VERSION ""

NS_ :

BS_:

BU_: CHUD_LS VKM_LS RCRM_LS MSM_RR_LS MSM_LR_LS CGM_LS BSM_LS VPM_LS ISRVM_LS DCAC_LS TouchPad_LS RSC_LS LVMPC_LS EOCM2B_K1_LS EOCM2A_K1_LS LCM_LS TIM_B_LS V2V_LS TCP_LS CSM_LS EOCM2B_K2_LS EOCM2A_K2_LS TIM_A_LS LVMNav_LS HFP_LS EDI_LS ARB_LS RSE_LS Dummy_LS VIS2_LS ICS_LS FCM_LS EOCM_F_LS VICM_LS AGC_LS MSM_P_LS OTIM_LS HVSM_R_LS HVSM_F_LS DVB_T_LS SBZA_R_LS PSD_R_LS PSD_L_LS UHP_Low UPA_LS STC_LS SBZA_L_LS PTM_LS ONSTAR_LS APA_LS TestTool_LS PHS_LS PDIM_LS CHM_LS RSA_LS AMP_LS HUD_LS MSM_LS HBSM_LS SCL_LS ECC_LS RadioHead_LS PEPS_LS IPC_LS AOS_LS SDM_LS TIM_LS BCM_LS

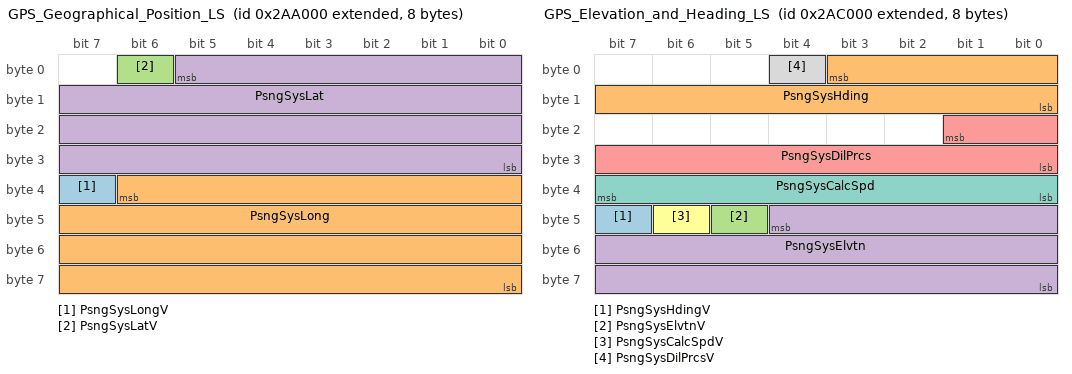
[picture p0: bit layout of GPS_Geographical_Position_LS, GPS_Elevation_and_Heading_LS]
BO_ 2150277120 GPS_Geographical_Position_LS: 8 RadioHead_LS
 SG_ PsngSysLongV : 39|1@0+ (1,0) [0|1] ""  VKM_LS,V2V_LS,VIS2_LS,RadioHead_LS,EDI_LS,VICM_LS,FCM_LS,ECC_LS,SBZA_R_LS,EOCM_F_LS,BCM_LS,SBZA_L_LS
 SG_ PsngSysLong : 38|31@0- (1,0) [-1073741824|1073741823] "ms arc"  VKM_LS,V2V_LS,VIS2_LS,RadioHead_LS,EDI_LS,VICM_LS,FCM_LS,ECC_LS,SBZA_R_LS,EOCM_F_LS,BCM_LS,SBZA_L_LS
 SG_ PsngSysLatV : 6|1@0+ (1,0) [0|1] ""  VKM_LS,V2V_LS,VIS2_LS,RadioHead_LS,VICM_LS,EDI_LS,FCM_LS,ECC_LS,SBZA_R_LS,EOCM_F_LS,BCM_LS,SBZA_L_LS
 SG_ PsngSysLat : 5|30@0- (1,0) [-536870912|536870911] "ms arc"  VKM_LS,V2V_LS,VIS2_LS,EDI_LS,RadioHead_LS,VICM_LS,FCM_LS,ECC_LS,SBZA_R_LS,EOCM_F_LS,BCM_LS,SBZA_L_LS

BO_ 2150285312 GPS_Elevation_and_Heading_LS: 8 RadioHead_LS
 SG_ PsngSysHdingV : 47|1@0+ (1,0) [0|1] ""  V2V_LS,FCM_LS,EDI_LS,RadioHead_LS,ECC_LS,SBZA_R_LS,EOCM_F_LS,BCM_LS,SBZA_L_LS
 SG_ PsngSysHding : 3|12@0+ (0.1,0) [0|409.5] "deg"  V2V_LS,FCM_LS,EDI_LS,RadioHead_LS,ECC_LS,SBZA_R_LS,EOCM_F_LS,BCM_LS,SBZA_L_LS
 SG_ PsngSysElvtnV : 45|1@0+ (1,0) [0|1] ""  BSM_LS,V2V_LS,VICM_LS,EDI_LS,RadioHead_LS,ECC_LS,SBZA_R_LS,EOCM_F_LS,BCM_LS,SBZA_L_LS
 SG_ PsngSysElvtn : 44|21@0+ (1,-100000) [-100000|1997151] "cm"  BSM_LS,V2V_LS,VICM_LS,EDI_LS,RadioHead_LS,ECC_LS,SBZA_R_LS,EOCM_F_LS,BCM_LS,SBZA_L_LS
 SG_ PsngSysDilPrcs : 17|10@0+ (0.1,0) [0|102.3] ""  V2V_LS,VICM_LS,EDI_LS,RadioHead_LS,SBZA_R_LS,EOCM_F_LS,BCM_LS,SBZA_L_LS
 SG_ PsngSysCalcSpdV : 46|1@0+ (1,0) [0|1] ""  V2V_LS,VICM_LS,EDI_LS,RadioHead_LS,EOCM_F_LS,SBZA_R_LS,SBZA_L_LS
 SG_ PsngSysCalcSpd : 39|8@0+ (1,0) [0|255] "km / h"  V2V_LS,VICM_LS,EDI_LS,RadioHead_LS,EOCM_F_LS,SBZA_R_LS,SBZA_L_LS
 SG_ PsngSysDilPrcsV : 4|1@0+ (1,0) [0|1] ""  V2V_LS,VICM_LS,EDI_LS,RadioHead_LS,SBZA_R_LS,EOCM_F_LS,BCM_LS,SBZA_L_LS

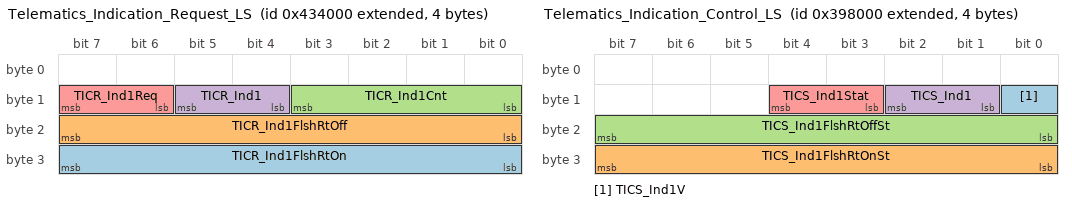
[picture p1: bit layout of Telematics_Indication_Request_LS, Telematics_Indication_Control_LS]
BO_ 2151890944 Telematics_Indication_Request_LS: 4 ONSTAR_LS
 SG_ TICR_Ind1FlshRtOn : 31|8@0+ (10,0) [0|2550] "ms"  ISRVM_LS,HBSM_LS
 SG_ TICR_Ind1FlshRtOff : 23|8@0+ (10,0) [0|2550] "ms"  ISRVM_LS,HBSM_LS
 SG_ TICR_Ind1Cnt : 11|4@0+ (1,0) [0|15] ""  ISRVM_LS,HBSM_LS
 SG_ TICR_Ind1 : 13|2@0+ (1,0) [0|3] ""  ISRVM_LS,HBSM_LS
 SG_ TICR_Ind1Req : 15|2@0+ (1,0) [0|3] ""  ISRVM_LS,HBSM_LS

BO_ 2151251968 Telematics_Indication_Control_LS: 4 HBSM_LS
 SG_ TICS_Ind1V : 8|1@0+ (1,0) [0|1] ""  TCP_LS,CGM_LS,ONSTAR_LS
 SG_ TICS_Ind1FlshRtOnSt : 31|8@0+ (10,0) [0|2550] "ms"  TCP_LS,CGM_LS,ONSTAR_LS
 SG_ TICS_Ind1FlshRtOffSt : 23|8@0+ (10,0) [0|2550] "ms"  TCP_LS,CGM_LS,ONSTAR_LS
 SG_ TICS_Ind1 : 10|2@0+ (1,0) [0|3] ""  TCP_LS,CGM_LS,ONSTAR_LS
 SG_ TICS_Ind1Stat : 12|2@0+ (1,0) [0|3] ""  TCP_LS,CGM_LS,ONSTAR_LS

BO_ 2155495424 Remote_Start_Seat_Request_LS: 1 BCM_LS
 SG_ RmStrHtdStEnRq : 1|1@0+ (1,0) [0|1] ""  CGM_LS,ECC_LS,HVSM_R_LS,MSM_P_LS,HVSM_F_LS,MSM_LS
 SG_ RmStrCldStEnReq : 0|1@0+ (1,0) [0|1] ""  CGM_LS,MSM_P_LS,HVSM_F_LS,MSM_LS,HVSM_R_LS

BO_ 2149990400 HS_Indications_Fast_LS: 8 BCM_LS
 SG_ ElcTransRngRq : 39|3@0+ (1,0) [0|7] ""  VPM_LS,CGM_LS
 SG_ TrnsfrCsRngShfSpdLmt : 47|8@0+ (1,0) [0|255] "km / h"  EOCM2B_K1_LS,EOCM2A_K1_LS,CGM_LS,IPC_LS
 SG_ TrlrBrkngVDA : 2|1@0+ (1,0) [0|1] ""  EOCM2B_K1_LS,EOCM2A_K1_LS,CGM_LS,CSM_LS,IPC_LS,RadioHead_LS
 SG_ SecAxlOperMod : 55|4@0+ (1,0) [0|15] ""  UPA_LS,APA_LS,EOCM2B_K1_LS,EOCM2A_K1_LS,CSM_LS,CGM_LS,RadioHead_LS,IPC_LS
 SG_ InstFuelConsmpRate : 51|12@0+ (0.025,0) [0|102.375] "ltrs/hr"  EOCM2B_K1_LS,EOCM2A_K1_LS,CSM_LS,CGM_LS,RadioHead_LS,IPC_LS
 SG_ MotStBltUnblIO : 36|1@0+ (1,0) [0|1] ""  EOCM2B_K1_LS,EOCM2A_K1_LS,CSM_LS,CGM_LS,RadioHead_LS,IPC_LS
 SG_ MotStBltFldIO : 35|1@0+ (1,0) [0|1] ""  EOCM2B_K1_LS,EOCM2A_K1_LS,CSM_LS,CGM_LS,RadioHead_LS,IPC_LS
 SG_ TransNtrlCntrlMdStat : 34|2@0+ (1,0) [0|3] ""  EOCM2B_K1_LS,EOCM2A_K1_LS,CSM_LS,CGM_LS,RadioHead_LS,IPC_LS
 SG_ TrlrWiringFltIO : 7|1@0+ (1,0) [0|1] ""  EOCM2B_K1_LS,EOCM2A_K1_LS,CSM_LS,CGM_LS,RadioHead_LS,IPC_LS
 SG_ TrlrCnctdIO : 14|1@0+ (1,0) [0|1] ""  EOCM2B_K1_LS,EOCM2A_K1_LS,CSM_LS,CGM_LS,EOCM_F_LS,RadioHead_LS,FCM_LS,IPC_LS
 SG_ TrlrBrkngGainSetIO : 13|1@0+ (1,0) [0|1] ""  EOCM2B_K1_LS,EOCM2A_K1_LS,CSM_LS,CGM_LS,RadioHead_LS,IPC_LS
 SG_ TrlrBrkngGainSet : 31|8@0+ (0.392157,0) [0|100.000035] "%"  EOCM2B_K1_LS,EOCM2A_K1_LS,CSM_LS,CGM_LS,RadioHead_LS,IPC_LS
 SG_ TrlrBrkngFrcOtpt : 23|8@0+ (0.392157,0) [0|100.000035] "%"  EOCM2B_K1_LS,EOCM2A_K1_LS,CSM_LS,CGM_LS,RadioHead_LS,IPC_LS
 SG_ SrvTrlrBrkngSysIO : 12|1@0+ (1,0) [0|1] ""  EOCM2B_K1_LS,EOCM2A_K1_LS,CSM_LS,CGM_LS,RadioHead_LS,IPC_LS
 SG_ ChkTrlrIO : 15|1@0+ (1,0) [0|1] ""  EOCM2B_K1_LS,EOCM2A_K1_LS,CSM_LS,CGM_LS,RadioHead_LS,IPC_LS
 SG_ ScndryAxleVDA : 11|1@0+ (1,0) [0|1] ""  EOCM2B_K1_LS,EOCM2A_K1_LS,CGM_LS,CSM_LS,RadioHead_LS,IPC_LS
 SG_ TrlrHtchSwAtv_ITBC : 32|1@0+ (1,0) [0|1] ""  EOCM2B_K1_LS,EOCM2A_K1_LS,CSM_LS,CGM_LS,RadioHead_LS,IPC_LS
 SG_ AdvHlmpsVDA : 9|1@0+ (1,0) [0|1] ""  EOCM2B_K1_LS,EOCM2A_K1_LS,CGM_LS,CSM_LS,RadioHead_LS,IPC_LS
 SG_ ABSIO : 0|1@0+ (1,0) [0|1] ""  EOCM2B_K1_LS,EOCM2A_K1_LS,CSM_LS,TCP_LS,CGM_LS,SDM_LS,RadioHead_LS,ONSTAR_LS,IPC_LS
 SG_ ACCHdwayStngIO : 5|1@0+ (1,0) [0|1] ""  EOCM2B_K1_LS,EOCM2A_K1_LS,CSM_LS,CGM_LS,RadioHead_LS,CHUD_LS,HUD_LS,IPC_LS
 SG_ StpOnBrkToRelPBIndOn : 1|1@0+ (1,0) [0|1] ""  EOCM2B_K1_LS,EOCM2A_K1_LS,CSM_LS,CGM_LS,RadioHead_LS,IPC_LS
 SG_ SADmpVDA : 10|1@0+ (1,0) [0|1] ""  EOCM2B_K1_LS,EOCM2A_K1_LS,CGM_LS,CSM_LS,RadioHead_LS,IPC_LS
 SG_ ACCDrvrSeltdSpdIO : 6|1@0+ (1,0) [0|1] ""  EOCM2B_K1_LS,EOCM2A_K1_LS,CSM_LS,CGM_LS,RadioHead_LS,CHUD_LS,HUD_LS,IPC_LS
 SG_ TreInfMonSysRstPrfmd : 4|1@0+ (1,0) [0|1] ""  EOCM2B_K1_LS,EOCM2A_K1_LS,CSM_LS,CGM_LS,RadioHead_LS,IPC_LS
 SG_ DrvThrtlOvrdIO : 3|1@0+ (1,0) [0|1] ""  EOCM2B_K1_LS,EOCM2A_K1_LS,CSM_LS,CGM_LS,RadioHead_LS,CHUD_LS,HUD_LS,IPC_LS

BO_ 2155380736 HS_Indications_SuperSlow_LS: 6 BCM_LS
 SG_ ServFuelSysTrnsfrPmpIO : 42|1@0+ (1,0) [0|1] ""  CGM_LS,IPC_LS
 SG_ ACCmCltEngd : 41|1@0+ (1,0) [0|1] ""  CGM_LS,ECC_LS
 SG_ StrAsstRdcdLvl3IO : 23|1@0+ (1,0) [0|1] ""  IPC_LS,CGM_LS
 SG_ StrAsstRdcdLvl2IO : 16|1@0+ (1,0) [0|1] ""  IPC_LS,CGM_LS
 SG_ StrngAsstRdcdIO : 22|1@0+ (1,0) [0|1] ""  EOCM2B_K1_LS,EOCM2A_K1_LS,CSM_LS,CGM_LS,RadioHead_LS,IPC_LS
 SG_ ARSFlrIO : 40|1@0+ (1,0) [0|1] ""  EOCM2B_K1_LS,EOCM2A_K1_LS,CSM_LS,CGM_LS,RadioHead_LS,IPC_LS,APA_LS
 SG_ PwrPkFnSpd : 39|8@0+ (0.392157,0) [0|100.000035] "%"  EOCM2B_K1_LS,EOCM2A_K1_LS,CSM_LS,CGM_LS,RadioHead_LS,LCM_LS,PTM_LS,ECC_LS
 SG_ PwrPckAirInTempFlt : 31|8@0+ (1,-40) [-40|215] "deg C"  EOCM2B_K1_LS,EOCM2A_K1_LS,CSM_LS,CGM_LS,RadioHead_LS,ECC_LS
 SG_ PTExPrtclFltrWrn2IO : 18|1@0+ (1,0) [0|1] ""  EOCM2B_K1_LS,EOCM2A_K1_LS,CSM_LS,CGM_LS,RadioHead_LS,IPC_LS
 SG_ EngOilHotIO : 5|1@0+ (1,0) [0|1] ""  EOCM2B_K1_LS,EOCM2A_K1_LS,CSM_LS,CGM_LS,RadioHead_LS,IPC_LS
 SG_ RrLevVDA : 3|1@0+ (1,0) [0|1] ""  EOCM2B_K1_LS,EOCM2A_K1_LS,CSM_LS,CGM_LS,RadioHead_LS,IPC_LS
 SG_ EngWtrInFlIO : 12|1@0+ (1,0) [0|1] ""  EOCM2B_K1_LS,EOCM2A_K1_LS,CSM_LS,CGM_LS,RadioHead_LS,IPC_LS
 SG_ AdvFrntLghtSysIndRq : 21|3@0+ (1,0) [0|7] ""  EOCM2B_K1_LS,EOCM2A_K1_LS,CSM_LS,CGM_LS,RadioHead_LS,EOCM_F_LS,FCM_LS,HBSM_LS,IPC_LS
 SG_ PTExPrtclFltrWrnIO : 6|1@0+ (1,0) [0|1] ""  EOCM2B_K1_LS,EOCM2A_K1_LS,CSM_LS,CGM_LS,RadioHead_LS,IPC_LS
 SG_ AirCndOffIO : 4|1@0+ (1,0) [0|1] ""  EOCM2B_K1_LS,EOCM2A_K1_LS,CSM_LS,CGM_LS,RadioHead_LS,IPC_LS
 SG_ HdLtLvlFlrIO : 2|1@0+ (1,0) [0|1] ""  EOCM2B_K1_LS,EOCM2A_K1_LS,CSM_LS,CGM_LS,RadioHead_LS,IPC_LS
 SG_ PwrStrIO : 17|1@0+ (1,0) [0|1] ""  EOCM2B_K1_LS,EOCM2A_K1_LS,CSM_LS,CGM_LS,RadioHead_LS,IPC_LS
 SG_ EngHt_StpEngIO : 15|1@0+ (1,0) [0|1] ""  EOCM2B_K1_LS,EOCM2A_K1_LS,CSM_LS,CGM_LS,RadioHead_LS,IPC_LS
 SG_ CkFlFilrCapIO : 14|1@0+ (1,0) [0|1] ""  EOCM2B_K1_LS,EOCM2A_K1_LS,CSM_LS,CGM_LS,RadioHead_LS,IPC_LS
 SG_ RdcdPwrIO : 13|1@0+ (1,0) [0|1] ""  EOCM2B_K1_LS,EOCM2A_K1_LS,CSM_LS,CGM_LS,RadioHead_LS,SDM_LS,IPC_LS
 SG_ EngOilPrsLwIO : 11|1@0+ (1,0) [0|1] ""  EOCM2B_K1_LS,EOCM2A_K1_LS,CSM_LS,CGM_LS,RadioHead_LS,IPC_LS
 SG_ EngOilLvlLwIO : 10|1@0+ (1,0) [0|1] ""  EOCM2B_K1_LS,EOCM2A_K1_LS,CSM_LS,CGM_LS,RadioHead_LS,IPC_LS
 SG_ EngOilChngIO : 9|1@0+ (1,0) [0|1] ""  EOCM2B_K1_LS,EOCM2A_K1_LS,CSM_LS,CGM_LS,RadioHead_LS,IPC_LS
 SG_ EngHotFuelEnrchmntIO : 8|1@0+ (1,0) [0|1] ""  EOCM2B_K1_LS,EOCM2A_K1_LS,CSM_LS,CGM_LS,RadioHead_LS,IPC_LS
 SG_ DslGlwPlgIO : 7|1@0+ (1,0) [0|1] ""  EOCM2B_K1_LS,EOCM2A_K1_LS,CSM_LS,CGM_LS,RadioHead_LS,IPC_LS
 SG_ SrvLevSysIO : 1|1@0+ (1,0) [0|1] ""  EOCM2B_K1_LS,EOCM2A_K1_LS,CSM_LS,CGM_LS,RadioHead_LS,IPC_LS
 SG_ VehOvrLdIndOn : 0|1@0+ (1,0) [0|1] ""  EOCM2B_K1_LS,EOCM2A_K1_LS,CSM_LS,CGM_LS,RadioHead_LS,IPC_LS

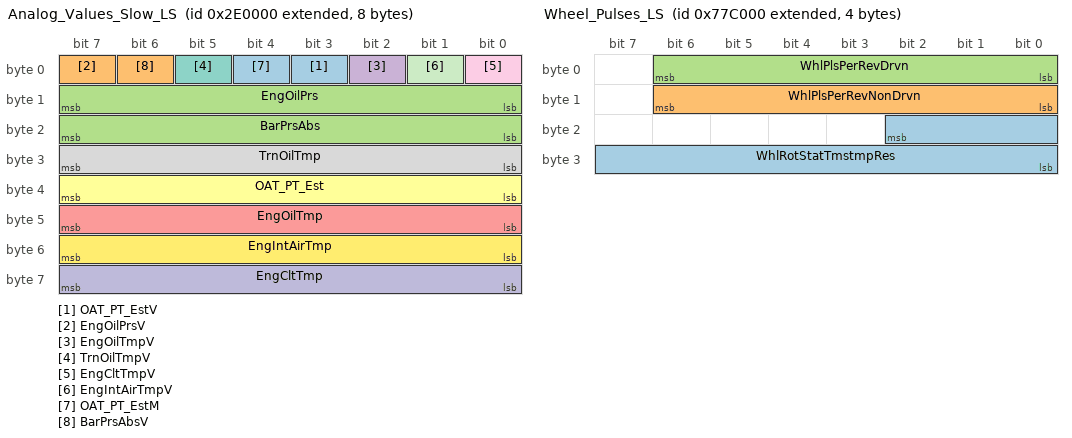
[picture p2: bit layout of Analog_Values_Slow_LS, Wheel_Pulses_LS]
BO_ 2150498304 Analog_Values_Slow_LS: 8 BCM_LS
 SG_ OAT_PT_EstV : 3|1@0+ (1,0) [0|1] ""  CSM_LS,CGM_LS,RadioHead_LS,APA_LS,STC_LS,PSD_R_LS,PSD_L_LS,PHS_LS,LCM_LS,PTM_LS,ECC_LS
 SG_ EngOilPrsV : 7|1@0+ (1,0) [0|1] ""  CSM_LS,TCP_LS,CGM_LS,RadioHead_LS,AGC_LS,ONSTAR_LS,IPC_LS
 SG_ EngOilPrs : 15|8@0+ (4,0) [0|1020] "kPa"  CSM_LS,TCP_LS,CGM_LS,RadioHead_LS,ONSTAR_LS,AGC_LS,IPC_LS
 SG_ EngOilTmpV : 2|1@0+ (1,0) [0|1] ""  CSM_LS,CGM_LS,RadioHead_LS,AGC_LS,IPC_LS
 SG_ EngOilTmp : 47|8@0+ (1,-40) [-40|215] "deg C"  CSM_LS,CGM_LS,RadioHead_LS,AGC_LS,IPC_LS
 SG_ OAT_PT_Est : 39|8@0+ (0.5,-40) [-40|87.5] "deg C"  CSM_LS,CGM_LS,RadioHead_LS,APA_LS,PSD_R_LS,PSD_L_LS,STC_LS,LCM_LS,PTM_LS,PHS_LS,ECC_LS
 SG_ TrnOilTmpV : 5|1@0+ (1,0) [0|1] ""  CSM_LS,CGM_LS,RadioHead_LS,AGC_LS,ECC_LS,IPC_LS
 SG_ TrnOilTmp : 31|8@0+ (1,-40) [-40|215] "deg C"  CSM_LS,CGM_LS,RadioHead_LS,AGC_LS,IPC_LS,ECC_LS
 SG_ EngCltTmpV : 0|1@0+ (1,0) [0|1] ""  CGM_LS,CSM_LS,RadioHead_LS,APA_LS,PHS_LS,IPC_LS,ECC_LS
 SG_ EngCltTmp : 63|8@0+ (1,-40) [-40|215] "deg C"  CGM_LS,CSM_LS,RadioHead_LS,APA_LS,ECC_LS,PHS_LS,IPC_LS
 SG_ EngIntAirTmpV : 1|1@0+ (1,0) [0|1] ""  CSM_LS,CGM_LS,RadioHead_LS,APA_LS,ECC_LS
 SG_ EngIntAirTmp : 55|8@0+ (1,-40) [-40|215] "deg C"  CSM_LS,CGM_LS,RadioHead_LS,APA_LS,ECC_LS
 SG_ OAT_PT_EstM : 4|1@0+ (1,0) [0|1] ""  CSM_LS,CGM_LS,RadioHead_LS,STC_LS,PHS_LS,ECC_LS,PSD_R_LS,PSD_L_LS,APA_LS,LCM_LS,PTM_LS
 SG_ BarPrsAbsV : 6|1@0+ (1,0) [0|1] ""  CSM_LS,CGM_LS,RadioHead_LS,IPC_LS
 SG_ BarPrsAbs : 23|8@0+ (0.5,0) [0|127.5] "kPa"  CSM_LS,CGM_LS,RadioHead_LS,IPC_LS

BO_ 2151047168 HUD_Status_LS: 1 HUD_LS
 SG_ HdUpDspAnmtStat : 3|3@0+ (1,0) [0|7] ""  EOCM2A_K2_LS,EOCM2B_K2_LS,RadioHead_LS
 SG_ HUDActv : 0|1@0+ (1,0) [0|1] ""  EOCM2A_K2_LS,EOCM2B_K2_LS,RadioHead_LS,EOCM_F_LS,BCM_LS

BO_ 2155331584 Wheel_Pulses_LS: 4 BCM_LS
 SG_ WhlRotStatTmstmpRes : 18|11@0+ (0.002,0) [0|4.094] "uSec"  CGM_LS,SDM_LS
 SG_ WhlPlsPerRevNonDrvn : 14|7@0+ (1,0) [0|127] ""  CGM_LS,SDM_LS,UPA_LS,APA_LS
 SG_ WhlPlsPerRevDrvn : 6|7@0+ (1,0) [0|127] ""  CGM_LS,SDM_LS,UPA_LS,APA_LS

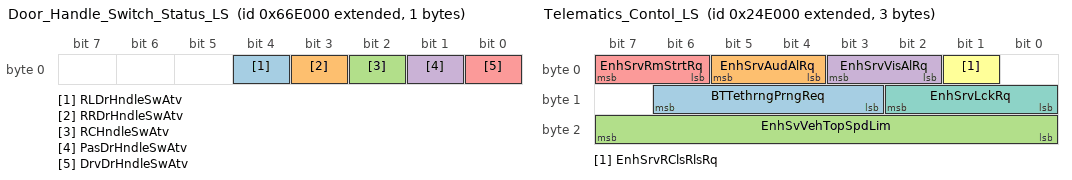
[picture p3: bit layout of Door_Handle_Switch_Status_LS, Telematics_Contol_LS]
BO_ 2154225664 Door_Handle_Switch_Status_LS: 1 PEPS_LS
 SG_ RLDrHndleSwAtv : 4|1@0+ (1,0) [0|1] ""  VKM_LS,CSM_LS,CGM_LS,RadioHead_LS,BCM_LS
 SG_ RRDrHndleSwAtv : 3|1@0+ (1,0) [0|1] ""  VKM_LS,CSM_LS,CGM_LS,RadioHead_LS,BCM_LS
 SG_ RCHndleSwAtv : 2|1@0+ (1,0) [0|1] ""  VKM_LS,CSM_LS,CGM_LS,RadioHead_LS,BCM_LS
 SG_ PasDrHndleSwAtv : 1|1@0+ (1,0) [0|1] ""  VKM_LS,CSM_LS,CGM_LS,RadioHead_LS,BCM_LS
 SG_ DrvDrHndleSwAtv : 0|1@0+ (1,0) [0|1] ""  VKM_LS,CSM_LS,CGM_LS,RadioHead_LS,BCM_LS

BO_ 2149900288 Telematics_Contol_LS: 3 ONSTAR_LS
 SG_ BTTethrngPrngReq : 14|4@0+ (1,0) [0|15] ""  RadioHead_LS
 SG_ EnhSrvAudAlRq : 5|2@0+ (1,0) [0|3] ""  BCM_LS
 SG_ EnhSvVehTopSpdLim : 23|8@0+ (2,0) [0|510] "km / h"  BCM_LS
 SG_ EnhSrvVisAlRq : 3|2@0+ (1,0) [0|3] ""  BCM_LS
 SG_ EnhSrvRmStrtRq : 7|2@0+ (1,0) [0|3] ""  BCM_LS
 SG_ EnhSrvRClsRlsRq : 1|1@0+ (1,0) [0|1] ""  LCM_LS,PTM_LS,BCM_LS
 SG_ EnhSrvLckRq : 10|3@0+ (1,0) [0|7] ""  BCM_LS

BO_ 2159001600 ODIEnumDynamicData_IPC_LS: 8 IPC_LS
 SG_ ODIEDDIPC_FUCID : 63|8@0+ (1,0) [0|255] ""  CGM_LS,TCP_LS,ONSTAR_LS,CHUD_LS,HUD_LS,RadioHead_LS
 SG_ ODIEDDIPC_Data18Value : 50|3@0+ (1,0) [0|7] ""  CGM_LS,TCP_LS,ONSTAR_LS,CHUD_LS,HUD_LS,RadioHead_LS
 SG_ ODIEDDIPC_Data17Value : 53|3@0+ (1,0) [0|7] ""  CGM_LS,TCP_LS,ONSTAR_LS,CHUD_LS,HUD_LS,RadioHead_LS
 SG_ ODIEDDIPC_Data16Value : 40|3@0+ (1,0) [0|7] ""  CGM_LS,TCP_LS,ONSTAR_LS,CHUD_LS,HUD_LS,RadioHead_LS
 SG_ ODIEDDIPC_Data15Value : 43|3@0+ (1,0) [0|7] ""  CGM_LS,TCP_LS,ONSTAR_LS,CHUD_LS,HUD_LS,RadioHead_LS
 SG_ ODIEDDIPC_Data14Value : 46|3@0+ (1,0) [0|7] ""  CGM_LS,TCP_LS,ONSTAR_LS,CHUD_LS,HUD_LS,RadioHead_LS
 SG_ ODIEDDIPC_Data13Value : 33|3@0+ (1,0) [0|7] ""  CGM_LS,TCP_LS,ONSTAR_LS,CHUD_LS,HUD_LS,RadioHead_LS
 SG_ ODIEDDIPC_Data12Value : 36|3@0+ (1,0) [0|7] ""  CGM_LS,TCP_LS,ONSTAR_LS,CHUD_LS,HUD_LS,RadioHead_LS
 SG_ ODIEDDIPC_Data11Value : 39|3@0+ (1,0) [0|7] ""  CGM_LS,TCP_LS,ONSTAR_LS,CHUD_LS,HUD_LS,RadioHead_LS
 SG_ ODIEDDIPC_Data10Value : 26|3@0+ (1,0) [0|7] ""  CGM_LS,TCP_LS,ONSTAR_LS,CHUD_LS,HUD_LS,RadioHead_LS
 SG_ ODIEDDIPC_Data9Value : 29|3@0+ (1,0) [0|7] ""  CGM_LS,TCP_LS,ONSTAR_LS,CHUD_LS,HUD_LS,RadioHead_LS
 SG_ ODIEDDIPC_Data8Value : 16|3@0+ (1,0) [0|7] ""  CGM_LS,TCP_LS,ONSTAR_LS,CHUD_LS,HUD_LS,RadioHead_LS
 SG_ ODIEDDIPC_Data7Value : 19|3@0+ (1,0) [0|7] ""  CGM_LS,TCP_LS,ONSTAR_LS,CHUD_LS,HUD_LS,RadioHead_LS
 SG_ ODIEDDIPC_Data6Value : 22|3@0+ (1,0) [0|7] ""  CGM_LS,TCP_LS,ONSTAR_LS,CHUD_LS,HUD_LS,RadioHead_LS
 SG_ ODIEDDIPC_Data5Value : 9|3@0+ (1,0) [0|7] ""  CGM_LS,TCP_LS,ONSTAR_LS,CHUD_LS,HUD_LS,RadioHead_LS
 SG_ ODIEDDIPC_Data4Value : 12|3@0+ (1,0) [0|7] ""  CGM_LS,TCP_LS,ONSTAR_LS,CHUD_LS,HUD_LS,RadioHead_LS
 SG_ ODIEDDIPC_Data3Value : 15|3@0+ (1,0) [0|7] ""  CGM_LS,TCP_LS,ONSTAR_LS,CHUD_LS,HUD_LS,RadioHead_LS
 SG_ ODIEDDIPC_Data2Value : 2|3@0+ (1,0) [0|7] ""  CGM_LS,TCP_LS,ONSTAR_LS,CHUD_LS,HUD_LS,RadioHead_LS
 SG_ ODIEDDIPC_Data1Value : 5|3@0+ (1,0) [0|7] ""  CGM_LS,TCP_LS,ONSTAR_LS,CHUD_LS,HUD_LS,RadioHead_LS

BO_ 2158993408 ODIEnumDynamicData_CntrStack_LS: 8 RadioHead_LS
 SG_ ODIEDDCS_FUCID : 63|8@0+ (1,0) [0|255] ""  CGM_LS,CHUD_LS,HUD_LS
 SG_ ODIEDDCS_Data9Value : 29|3@0+ (1,0) [0|7] ""  CGM_LS,CHUD_LS,HUD_LS
 SG_ ODIEDDCS_Data8Value : 16|3@0+ (1,0) [0|7] ""  CGM_LS,CHUD_LS,HUD_LS
 SG_ ODIEDDCS_Data7Value : 19|3@0+ (1,0) [0|7] ""  CGM_LS,CHUD_LS,HUD_LS
 SG_ ODIEDDCS_Data6Value : 22|3@0+ (1,0) [0|7] ""  CGM_LS,CHUD_LS,HUD_LS
 SG_ ODIEDDCS_Data5Value : 9|3@0+ (1,0) [0|7] ""  CGM_LS,CHUD_LS,HUD_LS
 SG_ ODIEDDCS_Data4Value : 12|3@0+ (1,0) [0|7] ""  CGM_LS,CHUD_LS,HUD_LS
 SG_ ODIEDDCS_Data3Value : 15|3@0+ (1,0) [0|7] ""  CGM_LS,CHUD_LS,HUD_LS
 SG_ ODIEDDCS_Data2Value : 2|3@0+ (1,0) [0|7] ""  CGM_LS,CHUD_LS,HUD_LS
 SG_ ODIEDDCS_Data18Value : 50|3@0+ (1,0) [0|7] ""  CGM_LS,CHUD_LS,HUD_LS
 SG_ ODIEDDCS_Data17Value : 53|3@0+ (1,0) [0|7] ""  CGM_LS,CHUD_LS,HUD_LS
 SG_ ODIEDDCS_Data16Value : 40|3@0+ (1,0) [0|7] ""  CGM_LS,CHUD_LS,HUD_LS
 SG_ ODIEDDCS_Data15Value : 43|3@0+ (1,0) [0|7] ""  CGM_LS,CHUD_LS,HUD_LS
 SG_ ODIEDDCS_Data14Value : 46|3@0+ (1,0) [0|7] ""  CGM_LS,CHUD_LS,HUD_LS
 SG_ ODIEDDCS_Data13Value : 33|3@0+ (1,0) [0|7] ""  CGM_LS,CHUD_LS,HUD_LS
 SG_ ODIEDDCS_Data12Value : 36|3@0+ (1,0) [0|7] ""  CGM_LS,CHUD_LS,HUD_LS
 SG_ ODIEDDCS_Data11Value : 39|3@0+ (1,0) [0|7] ""  CGM_LS,CHUD_LS,HUD_LS
 SG_ ODIEDDCS_Data10Value : 26|3@0+ (1,0) [0|7] ""  CGM_LS,CHUD_LS,HUD_LS
 SG_ ODIEDDCS_Data1Value : 5|3@0+ (1,0) [0|7] ""  CGM_LS,CHUD_LS,HUD_LS

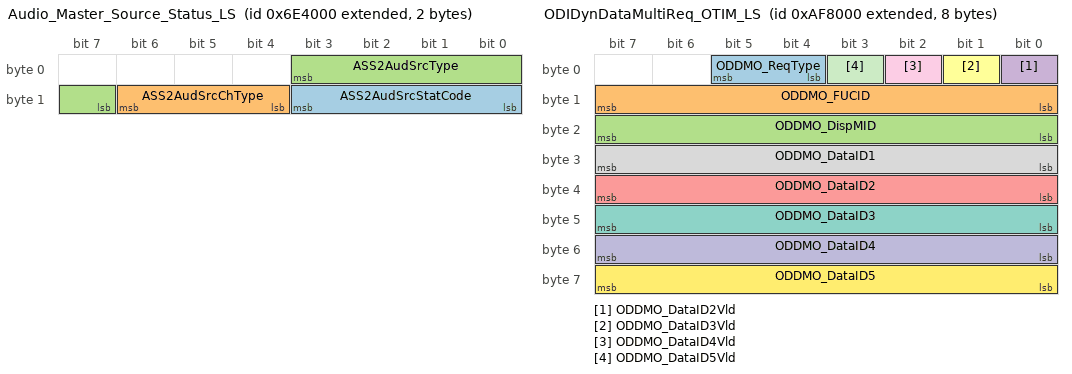
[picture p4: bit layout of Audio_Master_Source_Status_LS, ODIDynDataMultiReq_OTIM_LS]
BO_ 2154708992 Audio_Master_Source_Status_LS: 2 RadioHead_LS
 SG_ ASS2AudSrcStatCode : 11|4@0+ (1,0) [0|15] ""  ECC_LS
 SG_ ASS2AudSrcChType : 14|3@0+ (1,0) [0|7] ""  ECC_LS
 SG_ ASS2AudSrcType : 3|5@0+ (1,0) [0|31] ""  ECC_LS

BO_ 2158985216 ODIDynDataMultiReq_OTIM_LS: 8 OTIM_LS
 SG_ ODDMO_ReqType : 5|2@0+ (1,0) [0|3] ""  CGM_LS,TCP_LS,ONSTAR_LS
 SG_ ODDMO_FUCID : 15|8@0+ (1,0) [0|255] ""  CGM_LS,TCP_LS,ONSTAR_LS
 SG_ ODDMO_DispMID : 23|8@0+ (1,0) [0|255] ""  CGM_LS,TCP_LS,ONSTAR_LS
 SG_ ODDMO_DataID2Vld : 0|1@0+ (1,0) [0|1] ""  CGM_LS,TCP_LS,ONSTAR_LS
 SG_ ODDMO_DataID2 : 39|8@0+ (1,0) [0|255] ""  CGM_LS,TCP_LS,ONSTAR_LS
 SG_ ODDMO_DataID3Vld : 1|1@0+ (1,0) [0|1] ""  CGM_LS,TCP_LS,ONSTAR_LS
 SG_ ODDMO_DataID3 : 47|8@0+ (1,0) [0|255] ""  CGM_LS,TCP_LS,ONSTAR_LS
 SG_ ODDMO_DataID1 : 31|8@0+ (1,0) [0|255] ""  CGM_LS,TCP_LS,ONSTAR_LS
 SG_ ODDMO_DataID4Vld : 2|1@0+ (1,0) [0|1] ""  CGM_LS,TCP_LS,ONSTAR_LS
 SG_ ODDMO_DataID4 : 55|8@0+ (1,0) [0|255] ""  CGM_LS,TCP_LS,ONSTAR_LS
 SG_ ODDMO_DataID5Vld : 3|1@0+ (1,0) [0|1] ""  CGM_LS,TCP_LS,ONSTAR_LS
 SG_ ODDMO_DataID5 : 63|8@0+ (1,0) [0|255] ""  CGM_LS,TCP_LS,ONSTAR_LS

BO_ 2154471424 Rear_Closure_Ajar_Switch_Status: 1 BCM_LS
 SG_ RrClsrSnwLdIO : 1|1@0+ (1,0) [0|1] ""  CSM_LS,CGM_LS,RadioHead_LS,IPC_LS
 SG_ RrClosAjarSwAct : 0|1@0+ (1,0) [0|1] ""  RCRM_LS,AMP_LS,TIM_B_LS,TIM_A_LS,TIM_LS,CGM_LS,VPM_LS,ARB_LS,CSM_LS,RadioHead_LS,STC_LS,IPC_LS,ECC_LS,PEPS_LS,BCM_LS

BO_ 2159149056 ODI_TEL_2_CenterStack_LS: 8 ONSTAR_LS
 SG_ ODI_TEL2CntrStck : 7|64@0+ (1,0) [0|1.84467440737096E+019] ""  CGM_LS,CSM_LS,RadioHead_LS

BO_ 2159116288 ODI_TEL_2_AuxIP_LS: 8 ONSTAR_LS
 SG_ ODI_TEL2AxIP : 7|64@0+ (1,0) [0|1.84467440737096E+019] ""  CGM_LS,CHUD_LS,HUD_LS

BO_ 2158796800 ODIIndication_LS: 8 SBZA_L_LS
 SG_ ODII_ODIInd55 : 57|1@0+ (1,0) [0|1] ""  CSM_LS,CGM_LS,TCP_LS,ONSTAR_LS,OTIM_LS,RSC_LS,RSA_LS,RadioHead_LS,IPC_LS,CHUD_LS,HUD_LS
 SG_ ODII_ODIInd54 : 58|1@0+ (1,0) [0|1] ""  CSM_LS,CGM_LS,TCP_LS,ONSTAR_LS,OTIM_LS,RSC_LS,RSA_LS,RadioHead_LS,IPC_LS,CHUD_LS,HUD_LS
 SG_ ODII_ODIInd53 : 59|1@0+ (1,0) [0|1] ""  CSM_LS,CGM_LS,TCP_LS,ONSTAR_LS,OTIM_LS,RSC_LS,RSA_LS,RadioHead_LS,IPC_LS,CHUD_LS,HUD_LS
 SG_ ODII_ODIInd52 : 60|1@0+ (1,0) [0|1] ""  CSM_LS,CGM_LS,TCP_LS,ONSTAR_LS,OTIM_LS,RSC_LS,RSA_LS,RadioHead_LS,IPC_LS,CHUD_LS,HUD_LS
 SG_ ODII_ODIInd51 : 61|1@0+ (1,0) [0|1] ""  CSM_LS,CGM_LS,TCP_LS,ONSTAR_LS,OTIM_LS,RSC_LS,RSA_LS,RadioHead_LS,IPC_LS,CHUD_LS,HUD_LS
 SG_ ODII_ODIInd50 : 62|1@0+ (1,0) [0|1] ""  CSM_LS,CGM_LS,TCP_LS,ONSTAR_LS,OTIM_LS,RSC_LS,RSA_LS,RadioHead_LS,IPC_LS,CHUD_LS,HUD_LS
 SG_ ODII_ODIInd27 : 37|1@0+ (1,0) [0|1] ""  CSM_LS,CGM_LS,TCP_LS,ONSTAR_LS,OTIM_LS,RSC_LS,RSA_LS,RadioHead_LS,IPC_LS,CHUD_LS,HUD_LS
 SG_ ODII_ODIInd26 : 38|1@0+ (1,0) [0|1] ""  CSM_LS,CGM_LS,TCP_LS,ONSTAR_LS,OTIM_LS,RSC_LS,RSA_LS,RadioHead_LS,IPC_LS,CHUD_LS,HUD_LS
 SG_ ODII_ODIInd25 : 39|1@0+ (1,0) [0|1] ""  CSM_LS,CGM_LS,TCP_LS,ONSTAR_LS,OTIM_LS,RSC_LS,RSA_LS,RadioHead_LS,IPC_LS,CHUD_LS,HUD_LS
 SG_ ODII_ODIInd24 : 24|1@0+ (1,0) [0|1] ""  CSM_LS,CGM_LS,TCP_LS,ONSTAR_LS,OTIM_LS,RSC_LS,RSA_LS,RadioHead_LS,IPC_LS,CHUD_LS,HUD_LS
 SG_ ODII_ODIInd23 : 25|1@0+ (1,0) [0|1] ""  CSM_LS,CGM_LS,TCP_LS,ONSTAR_LS,OTIM_LS,RSC_LS,RSA_LS,RadioHead_LS,IPC_LS,CHUD_LS,HUD_LS
 SG_ ODII_ODIInd22 : 26|1@0+ (1,0) [0|1] ""  CSM_LS,CGM_LS,TCP_LS,ONSTAR_LS,OTIM_LS,RSC_LS,RSA_LS,RadioHead_LS,IPC_LS,CHUD_LS,HUD_LS
 SG_ ODII_ODIInd21 : 27|1@0+ (1,0) [0|1] ""  CSM_LS,CGM_LS,TCP_LS,ONSTAR_LS,OTIM_LS,RSC_LS,RSA_LS,RadioHead_LS,IPC_LS,CHUD_LS,HUD_LS
 SG_ ODII_ODIInd20 : 28|1@0+ (1,0) [0|1] ""  CSM_LS,CGM_LS,TCP_LS,ONSTAR_LS,OTIM_LS,RSC_LS,RSA_LS,RadioHead_LS,IPC_LS,CHUD_LS,HUD_LS
 SG_ ODII_ODIInd19 : 29|1@0+ (1,0) [0|1] ""  CSM_LS,CGM_LS,TCP_LS,ONSTAR_LS,OTIM_LS,RSC_LS,RSA_LS,RadioHead_LS,IPC_LS,CHUD_LS,HUD_LS
 SG_ ODII_ODIInd18 : 30|1@0+ (1,0) [0|1] ""  CSM_LS,CGM_LS,TCP_LS,ONSTAR_LS,OTIM_LS,RSC_LS,RSA_LS,RadioHead_LS,IPC_LS,CHUD_LS,HUD_LS
 SG_ ODII_ODIInd17 : 31|1@0+ (1,0) [0|1] ""  CSM_LS,CGM_LS,TCP_LS,ONSTAR_LS,OTIM_LS,RSC_LS,RSA_LS,RadioHead_LS,IPC_LS,CHUD_LS,HUD_LS
 SG_ ODII_ODIInd16 : 16|1@0+ (1,0) [0|1] ""  CSM_LS,CGM_LS,TCP_LS,ONSTAR_LS,OTIM_LS,RSC_LS,RSA_LS,RadioHead_LS,IPC_LS,CHUD_LS,HUD_LS
 SG_ ODII_ODIInd15 : 17|1@0+ (1,0) [0|1] ""  CSM_LS,CGM_LS,TCP_LS,ONSTAR_LS,OTIM_LS,RSC_LS,RSA_LS,RadioHead_LS,IPC_LS,CHUD_LS,HUD_LS
 SG_ ODII_ODIInd14 : 18|1@0+ (1,0) [0|1] ""  CSM_LS,CGM_LS,TCP_LS,ONSTAR_LS,OTIM_LS,RSC_LS,RSA_LS,RadioHead_LS,IPC_LS,CHUD_LS,HUD_LS
 SG_ ODII_ODIInd13 : 19|1@0+ (1,0) [0|1] ""  CSM_LS,CGM_LS,TCP_LS,ONSTAR_LS,OTIM_LS,RSC_LS,RSA_LS,RadioHead_LS,IPC_LS,CHUD_LS,HUD_LS
 SG_ ODII_ODIInd12 : 20|1@0+ (1,0) [0|1] ""  CSM_LS,CGM_LS,TCP_LS,ONSTAR_LS,OTIM_LS,RSC_LS,RSA_LS,RadioHead_LS,IPC_LS,CHUD_LS,HUD_LS
 SG_ ODII_ODIInd11 : 21|1@0+ (1,0) [0|1] ""  CSM_LS,CGM_LS,TCP_LS,ONSTAR_LS,OTIM_LS,RSC_LS,RSA_LS,RadioHead_LS,IPC_LS,CHUD_LS,HUD_LS
 SG_ ODII_ODIInd10 : 22|1@0+ (1,0) [0|1] ""  CSM_LS,CGM_LS,TCP_LS,ONSTAR_LS,OTIM_LS,RSC_LS,RSA_LS,RadioHead_LS,IPC_LS,CHUD_LS,HUD_LS
 SG_ ODII_ODIInd9 : 23|1@0+ (1,0) [0|1] ""  CSM_LS,CGM_LS,TCP_LS,ONSTAR_LS,OTIM_LS,RSC_LS,RSA_LS,RadioHead_LS,IPC_LS,CHUD_LS,HUD_LS
 SG_ ODII_ODIInd8 : 8|1@0+ (1,0) [0|1] ""  CSM_LS,CGM_LS,TCP_LS,ONSTAR_LS,OTIM_LS,RSC_LS,RSA_LS,RadioHead_LS,IPC_LS,CHUD_LS,HUD_LS
 SG_ ODII_ODIInd7 : 9|1@0+ (1,0) [0|1] ""  CSM_LS,CGM_LS,TCP_LS,ONSTAR_LS,OTIM_LS,RSC_LS,RSA_LS,RadioHead_LS,IPC_LS,CHUD_LS,HUD_LS
 SG_ ODII_ODIInd6 : 10|1@0+ (1,0) [0|1] ""  CSM_LS,CGM_LS,TCP_LS,ONSTAR_LS,OTIM_LS,RSC_LS,RSA_LS,RadioHead_LS,IPC_LS,CHUD_LS,HUD_LS
 SG_ ODII_ODIInd5 : 11|1@0+ (1,0) [0|1] ""  CSM_LS,CGM_LS,TCP_LS,ONSTAR_LS,OTIM_LS,RSC_LS,RSA_LS,RadioHead_LS,IPC_LS,CHUD_LS,HUD_LS
 SG_ ODII_ODIInd4 : 12|1@0+ (1,0) [0|1] ""  CSM_LS,CGM_LS,TCP_LS,ONSTAR_LS,OTIM_LS,RSC_LS,RSA_LS,RadioHead_LS,IPC_LS,CHUD_LS,HUD_LS
 SG_ ODII_ODIInd3 : 13|1@0+ (1,0) [0|1] ""  CSM_LS,CGM_LS,TCP_LS,ONSTAR_LS,OTIM_LS,RSC_LS,RSA_LS,RadioHead_LS,IPC_LS,CHUD_LS,HUD_LS
 SG_ ODII_ODIInd2 : 14|1@0+ (1,0) [0|1] ""  CSM_LS,CGM_LS,TCP_LS,ONSTAR_LS,OTIM_LS,RSC_LS,RSA_LS,RadioHead_LS,IPC_LS,CHUD_LS,HUD_LS
 SG_ ODII_ODIInd1 : 15|1@0+ (1,0) [0|1] ""  CSM_LS,CGM_LS,TCP_LS,ONSTAR_LS,OTIM_LS,RSC_LS,RSA_LS,RadioHead_LS,IPC_LS,CHUD_LS,HUD_LS
 SG_ ODII_ODIInd56 : 56|1@0+ (1,0) [0|1] ""  CSM_LS,CGM_LS,TCP_LS,ONSTAR_LS,OTIM_LS,RSC_LS,RSA_LS,RadioHead_LS,IPC_LS,CHUD_LS,HUD_LS
 SG_ ODII_ODIInd49 : 63|1@0+ (1,0) [0|1] ""  CSM_LS,CGM_LS,TCP_LS,ONSTAR_LS,OTIM_LS,RSC_LS,RSA_LS,RadioHead_LS,IPC_LS,CHUD_LS,HUD_LS
 SG_ ODII_ODIInd48 : 48|1@0+ (1,0) [0|1] ""  CSM_LS,CGM_LS,TCP_LS,ONSTAR_LS,OTIM_LS,RSC_LS,RSA_LS,RadioHead_LS,IPC_LS,CHUD_LS,HUD_LS
 SG_ ODII_ODIInd47 : 49|1@0+ (1,0) [0|1] ""  CSM_LS,CGM_LS,TCP_LS,ONSTAR_LS,OTIM_LS,RSC_LS,RSA_LS,RadioHead_LS,IPC_LS,CHUD_LS,HUD_LS
 SG_ ODII_ODIInd46 : 50|1@0+ (1,0) [0|1] ""  CSM_LS,CGM_LS,TCP_LS,ONSTAR_LS,OTIM_LS,RSC_LS,RSA_LS,RadioHead_LS,IPC_LS,CHUD_LS,HUD_LS
 SG_ ODII_ODIInd45 : 51|1@0+ (1,0) [0|1] ""  CSM_LS,CGM_LS,TCP_LS,ONSTAR_LS,OTIM_LS,RSC_LS,RSA_LS,RadioHead_LS,IPC_LS,CHUD_LS,HUD_LS
 SG_ ODII_ODIInd44 : 52|1@0+ (1,0) [0|1] ""  CSM_LS,CGM_LS,TCP_LS,ONSTAR_LS,OTIM_LS,RSC_LS,RSA_LS,RadioHead_LS,IPC_LS,CHUD_LS,HUD_LS
 SG_ ODII_ODIInd43 : 53|1@0+ (1,0) [0|1] ""  CSM_LS,CGM_LS,TCP_LS,ONSTAR_LS,OTIM_LS,RSC_LS,RSA_LS,RadioHead_LS,IPC_LS,CHUD_LS,HUD_LS
 SG_ ODII_ODIInd42 : 54|1@0+ (1,0) [0|1] ""  CSM_LS,CGM_LS,TCP_LS,ONSTAR_LS,OTIM_LS,RSC_LS,RSA_LS,RadioHead_LS,IPC_LS,CHUD_LS,HUD_LS
 SG_ ODII_ODIInd41 : 55|1@0+ (1,0) [0|1] ""  CSM_LS,CGM_LS,TCP_LS,ONSTAR_LS,OTIM_LS,RSC_LS,RSA_LS,RadioHead_LS,IPC_LS,CHUD_LS,HUD_LS
 SG_ ODII_ODIInd40 : 40|1@0+ (1,0) [0|1] ""  CSM_LS,CGM_LS,TCP_LS,ONSTAR_LS,OTIM_LS,RSC_LS,RSA_LS,RadioHead_LS,IPC_LS,CHUD_LS,HUD_LS
 SG_ ODII_ODIInd39 : 41|1@0+ (1,0) [0|1] ""  CSM_LS,CGM_LS,TCP_LS,ONSTAR_LS,OTIM_LS,RSC_LS,RSA_LS,RadioHead_LS,IPC_LS,CHUD_LS,HUD_LS
 SG_ ODII_ODIInd38 : 42|1@0+ (1,0) [0|1] ""  CSM_LS,CGM_LS,TCP_LS,ONSTAR_LS,OTIM_LS,RSC_LS,RSA_LS,RadioHead_LS,IPC_LS,CHUD_LS,HUD_LS
 SG_ ODII_ODIInd37 : 43|1@0+ (1,0) [0|1] ""  CSM_LS,CGM_LS,TCP_LS,ONSTAR_LS,OTIM_LS,RSC_LS,RSA_LS,RadioHead_LS,IPC_LS,CHUD_LS,HUD_LS
 SG_ ODII_ODIInd36 : 44|1@0+ (1,0) [0|1] ""  CSM_LS,CGM_LS,TCP_LS,ONSTAR_LS,OTIM_LS,RSC_LS,RSA_LS,RadioHead_LS,IPC_LS,CHUD_LS,HUD_LS
 SG_ ODII_ODIInd35 : 45|1@0+ (1,0) [0|1] ""  CSM_LS,CGM_LS,TCP_LS,ONSTAR_LS,OTIM_LS,RSC_LS,RSA_LS,RadioHead_LS,IPC_LS,CHUD_LS,HUD_LS
 SG_ ODII_ODIInd34 : 46|1@0+ (1,0) [0|1] ""  CSM_LS,CGM_LS,TCP_LS,ONSTAR_LS,OTIM_LS,RSC_LS,RSA_LS,RadioHead_LS,IPC_LS,CHUD_LS,HUD_LS
 SG_ ODII_ODIInd33 : 47|1@0+ (1,0) [0|1] ""  CSM_LS,CGM_LS,TCP_LS,ONSTAR_LS,OTIM_LS,RSC_LS,RSA_LS,RadioHead_LS,IPC_LS,CHUD_LS,HUD_LS
 SG_ ODII_ODIInd32 : 32|1@0+ (1,0) [0|1] ""  CSM_LS,CGM_LS,TCP_LS,ONSTAR_LS,OTIM_LS,RSC_LS,RSA_LS,RadioHead_LS,IPC_LS,CHUD_LS,HUD_LS
 SG_ ODII_ODIInd31 : 33|1@0+ (1,0) [0|1] ""  CSM_LS,CGM_LS,TCP_LS,ONSTAR_LS,OTIM_LS,RSC_LS,RSA_LS,RadioHead_LS,IPC_LS,CHUD_LS,HUD_LS
 SG_ ODII_ODIInd30 : 34|1@0+ (1,0) [0|1] ""  CSM_LS,CGM_LS,TCP_LS,ONSTAR_LS,OTIM_LS,RSC_LS,RSA_LS,RadioHead_LS,IPC_LS,CHUD_LS,HUD_LS
 SG_ ODII_ODIInd29 : 35|1@0+ (1,0) [0|1] ""  CSM_LS,CGM_LS,TCP_LS,ONSTAR_LS,OTIM_LS,RSC_LS,RSA_LS,RadioHead_LS,IPC_LS,CHUD_LS,HUD_LS
 SG_ ODII_ODIInd28 : 36|1@0+ (1,0) [0|1] ""  CSM_LS,CGM_LS,TCP_LS,ONSTAR_LS,OTIM_LS,RSC_LS,RSA_LS,RadioHead_LS,IPC_LS,CHUD_LS,HUD_LS
 SG_ ODII_FUCID : 7|8@0+ (1,0) [0|255] ""  CSM_LS,CGM_LS,TCP_LS,ONSTAR_LS,OTIM_LS,RSC_LS,RSA_LS,RadioHead_LS,IPC_LS,CHUD_LS,HUD_LS

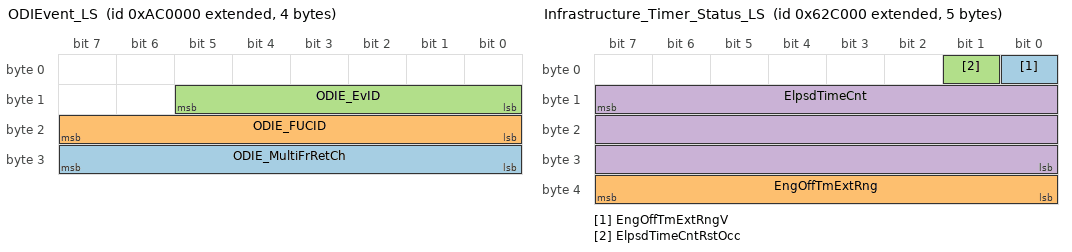
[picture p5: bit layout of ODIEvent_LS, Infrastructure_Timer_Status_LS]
BO_ 2158755840 ODIEvent_LS: 4 ONSTAR_LS
 SG_ ODIE_MultiFrRetCh : 31|8@0+ (1,0) [0|255] ""  CSM_LS,CGM_LS,OTIM_LS,RSC_LS,RSA_LS,RadioHead_LS,IPC_LS,CHUD_LS,HUD_LS
 SG_ ODIE_FUCID : 23|8@0+ (1,0) [0|255] ""  CSM_LS,CGM_LS,OTIM_LS,RSC_LS,RSA_LS,RadioHead_LS,IPC_LS,CHUD_LS,HUD_LS
 SG_ ODIE_EvID : 13|6@0+ (1,0) [0|63] ""  CSM_LS,CGM_LS,OTIM_LS,RSC_LS,RSA_LS,RadioHead_LS,IPC_LS,CHUD_LS,HUD_LS

BO_ 2159157248 ODI_CenterStack_2_TEL_LS: 8 RadioHead_LS
 SG_ ODI_CntrStck2TEL : 7|64@0+ (1,0) [0|1.84467440737096E+019] ""  CGM_LS,TCP_LS,UHP_Low,ONSTAR_LS

BO_ 2153955328 Infrastructure_Timer_Status_LS: 5 BCM_LS
 SG_ EngOffTmExtRngV : 0|1@0+ (1,0) [0|1] ""  CGM_LS,EDI_LS,APA_LS,IPC_LS,ECC_LS
 SG_ EngOffTmExtRng : 39|8@0+ (4,0) [0|1020] "min"  CGM_LS,EDI_LS,APA_LS,IPC_LS,ECC_LS
 SG_ ElpsdTimeCntRstOcc : 1|1@0+ (1,0) [0|1] ""  CGM_LS,EDI_LS,IPC_LS
 SG_ ElpsdTimeCnt : 15|24@0+ (1,0) [0|16777215] "min"  CGM_LS,EDI_LS,IPC_LS

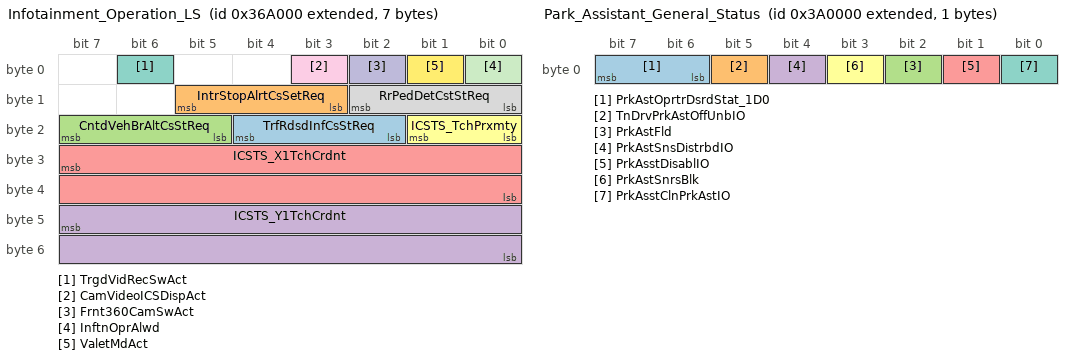
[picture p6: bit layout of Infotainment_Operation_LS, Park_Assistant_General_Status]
BO_ 2151063552 Infotainment_Operation_LS: 7 RadioHead_LS
 SG_ TrfRdsdInfCsStReq : 20|3@0+ (1,0) [0|7] ""  V2V_LS
 SG_ IntrStopAlrtCsSetReq : 13|3@0+ (1,0) [0|7] ""  V2V_LS
 SG_ CntdVehBrAltCsStReq : 23|3@0+ (1,0) [0|7] ""  V2V_LS
 SG_ ICSTS_Y1TchCrdnt : 47|16@0+ (0.001526,0) [0|100] ""  VPM_LS
 SG_ ICSTS_X1TchCrdnt : 31|16@0+ (0.001526,0) [0|100] ""  VPM_LS
 SG_ ICSTS_TchPrxmty : 17|2@0+ (1,0) [0|3] ""  VPM_LS
 SG_ TrgdVidRecSwAct : 6|1@0+ (1,0) [0|1] ""  VPM_LS
 SG_ RrPedDetCstStReq : 10|3@0+ (1,0) [0|7] ""  VPM_LS
 SG_ CamVideoICSDispAct : 3|1@0+ (1,0) [0|1] ""  VPM_LS
 SG_ Frnt360CamSwAct : 2|1@0+ (1,0) [0|1] ""  VPM_LS
 SG_ InftnOprAlwd : 0|1@0+ (1,0) [0|1] ""  LCM_LS,PTM_LS,ISRVM_LS,HBSM_LS,BCM_LS,RSC_LS,TCP_LS,OTIM_LS,UHP_Low,ONSTAR_LS,PDIM_LS,AMP_LS,LVMPC_LS
 SG_ ValetMdAct : 1|1@0+ (1,0) [0|1] ""  ICS_LS,TCP_LS,LCM_LS,PTM_LS,LVMPC_LS,ONSTAR_LS,STC_LS,BCM_LS

BO_ 2157985792 Fob_Programming_Request_LS: 1 IPC_LS
 SG_ FobProgEvntRqd : 0|1@0+ (1,0) [0|1] ""  BCM_LS

BO_ 2151284736 Park_Assistant_General_Status: 1 APA_LS
 SG_ PrkAstOprtrDsrdStat_1D0 : 7|2@0+ (1,0) [0|3] ""  CGM_LS,SBZA_R_LS,SBZA_L_LS
 SG_ TnDrvPrkAstOffUnbIO : 5|1@0+ (1,0) [0|1] ""  CGM_LS,IPC_LS
 SG_ PrkAstFld : 2|1@0+ (1,0) [0|1] ""  CSM_LS,CGM_LS,RadioHead_LS,IPC_LS
 SG_ PrkAstSnsDistrbdIO : 4|1@0+ (1,0) [0|1] ""  CSM_LS,CGM_LS,RadioHead_LS,IPC_LS
 SG_ PrkAsstDisablIO : 1|1@0+ (1,0) [0|1] ""  CSM_LS,CGM_LS,RadioHead_LS,IPC_LS
 SG_ PrkAstSnrsBlk : 3|1@0+ (1,0) [0|1] ""  CSM_LS,CGM_LS,RadioHead_LS,IPC_LS
 SG_ PrkAsstClnPrkAstIO : 0|1@0+ (1,0) [0|1] ""  CSM_LS,CGM_LS,RadioHead_LS,IPC_LS

BO_ 2159099904 ODI_DAB_2_AuxIP_LS: 8 RadioHead_LS
 SG_ ODI_DAB2AxIP : 7|64@0+ (1,0) [0|1.84467440737096E+019] ""  CGM_LS,CHUD_LS,HUD_LS

BO_ 2159067136 ODI_DAB_2_IPC_LS: 8 RadioHead_LS
 SG_ ODI_DAB2IPC : 7|64@0+ (1,0) [0|1.84467440737096E+019] ""  CGM_LS

BO_ 2159206400 ODI_AuxIP_2_IPC_LS: 8 HUD_LS
 SG_ ODI_AxIP2IPC : 7|64@0+ (1,0) [0|1.84467440737096E+019] ""  CGM_LS,IPC_LS

BO_ 2159198208 ODI_IPC_2_AuxIP_LS: 8 IPC_LS
 SG_ ODI_IPC2AxIP : 7|64@0+ (1,0) [0|1.84467440737096E+019] ""  CGM_LS,CHUD_LS,HUD_LS

BO_ 2159190016 ODI_AuxIP_2_CenterStack_LS: 8 CHUD_LS
 SG_ ODI_AxIP2CntrStck : 7|64@0+ (1,0) [0|1.84467440737096E+019] ""  CGM_LS,RadioHead_LS

BO_ 2159181824 ODI_CenterStack_2_AuxIP_LS: 8 RadioHead_LS
 SG_ ODI_CntrStck2AxIP : 7|64@0+ (1,0) [0|1.84467440737096E+019] ""  CGM_LS,CHUD_LS,HUD_LS

BO_ 2159173632 ODI_IPC_2_CenterStack_LS: 8 IPC_LS
 SG_ ODI_IPC2CntrStck : 7|64@0+ (1,0) [0|1.84467440737096E+019] ""  CGM_LS,RadioHead_LS

BO_ 2159165440 ODI_CenterStack_2_IPC_LS: 8 RadioHead_LS
 SG_ ODI_CntrStck2IPC : 7|64@0+ (1,0) [0|1.84467440737096E+019] ""  CGM_LS

BO_ 2159108096 ODI_AuxIP_2_DAB_LS: 8 CHUD_LS
 SG_ ODI_AxIP2DAB : 7|64@0+ (1,0) [0|1.84467440737096E+019] ""  CGM_LS,RadioHead_LS

BO_ 2159075328 ODI_IPC_2_DAB_LS: 8 IPC_LS
 SG_ ODI_IPC2DAB : 7|64@0+ (1,0) [0|1.84467440737096E+019] ""  CGM_LS,RadioHead_LS

BO_ 2151718912 Chime_Active: 1 IPC_LS
 SG_ ChmVolSt : 2|2@0+ (1,0) [0|3] ""  EOCM2A_K2_LS,EOCM2B_K2_LS,V2V_LS,RadioHead_LS
 SG_ ChmAct : 0|1@0+ (1,0) [0|1] ""  VPM_LS,FCM_LS,TCP_LS,EOCM2A_K2_LS,EOCM2B_K2_LS,V2V_LS,PSD_R_LS,PSD_L_LS,BSM_LS,VICM_LS,EOCM_F_LS,CHUD_LS,HUD_LS,ONSTAR_LS,RadioHead_LS,UPA_LS,TIM_B_LS,TIM_A_LS,TIM_LS,LCM_LS,PTM_LS,BCM_LS,SDM_LS,APA_LS

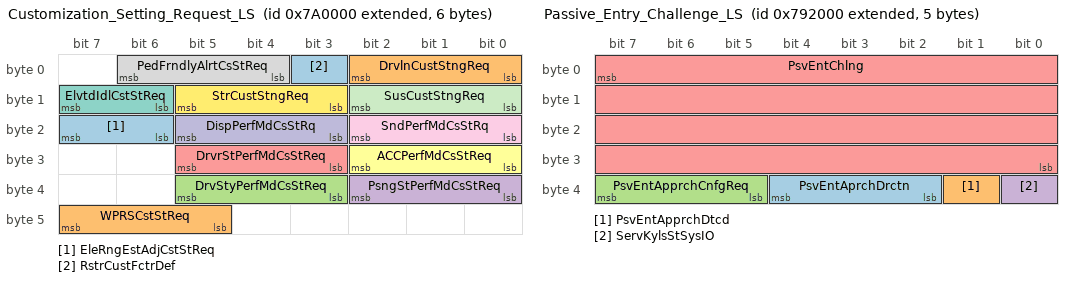
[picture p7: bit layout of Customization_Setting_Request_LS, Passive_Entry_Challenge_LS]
BO_ 2155479040 Customization_Setting_Request_LS: 6 RadioHead_LS
 SG_ EleRngEstAdjCstStReq : 23|2@0+ (1,0) [0|3] ""  VICM_LS
 SG_ WPRSCstStReq : 47|3@0+ (1,0) [0|7] ""  VICM_LS
 SG_ DrvStyPerfMdCsStReq : 37|3@0+ (1,0) [0|7] ""  BCM_LS
 SG_ PsngStPerfMdCsStReq : 34|3@0+ (1,0) [0|7] ""  BCM_LS
 SG_ DrvrStPerfMdCsStReq : 29|3@0+ (1,0) [0|7] ""  BCM_LS
 SG_ ACCPerfMdCsStReq : 26|3@0+ (1,0) [0|7] ""  BCM_LS
 SG_ ElvtdIdlCstStReq : 15|2@0+ (1,0) [0|3] ""  BCM_LS
 SG_ PedFrndlyAlrtCsStReq : 6|3@0+ (1,0) [0|7] ""  BCM_LS
 SG_ SndPerfMdCsStRq : 18|3@0+ (1,0) [0|7] ""  BCM_LS
 SG_ DispPerfMdCsStRq : 21|3@0+ (1,0) [0|7] ""  BCM_LS
 SG_ SusCustStngReq : 10|3@0+ (1,0) [0|7] ""  BCM_LS
 SG_ StrCustStngReq : 13|3@0+ (1,0) [0|7] ""  BCM_LS
 SG_ RstrCustFctrDef : 3|1@0+ (1,0) [0|1] ""  VPM_LS,VIS2_LS,FCM_LS,HBSM_LS,BSM_LS,VICM_LS,BCM_LS
 SG_ DrvlnCustStngReq : 2|3@0+ (1,0) [0|7] ""  BCM_LS

BO_ 2151383040 Reset_TP_request_LS: 1 IPC_LS
 SG_ TreInfMonSysRstReq : 0|1@0+ (1,0) [0|1] ""  BCM_LS

BO_ 1350 UUDT_Resp_From_ICS_LS: 8 ICS_LS
 SG_ DgnInf_LS546 : 7|64@0+ (1,0) [0|1.84467440737096E+019] ""  CGM_LS,CSM_LS,TCP_LS,ONSTAR_LS,TestTool_LS

BO_ 1606 USDT_Resp_From_ICS_LS: 8 ICS_LS
 SG_ DgnInf : 7|64@0+ (1,0) [0|1.84467440737096E+019] ""  CGM_LS,CSM_LS,TCP_LS,ONSTAR_LS,TestTool_LS

BO_ 1355 UUDT_Resp_From_FCM_LS: 8 EOCM_F_LS
 SG_ DgnInf_LS54B : 7|64@0+ (1,0) [0|1.84467440737096E+019] ""  CSM_LS,CGM_LS,TCP_LS,ONSTAR_LS,TestTool_LS

BO_ 1611 USDT_Resp_From_FCM_LS: 8 EOCM_F_LS
 SG_ DgnInf : 7|64@0+ (1,0) [0|1.84467440737096E+019] ""  CSM_LS,CGM_LS,TCP_LS,ONSTAR_LS,TestTool_LS

BO_ 1374 UUDT_Resp_From_AHS_LS: 8 PHS_LS
 SG_ DgnInf_LS55E : 7|64@0+ (1,0) [0|1.84467440737096E+019] ""  CSM_LS,CGM_LS,TCP_LS,ONSTAR_LS,TestTool_LS

BO_ 1630 USDT_Resp_From_AHS_LS: 8 PHS_LS
 SG_ DgnInf : 7|64@0+ (1,0) [0|1.84467440737096E+019] ""  CSM_LS,CGM_LS,TCP_LS,ONSTAR_LS,TestTool_LS

BO_ 2155421696 Passive_Entry_Challenge_LS: 5 PEPS_LS
 SG_ PsvEntAprchDrctn : 36|3@0+ (1,0) [0|7] ""  CGM_LS,BCM_LS
 SG_ PsvEntApprchDtcd : 33|1@0+ (1,0) [0|1] ""  CGM_LS,BCM_LS
 SG_ PsvEntApprchCnfgReq : 39|3@0+ (1,0) [0|7] ""  CGM_LS,BCM_LS
 SG_ ServKylsStSysIO : 32|1@0+ (1,0) [0|1] ""  CGM_LS,IPC_LS
 SG_ PsvEntChlng : 7|32@0+ (1,0) [0|4294967295] "passwrd"  TCP_LS,ONSTAR_LS,CSM_LS,RadioHead_LS,CGM_LS,BCM_LS

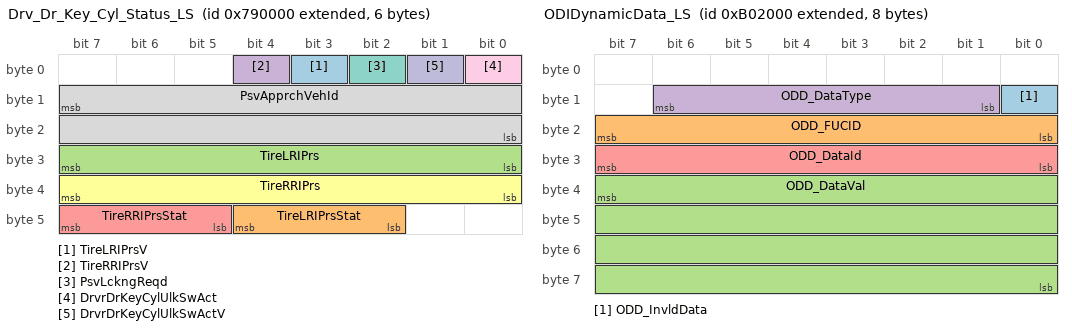
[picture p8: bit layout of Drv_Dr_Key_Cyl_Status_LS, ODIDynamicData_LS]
BO_ 2155413504 Drv_Dr_Key_Cyl_Status_LS: 6 BCM_LS
 SG_ TireLRIPrsV : 3|1@0+ (1,0) [0|1] ""  CGM_LS,V2V_LS,TCP_LS,ONSTAR_LS,IPC_LS
 SG_ TireLRIPrsStat : 44|3@0+ (1,0) [0|7] ""  CGM_LS,TCP_LS,ONSTAR_LS,IPC_LS
 SG_ TireLRIPrs : 31|8@0+ (4,0) [0|1020] "kPaG"  CGM_LS,V2V_LS,TCP_LS,ONSTAR_LS,IPC_LS
 SG_ TireRRIPrsV : 4|1@0+ (1,0) [0|1] ""  CGM_LS,V2V_LS,TCP_LS,ONSTAR_LS,IPC_LS
 SG_ TireRRIPrsStat : 47|3@0+ (1,0) [0|7] ""  CGM_LS,TCP_LS,ONSTAR_LS,IPC_LS
 SG_ TireRRIPrs : 39|8@0+ (4,0) [0|1020] "kPaG"  CGM_LS,V2V_LS,TCP_LS,ONSTAR_LS,IPC_LS
 SG_ PsvLckngReqd : 2|1@0+ (1,0) [0|1] ""  PEPS_LS,CGM_LS
 SG_ PsvApprchVehId : 15|16@0+ (1,0) [0|65535] ""  CGM_LS,PEPS_LS
 SG_ DrvrDrKeyCylUlkSwAct : 0|1@0+ (1,0) [0|1] ""  CSM_LS,CGM_LS,RadioHead_LS,PEPS_LS
 SG_ DrvrDrKeyCylUlkSwActV : 1|1@0+ (1,0) [0|1] ""  CSM_LS,CGM_LS,RadioHead_LS,PEPS_LS

BO_ 2159026176 ODIDynamicData_LS: 8 ONSTAR_LS
 SG_ ODD_InvldData : 8|1@0+ (1,0) [0|1] ""  CSM_LS,CGM_LS,OTIM_LS,RSC_LS,RSA_LS,IPC_LS,CHUD_LS,HUD_LS,RadioHead_LS
 SG_ ODD_FUCID : 23|8@0+ (1,0) [0|255] ""  CSM_LS,CGM_LS,OTIM_LS,RSC_LS,RSA_LS,IPC_LS,CHUD_LS,HUD_LS,RadioHead_LS
 SG_ ODD_DataVal : 39|32@0+ (1,0) [0|4294967295] ""  CSM_LS,CGM_LS,OTIM_LS,RSC_LS,RSA_LS,IPC_LS,CHUD_LS,HUD_LS,RadioHead_LS
 SG_ ODD_DataType : 14|6@0+ (1,0) [0|63] ""  CSM_LS,CGM_LS,OTIM_LS,RSC_LS,RSA_LS,IPC_LS,CHUD_LS,HUD_LS,RadioHead_LS
 SG_ ODD_DataId : 31|8@0+ (1,0) [0|255] ""  CSM_LS,CGM_LS,OTIM_LS,RSC_LS,RSA_LS,IPC_LS,CHUD_LS,HUD_LS,RadioHead_LS

BO_TX_BU_ 2150277120 : CGM_LS,TCP_LS,CSM_LS,ONSTAR_LS,RadioHead_LS;
BO_TX_BU_ 2150285312 : CGM_LS,TCP_LS,CSM_LS,ONSTAR_LS,RadioHead_LS;
BO_TX_BU_ 2151890944 : TCP_LS,CGM_LS,ONSTAR_LS;
BO_TX_BU_ 2151251968 : ISRVM_LS,HBSM_LS;
BO_TX_BU_ 2151047168 : CGM_LS,IPC_LS,CHUD_LS,HUD_LS;
BO_TX_BU_ 2149900288 : TCP_LS,CGM_LS,ONSTAR_LS;
BO_TX_BU_ 2158993408 : CSM_LS,RadioHead_LS;
BO_TX_BU_ 2154708992 : CGM_LS,RadioHead_LS;
BO_TX_BU_ 2154471424 : LCM_LS,PTM_LS,BCM_LS;
BO_TX_BU_ 2159149056 : TCP_LS,UHP_Low,ONSTAR_LS;
BO_TX_BU_ 2159116288 : RadioHead_LS,UHP_Low,ONSTAR_LS;
BO_TX_BU_ 2158796800 : TCP_LS,EOCM2A_K2_LS,SBZA_L_LS,VIS2_LS,FCM_LS,PDIM_LS,EOCM_F_LS,UPA_LS,MSM_P_LS,MSM_LS,BCM_LS,ECC_LS,UHP_Low,ONSTAR_LS,APA_LS;
BO_TX_BU_ 2158755840 : BCM_LS,TCP_LS,VIS2_LS,FCM_LS,PDIM_LS,ECC_LS,APA_LS,UHP_Low,ONSTAR_LS;
BO_TX_BU_ 2159157248 : CSM_LS,RadioHead_LS;
BO_TX_BU_ 2151063552 : CGM_LS,CSM_LS,RadioHead_LS;
BO_TX_BU_ 2157985792 : CGM_LS,IPC_LS;
BO_TX_BU_ 2151284736 : EOCM2A_K2_LS,EOCM_F_LS,UPA_LS,APA_LS;
BO_TX_BU_ 2159067136 : CSM_LS,RadioHead_LS;
BO_TX_BU_ 2159206400 : CHUD_LS,HUD_LS;
BO_TX_BU_ 2159190016 : CHUD_LS,HUD_LS;
BO_TX_BU_ 2159165440 : CSM_LS,RadioHead_LS;
BO_TX_BU_ 2159108096 : CHUD_LS,HUD_LS;
BO_TX_BU_ 2151718912 : IPC_LS,CGM_LS,CHM_LS,AMP_LS,RadioHead_LS;
BO_TX_BU_ 2155479040 : CGM_LS,CSM_LS,RadioHead_LS;
BO_TX_BU_ 2151383040 : TCP_LS,CGM_LS,ONSTAR_LS,IPC_LS;
BO_TX_BU_ 1350 : CGM_LS,ICS_LS;
BO_TX_BU_ 1606 : CGM_LS,ICS_LS;
BO_TX_BU_ 1355 : EOCM2A_K2_LS,FCM_LS,EOCM_F_LS;
BO_TX_BU_ 1611 : EOCM2A_K2_LS,FCM_LS,EOCM_F_LS;
BO_TX_BU_ 1374 : EOCM2B_K2_LS,PHS_LS;
BO_TX_BU_ 1630 : EOCM2B_K2_LS,PHS_LS;
BO_TX_BU_ 2159026176 : BCM_LS,TCP_LS,VIS2_LS,FCM_LS,PDIM_LS,ECC_LS,APA_LS,UHP_Low,ONSTAR_LS;
CM_ SG_ 2150277120 PsngSysLong "The units of the data are milli-arcseconds (1/3,600,000 of a degree).  The actual 'usable' range of this data is somewhat less than the encoded range (+/- 648,000,000, corresponding to +/- 180 degrees)";
CM_ SG_ 2150277120 PsngSysLat "The units of the data are milli-arcseconds (1/3,600,000 of a degree).  The actual 'usable' range of this data is somewhat less than the encoded range (+/- 324,000,000, corresponding to +/- 90 degrees)";
CM_ SG_ 2150285312 PsngSysHding "The 'usable' range is somewhat less than the encoded range (0.0 to 359.9 degrees).  0.0 degrees represents North, 90.0 degrees represents East.";
CM_ SG_ 2159001600 ODIEDDIPC_FUCID "ODI - Primary ID of Functional Unit in FU Database";
CM_ SG_ 2159001600 ODIEDDIPC_Data18Value "ODI";
CM_ SG_ 2159001600 ODIEDDIPC_Data17Value "ODI";
CM_ SG_ 2159001600 ODIEDDIPC_Data16Value "ODI";
CM_ SG_ 2159001600 ODIEDDIPC_Data15Value "ODI";
CM_ SG_ 2159001600 ODIEDDIPC_Data14Value "ODI";
CM_ SG_ 2159001600 ODIEDDIPC_Data13Value "ODI";
CM_ SG_ 2159001600 ODIEDDIPC_Data12Value "ODI";
CM_ SG_ 2159001600 ODIEDDIPC_Data11Value "ODI";
CM_ SG_ 2159001600 ODIEDDIPC_Data10Value "ODI";
CM_ SG_ 2159001600 ODIEDDIPC_Data9Value "ODI";
CM_ SG_ 2159001600 ODIEDDIPC_Data8Value "ODI";
CM_ SG_ 2159001600 ODIEDDIPC_Data7Value "ODI";
CM_ SG_ 2159001600 ODIEDDIPC_Data6Value "ODI";
CM_ SG_ 2159001600 ODIEDDIPC_Data5Value "ODI";
CM_ SG_ 2159001600 ODIEDDIPC_Data4Value "ODI";
CM_ SG_ 2159001600 ODIEDDIPC_Data3Value "ODI";
CM_ SG_ 2159001600 ODIEDDIPC_Data2Value "ODI";
CM_ SG_ 2159001600 ODIEDDIPC_Data1Value "ODI";
CM_ SG_ 2158993408 ODIEDDCS_FUCID "ODI - Primary ID of Functional Unit in FU Database";
CM_ SG_ 2158993408 ODIEDDCS_Data9Value "ODI";
CM_ SG_ 2158993408 ODIEDDCS_Data8Value "ODI";
CM_ SG_ 2158993408 ODIEDDCS_Data7Value "ODI";
CM_ SG_ 2158993408 ODIEDDCS_Data6Value "ODI";
CM_ SG_ 2158993408 ODIEDDCS_Data5Value "ODI";
CM_ SG_ 2158993408 ODIEDDCS_Data4Value "ODI";
CM_ SG_ 2158993408 ODIEDDCS_Data3Value "ODI";
CM_ SG_ 2158993408 ODIEDDCS_Data2Value "ODI";
CM_ SG_ 2158993408 ODIEDDCS_Data18Value "ODI";
CM_ SG_ 2158993408 ODIEDDCS_Data17Value "ODI";
CM_ SG_ 2158993408 ODIEDDCS_Data16Value "ODI";
CM_ SG_ 2158993408 ODIEDDCS_Data15Value "ODI";
CM_ SG_ 2158993408 ODIEDDCS_Data14Value "ODI";
CM_ SG_ 2158993408 ODIEDDCS_Data13Value "ODI";
CM_ SG_ 2158993408 ODIEDDCS_Data12Value "ODI";
CM_ SG_ 2158993408 ODIEDDCS_Data11Value "ODI";
CM_ SG_ 2158993408 ODIEDDCS_Data10Value "ODI";
CM_ SG_ 2158993408 ODIEDDCS_Data1Value "ODI";
CM_ SG_ 2158985216 ODDMO_ReqType "ODI - Type of Request";
CM_ SG_ 2158985216 ODDMO_FUCID "ODI - Primary ID of Functional Unit in FU Database";
CM_ SG_ 2158985216 ODDMO_DispMID "ODI - ID that identifies the display requesting the data.  See detailed requirements in ODI GMLAN Protocol.";
CM_ SG_ 2158985216 ODDMO_DataID2Vld "ODI -DataIDTwo is being requested as a valid ID.";
CM_ SG_ 2158985216 ODDMO_DataID2 "ODI - ID for the second requested data parameter as defined in the FUDatabase";
CM_ SG_ 2158985216 ODDMO_DataID3Vld "ODI -DataIDThree is being requested as a valid ID.";
CM_ SG_ 2158985216 ODDMO_DataID3 "ODI - ID for the third requested data parameter as defined in the FUDatabase";
CM_ SG_ 2158985216 ODDMO_DataID1 "ODI - ID for the first requested data parameter as defined in the FUDatabase";
CM_ SG_ 2158985216 ODDMO_DataID4Vld "ODI -DataIDFour is being requested as a valid ID.";
CM_ SG_ 2158985216 ODDMO_DataID4 "ODI - ID for the fourth requested data parameter as defined in the FUDatabase";
CM_ SG_ 2158985216 ODDMO_DataID5Vld "ODI -DataIDFive is being requested as a valid ID.";
CM_ SG_ 2158985216 ODDMO_DataID5 "ODI - ID for the fifth requested data parameter as defined in the FUDatabase";
CM_ BO_ 2154471424 "LAP: varför mappad i två olika VD'n?";
CM_ SG_ 2158796800 ODII_FUCID "ODI - Primary ID of Functional Unit in FU Database";
CM_ SG_ 2158755840 ODIE_FUCID "ODI - Primary ID of Functional Unit in FU Database";
CM_ SG_ 2158755840 ODIE_EvID "EventID within FUClass";
CM_ SG_ 2151284736 PrkAstSnsDistrbdIO "This signal turns on a warning that tells the driver that the Parking Assist is receiving ultrasonic input that essentially makes it blind.  The system is still enabled, there is no failure in the system, but it can't perform the function.";
CM_ SG_ 2159026176 ODD_InvldData "ODI";
CM_ SG_ 2159026176 ODD_FUCID "ODI - Primary ID of Functional Unit in FU Database";
CM_ SG_ 2159026176 ODD_DataVal "ODI";
CM_ SG_ 2159026176 ODD_DataType "ODI";
CM_ SG_ 2159026176 ODD_DataId "ODI-Data Id for the dynamic list";
BA_DEF_ SG_  "VNSigPrimaryTriggering" ENUM  "No","Yes","DLCLS","DLCHS","DLCCE","DLCFO";
BA_DEF_ SG_  "VNSigRemoteDiagnostics" ENUM  "No","Yes","DLCLS","DLCHS","DLCCE","DLCFO";
BA_DEF_ SG_  "VNSigInfotainment" ENUM  "No","Yes","DLCLS","DLCHS","DLCCE","DLCFO";
BA_DEF_ SG_  "VNSigParkedVehicle" ENUM  "No","Yes","DLCLS","DLCHS","DLCCE","DLCFO";
BA_DEF_ SG_  "VNSigIntermediate" ENUM  "No","Yes","DLCLS","DLCHS","DLCCE","DLCFO";
BA_DEF_ SG_  "VNSigUnused_4" ENUM  "No","Yes","DLCLS","DLCHS","DLCCE","DLCFO";
BA_DEF_ SG_  "SignalType" STRING ;
BA_DEF_ SG_  "PacketOrder" INT 0 65535;
BA_DEF_ SG_  "SignalLongName" STRING ;
BA_DEF_ SG_  "GenSigStartValue" INT 0 65535;
BA_DEF_ SG_  "VNSigDiagnostic" ENUM  "No","Yes","DLCLS","DLCHS","DLCCE","DLCFO";
BA_DEF_ SG_  "VNSigAllNodes" ENUM  "No","Yes","DLCLS","DLCHS","DLCCE","DLCFO";
BA_DEF_ SG_  "GenSigDeltaValue" INT 0 0;
BA_DEF_ SG_  "GenSigInactiveValue" INT 0 0;
BA_DEF_ SG_  "GenSigSendType" ENUM  "not used","not used","not used","not used","not used","not used","not used","NoSigSendType","not used","not used","OnAnyChange","OnChangeIfActive","OnDelta","DLCLS","DLCHS","DLCCE","DLCFO";
BA_DEF_ SG_  "GenSigSendOnInit" ENUM  "Not Initialized","Application","Handler","DLCLS","DLCHS","DLCCE","DLCFO";
BA_DEF_ BO_  "AppGenMsgCycleTime" INT 0 0;
BA_DEF_ BO_  "TpTxIndex" INT 0 99;
BA_DEF_ BO_  "GenMsgILSupport" ENUM  "No","Yes","DLCLS","DLCHS","DLCCE","DLCFO";
BA_DEF_ BO_  "TpApplType" STRING ;
BA_DEF_ BO_  "Prio" INT 0 7;
BA_DEF_ BO_  "MessageSubnet" ENUM  "LS","MS","HS","CE","PE","HV","FO","S1","HE","LE","HE2","DLCLS","DLCHS","DLCCE","DLCFO";
BA_DEF_ BO_  "GenMsgMandatoryToSupervision" ENUM  "No","Yes","DLCLS","DLCHS","DLCCE","DLCFO";
BA_DEF_ BO_  "DiagState" ENUM  "No","Yes","DLCLS","DLCHS","DLCCE","DLCFO";
BA_DEF_ BO_  "GenMsgStartDelayTime" INT 0 100000;
BA_DEF_ BO_  "GenMsgDelayTime" INT 0 100000;
BA_DEF_ BO_  "GenMsgCycleTime" INT 0 100000;
BA_DEF_ BO_  "GenMsgSendType" ENUM  "cyclicX","spontanX","cyclicIfActiveX","spontanWithDelay","cyclicAndSpontanX","cyclicAndSpontanWithDelay","spontanWithRepitition","cyclicIfActiveAndSpontanWD","DLCLS","DLCHS","DLCCE","DLCFO";
BA_DEF_ BO_  "DiagResponse" ENUM  "No","Yes","DLCLS","DLCHS","DLCCE","DLCFO";
BA_DEF_ BO_  "DiagRequest" ENUM  "No","Yes","DLCLS","DLCHS","DLCCE","DLCFO";
BA_DEF_ BO_  "NmMessage" ENUM  "No","Yes","DLCLS","DLCHS","DLCCE","DLCFO";
BA_DEF_REL_ BU_SG_REL_  "GenSigSuprvRespComment" STRING ;
BA_DEF_REL_ BU_SG_REL_  "GenSigVBitResp" ENUM  "No","Yes","DLCLS","DLCHS","DLCCE","DLCFO";
BA_DEF_REL_ BU_SG_REL_  "GenSigVBitRespComment" STRING ;
BA_DEF_REL_ BU_SG_REL_  "GenSigVDAFailComment" STRING ;
BA_DEF_REL_ BU_SG_REL_  "GenSigVDAFailResp" ENUM  "No","Yes","DLCLS","DLCHS","DLCCE","DLCFO";
BA_DEF_REL_ BU_SG_REL_  "GenSigRxStartValue" STRING ;
BA_DEF_REL_ BU_SG_REL_  "GenSigSuprvRespSubValue" INT 0 65535;
BA_DEF_REL_ BU_SG_REL_  "GenSigSuprvResp" ENUM  "None","Notify App","Substitute Default","DLCLS","DLCHS","DLCCE","DLCFO";
BA_DEF_REL_ BU_SG_REL_  "GenSigTimeoutMsg" HEX -2147483648 268435455;
BA_DEF_REL_ BU_SG_REL_  "GenSigTimeoutTime" INT 0 15000;
BA_DEF_DEF_  "VNSigPrimaryTriggering" "No";
BA_DEF_DEF_  "VNSigRemoteDiagnostics" "No";
BA_DEF_DEF_  "VNSigInfotainment" "No";
BA_DEF_DEF_  "VNSigParkedVehicle" "No";
BA_DEF_DEF_  "VNSigIntermediate" "No";
BA_DEF_DEF_  "VNSigUnused_4" "No";
BA_DEF_DEF_  "SignalType" "";
BA_DEF_DEF_  "PacketOrder" 0;
BA_DEF_DEF_  "SignalLongName" "";
BA_DEF_DEF_  "GenSigStartValue" 0;
BA_DEF_DEF_  "VNSigDiagnostic" "No";
BA_DEF_DEF_  "VNSigAllNodes" "No";
BA_DEF_DEF_  "GenSigDeltaValue" 0;
BA_DEF_DEF_  "GenSigInactiveValue" 0;
BA_DEF_DEF_  "GenSigSendType" "NoSigSendType";
BA_DEF_DEF_  "GenSigSendOnInit" "Not Initialized";
BA_DEF_DEF_  "AppGenMsgCycleTime" 0;
BA_DEF_DEF_  "TpTxIndex" 0;
BA_DEF_DEF_  "GenMsgILSupport" "Yes";
BA_DEF_DEF_  "TpApplType" "";
BA_DEF_DEF_  "Prio" 4;
BA_DEF_DEF_  "MessageSubnet" "FO";
BA_DEF_DEF_  "GenMsgMandatoryToSupervision" "No";
BA_DEF_DEF_  "DiagState" "No";
BA_DEF_DEF_  "GenMsgStartDelayTime" 0;
BA_DEF_DEF_  "GenMsgDelayTime" 0;
BA_DEF_DEF_  "GenMsgCycleTime" 0;
BA_DEF_DEF_  "GenMsgSendType" "spontanX";
BA_DEF_DEF_  "DiagResponse" "No";
BA_DEF_DEF_  "DiagRequest" "No";
BA_DEF_DEF_  "NmMessage" "No";
BA_DEF_DEF_REL_ "GenSigSuprvRespComment" "";
BA_DEF_DEF_REL_ "GenSigVBitResp" "No";
BA_DEF_DEF_REL_ "GenSigVBitRespComment" "";
BA_DEF_DEF_REL_ "GenSigVDAFailComment" "";
BA_DEF_DEF_REL_ "GenSigVDAFailResp" "No";
BA_DEF_DEF_REL_ "GenSigRxStartValue" "";
BA_DEF_DEF_REL_ "GenSigSuprvRespSubValue" 0;
BA_DEF_DEF_REL_ "GenSigSuprvResp" "None";
BA_DEF_DEF_REL_ "GenSigTimeoutMsg" 0;
BA_DEF_DEF_REL_ "GenSigTimeoutTime" 0;
BA_ "MessageSubnet" BO_ 2150277120 0;
BA_ "GenMsgDelayTime" BO_ 2150277120 100;
BA_ "MessageSubnet" BO_ 2150285312 0;
BA_ "GenMsgDelayTime" BO_ 2150285312 100;
BA_ "MessageSubnet" BO_ 2151890944 0;
BA_ "GenMsgDelayTime" BO_ 2151890944 100;
BA_ "GenMsgCycleTime" BO_ 2151890944 1500;
BA_ "GenMsgSendType" BO_ 2151890944 0;
BA_ "MessageSubnet" BO_ 2151251968 0;
BA_ "GenMsgDelayTime" BO_ 2151251968 250;
BA_ "GenMsgCycleTime" BO_ 2151251968 1000;
BA_ "GenMsgSendType" BO_ 2151251968 0;
BA_ "MessageSubnet" BO_ 2155495424 0;
BA_ "GenMsgDelayTime" BO_ 2155495424 500;
BA_ "MessageSubnet" BO_ 2149990400 0;
BA_ "GenMsgStartDelayTime" BO_ 2149990400 200;
BA_ "GenMsgCycleTime" BO_ 2149990400 100;
BA_ "GenMsgSendType" BO_ 2149990400 0;
BA_ "MessageSubnet" BO_ 2155380736 0;
BA_ "GenMsgStartDelayTime" BO_ 2155380736 180;
BA_ "GenMsgDelayTime" BO_ 2155380736 10;
BA_ "GenMsgCycleTime" BO_ 2155380736 500;
BA_ "GenMsgSendType" BO_ 2155380736 0;
BA_ "MessageSubnet" BO_ 2150498304 0;
BA_ "GenMsgStartDelayTime" BO_ 2150498304 140;
BA_ "GenMsgCycleTime" BO_ 2150498304 1000;
BA_ "GenMsgSendType" BO_ 2150498304 0;
BA_ "MessageSubnet" BO_ 2151047168 0;
BA_ "GenMsgDelayTime" BO_ 2151047168 100;
BA_ "MessageSubnet" BO_ 2155331584 0;
BA_ "GenMsgStartDelayTime" BO_ 2155331584 160;
BA_ "GenMsgCycleTime" BO_ 2155331584 1000;
BA_ "GenMsgSendType" BO_ 2155331584 0;
BA_ "Prio" BO_ 2154225664 3;
BA_ "MessageSubnet" BO_ 2154225664 0;
BA_ "GenMsgDelayTime" BO_ 2154225664 100;
BA_ "MessageSubnet" BO_ 2149900288 0;
BA_ "GenMsgDelayTime" BO_ 2149900288 100;
BA_ "MessageSubnet" BO_ 2159001600 0;
BA_ "GenMsgDelayTime" BO_ 2159001600 100;
BA_ "MessageSubnet" BO_ 2158993408 0;
BA_ "GenMsgDelayTime" BO_ 2158993408 100;
BA_ "MessageSubnet" BO_ 2154708992 0;
BA_ "GenMsgDelayTime" BO_ 2154708992 200;
BA_ "MessageSubnet" BO_ 2158985216 0;
BA_ "GenMsgDelayTime" BO_ 2158985216 20;
BA_ "Prio" BO_ 2154471424 3;
BA_ "MessageSubnet" BO_ 2154471424 0;
BA_ "GenMsgDelayTime" BO_ 2154471424 100;
BA_ "MessageSubnet" BO_ 2159149056 0;
BA_ "GenMsgDelayTime" BO_ 2159149056 10;
BA_ "MessageSubnet" BO_ 2159116288 0;
BA_ "GenMsgDelayTime" BO_ 2159116288 10;
BA_ "MessageSubnet" BO_ 2158796800 0;
BA_ "GenMsgDelayTime" BO_ 2158796800 100;
BA_ "MessageSubnet" BO_ 2158755840 0;
BA_ "GenMsgDelayTime" BO_ 2158755840 100;
BA_ "MessageSubnet" BO_ 2159157248 0;
BA_ "GenMsgDelayTime" BO_ 2159157248 10;
BA_ "MessageSubnet" BO_ 2153955328 0;
BA_ "GenMsgDelayTime" BO_ 2153955328 100;
BA_ "MessageSubnet" BO_ 2151063552 0;
BA_ "GenMsgDelayTime" BO_ 2151063552 100;
BA_ "MessageSubnet" BO_ 2157985792 0;
BA_ "GenMsgDelayTime" BO_ 2157985792 100;
BA_ "MessageSubnet" BO_ 2151284736 0;
BA_ "GenMsgDelayTime" BO_ 2151284736 100;
BA_ "MessageSubnet" BO_ 2159099904 0;
BA_ "GenMsgDelayTime" BO_ 2159099904 10;
BA_ "MessageSubnet" BO_ 2159067136 0;
BA_ "GenMsgDelayTime" BO_ 2159067136 10;
BA_ "MessageSubnet" BO_ 2159206400 0;
BA_ "GenMsgDelayTime" BO_ 2159206400 10;
BA_ "MessageSubnet" BO_ 2159198208 0;
BA_ "GenMsgDelayTime" BO_ 2159198208 10;
BA_ "MessageSubnet" BO_ 2159190016 0;
BA_ "GenMsgDelayTime" BO_ 2159190016 10;
BA_ "MessageSubnet" BO_ 2159181824 0;
BA_ "GenMsgDelayTime" BO_ 2159181824 10;
BA_ "MessageSubnet" BO_ 2159173632 0;
BA_ "GenMsgDelayTime" BO_ 2159173632 10;
BA_ "MessageSubnet" BO_ 2159165440 0;
BA_ "GenMsgDelayTime" BO_ 2159165440 10;
BA_ "MessageSubnet" BO_ 2159108096 0;
BA_ "GenMsgDelayTime" BO_ 2159108096 10;
BA_ "MessageSubnet" BO_ 2159075328 0;
BA_ "GenMsgDelayTime" BO_ 2159075328 10;
BA_ "MessageSubnet" BO_ 2151718912 0;
BA_ "GenMsgDelayTime" BO_ 2151718912 10;
BA_ "MessageSubnet" BO_ 2155479040 0;
BA_ "GenMsgDelayTime" BO_ 2155479040 100;
BA_ "MessageSubnet" BO_ 2151383040 0;
BA_ "GenMsgDelayTime" BO_ 2151383040 100;
BA_ "GenMsgILSupport" BO_ 1350 0;
BA_ "TpApplType" BO_ 1350 "DiagUUDTResponse";
BA_ "Prio" BO_ 1350 0;
BA_ "MessageSubnet" BO_ 1350 0;
BA_ "Prio" BO_ 1606 0;
BA_ "MessageSubnet" BO_ 1606 0;
BA_ "DiagResponse" BO_ 1606 1;
BA_ "GenMsgILSupport" BO_ 1355 0;
BA_ "TpApplType" BO_ 1355 "DiagUUDTResponse";
BA_ "Prio" BO_ 1355 0;
BA_ "MessageSubnet" BO_ 1355 0;
BA_ "GenMsgILSupport" BO_ 1611 0;
BA_ "Prio" BO_ 1611 0;
BA_ "MessageSubnet" BO_ 1611 0;
BA_ "DiagResponse" BO_ 1611 1;
BA_ "TpApplType" BO_ 1374 "DiagUUDTResponse";
BA_ "Prio" BO_ 1374 0;
BA_ "MessageSubnet" BO_ 1374 0;
BA_ "Prio" BO_ 1630 0;
BA_ "MessageSubnet" BO_ 1630 0;
BA_ "DiagResponse" BO_ 1630 1;
BA_ "Prio" BO_ 2155421696 3;
BA_ "MessageSubnet" BO_ 2155421696 0;
BA_ "GenMsgDelayTime" BO_ 2155421696 100;
BA_ "MessageSubnet" BO_ 2155413504 0;
BA_ "GenMsgDelayTime" BO_ 2155413504 100;
BA_ "MessageSubnet" BO_ 2159026176 0;
BA_ "GenMsgDelayTime" BO_ 2159026176 10;
BA_ "GenSigSendType" SG_ 2150277120 PsngSysLongV 10;
BA_ "VNSigInfotainment" SG_ 2150277120 PsngSysLongV 1;
BA_ "SignalType" SG_ 2150277120 PsngSysLongV "ENM";
BA_ "SignalLongName" SG_ 2150277120 PsngSysLongV "Positioning System Longitude Validity";
BA_ "VNSigAllNodes" SG_ 2150277120 PsngSysLongV 1;
BA_ "GenSigDeltaValue" SG_ 2150277120 PsngSysLong 10;
BA_ "GenSigSendType" SG_ 2150277120 PsngSysLong 12;
BA_ "VNSigInfotainment" SG_ 2150277120 PsngSysLong 1;
BA_ "SignalType" SG_ 2150277120 PsngSysLong "SNM";
BA_ "SignalLongName" SG_ 2150277120 PsngSysLong "Positioning System Longitude";
BA_ "VNSigAllNodes" SG_ 2150277120 PsngSysLong 1;
BA_ "GenSigSendType" SG_ 2150277120 PsngSysLatV 10;
BA_ "VNSigInfotainment" SG_ 2150277120 PsngSysLatV 1;
BA_ "SignalType" SG_ 2150277120 PsngSysLatV "ENM";
BA_ "SignalLongName" SG_ 2150277120 PsngSysLatV "Positioning System Latitude Validity";
BA_ "VNSigAllNodes" SG_ 2150277120 PsngSysLatV 1;
BA_ "GenSigDeltaValue" SG_ 2150277120 PsngSysLat 10;
BA_ "GenSigSendType" SG_ 2150277120 PsngSysLat 12;
BA_ "GenSigSendOnInit" SG_ 2150277120 PsngSysLat 2;
BA_ "VNSigInfotainment" SG_ 2150277120 PsngSysLat 1;
BA_ "SignalType" SG_ 2150277120 PsngSysLat "SNM";
BA_ "SignalLongName" SG_ 2150277120 PsngSysLat "Positioning System Latitude";
BA_ "VNSigAllNodes" SG_ 2150277120 PsngSysLat 1;
BA_ "GenSigSendType" SG_ 2150285312 PsngSysHdingV 10;
BA_ "SignalType" SG_ 2150285312 PsngSysHdingV "ENM";
BA_ "SignalLongName" SG_ 2150285312 PsngSysHdingV "Positioning System Heading Validity";
BA_ "VNSigAllNodes" SG_ 2150285312 PsngSysHdingV 1;
BA_ "GenSigDeltaValue" SG_ 2150285312 PsngSysHding 50;
BA_ "GenSigSendType" SG_ 2150285312 PsngSysHding 12;
BA_ "SignalType" SG_ 2150285312 PsngSysHding "UNM";
BA_ "SignalLongName" SG_ 2150285312 PsngSysHding "Positioning System Heading";
BA_ "VNSigAllNodes" SG_ 2150285312 PsngSysHding 1;
BA_ "GenSigSendType" SG_ 2150285312 PsngSysElvtnV 10;
BA_ "VNSigInfotainment" SG_ 2150285312 PsngSysElvtnV 1;
BA_ "SignalType" SG_ 2150285312 PsngSysElvtnV "ENM";
BA_ "SignalLongName" SG_ 2150285312 PsngSysElvtnV "Positioning System Elevation Validity";
BA_ "VNSigAllNodes" SG_ 2150285312 PsngSysElvtnV 1;
BA_ "GenSigDeltaValue" SG_ 2150285312 PsngSysElvtn 100;
BA_ "GenSigSendType" SG_ 2150285312 PsngSysElvtn 12;
BA_ "VNSigInfotainment" SG_ 2150285312 PsngSysElvtn 1;
BA_ "SignalType" SG_ 2150285312 PsngSysElvtn "UNM";
BA_ "SignalLongName" SG_ 2150285312 PsngSysElvtn "Positioning System Elevation";
BA_ "VNSigAllNodes" SG_ 2150285312 PsngSysElvtn 1;
BA_ "GenSigDeltaValue" SG_ 2150285312 PsngSysDilPrcs 10;
BA_ "GenSigSendType" SG_ 2150285312 PsngSysDilPrcs 12;
BA_ "VNSigInfotainment" SG_ 2150285312 PsngSysDilPrcs 1;
BA_ "SignalType" SG_ 2150285312 PsngSysDilPrcs "UNM";
BA_ "SignalLongName" SG_ 2150285312 PsngSysDilPrcs "Positioning System Dilution of Precision";
BA_ "VNSigAllNodes" SG_ 2150285312 PsngSysDilPrcs 1;
BA_ "GenSigSendType" SG_ 2150285312 PsngSysCalcSpdV 10;
BA_ "VNSigInfotainment" SG_ 2150285312 PsngSysCalcSpdV 1;
BA_ "SignalType" SG_ 2150285312 PsngSysCalcSpdV "ENM";
BA_ "SignalLongName" SG_ 2150285312 PsngSysCalcSpdV "Positioning System Calculated Speed Validity";
BA_ "VNSigAllNodes" SG_ 2150285312 PsngSysCalcSpdV 1;
BA_ "GenSigDeltaValue" SG_ 2150285312 PsngSysCalcSpd 5;
BA_ "GenSigSendType" SG_ 2150285312 PsngSysCalcSpd 12;
BA_ "VNSigInfotainment" SG_ 2150285312 PsngSysCalcSpd 1;
BA_ "SignalType" SG_ 2150285312 PsngSysCalcSpd "UNM";
BA_ "SignalLongName" SG_ 2150285312 PsngSysCalcSpd "Positioning System Calculated Speed";
BA_ "VNSigAllNodes" SG_ 2150285312 PsngSysCalcSpd 1;
BA_ "GenSigSendType" SG_ 2150285312 PsngSysDilPrcsV 10;
BA_ "VNSigInfotainment" SG_ 2150285312 PsngSysDilPrcsV 1;
BA_ "SignalType" SG_ 2150285312 PsngSysDilPrcsV "ENM";
BA_ "SignalLongName" SG_ 2150285312 PsngSysDilPrcsV "Positioning System Dilution of Precision Validity";
BA_ "VNSigAllNodes" SG_ 2150285312 PsngSysDilPrcsV 1;
BA_ "GenSigDeltaValue" SG_ 2151890944 TICR_Ind1FlshRtOn 1;
BA_ "GenSigSendType" SG_ 2151890944 TICR_Ind1FlshRtOn 12;
BA_ "VNSigInfotainment" SG_ 2151890944 TICR_Ind1FlshRtOn 1;
BA_ "SignalType" SG_ 2151890944 TICR_Ind1FlshRtOn "UNM";
BA_ "PacketOrder" SG_ 2151890944 TICR_Ind1FlshRtOn 5;
BA_ "SignalLongName" SG_ 2151890944 TICR_Ind1FlshRtOn "Telematics Indication Control Request : Indicator 1 Flash Rate On";
BA_ "VNSigAllNodes" SG_ 2151890944 TICR_Ind1FlshRtOn 1;
BA_ "GenSigDeltaValue" SG_ 2151890944 TICR_Ind1FlshRtOff 1;
BA_ "GenSigSendType" SG_ 2151890944 TICR_Ind1FlshRtOff 12;
BA_ "VNSigInfotainment" SG_ 2151890944 TICR_Ind1FlshRtOff 1;
BA_ "SignalType" SG_ 2151890944 TICR_Ind1FlshRtOff "UNM";
BA_ "PacketOrder" SG_ 2151890944 TICR_Ind1FlshRtOff 4;
BA_ "SignalLongName" SG_ 2151890944 TICR_Ind1FlshRtOff "Telematics Indication Control Request : Indicator 1 Flash Rate Off";
BA_ "VNSigAllNodes" SG_ 2151890944 TICR_Ind1FlshRtOff 1;
BA_ "GenSigDeltaValue" SG_ 2151890944 TICR_Ind1Cnt 1;
BA_ "GenSigSendType" SG_ 2151890944 TICR_Ind1Cnt 12;
BA_ "VNSigInfotainment" SG_ 2151890944 TICR_Ind1Cnt 1;
BA_ "SignalType" SG_ 2151890944 TICR_Ind1Cnt "UNM";
BA_ "PacketOrder" SG_ 2151890944 TICR_Ind1Cnt 3;
BA_ "SignalLongName" SG_ 2151890944 TICR_Ind1Cnt "Telematics Indication Control Request : Indicator 1 Count";
BA_ "VNSigAllNodes" SG_ 2151890944 TICR_Ind1Cnt 1;
BA_ "GenSigSendType" SG_ 2151890944 TICR_Ind1 10;
BA_ "VNSigInfotainment" SG_ 2151890944 TICR_Ind1 1;
BA_ "SignalType" SG_ 2151890944 TICR_Ind1 "ENM";
BA_ "PacketOrder" SG_ 2151890944 TICR_Ind1 2;
BA_ "SignalLongName" SG_ 2151890944 TICR_Ind1 "Telematics Indication Control Request : Indicator 1";
BA_ "VNSigAllNodes" SG_ 2151890944 TICR_Ind1 1;
BA_ "GenSigSendType" SG_ 2151890944 TICR_Ind1Req 10;
BA_ "VNSigInfotainment" SG_ 2151890944 TICR_Ind1Req 1;
BA_ "SignalType" SG_ 2151890944 TICR_Ind1Req "ENM";
BA_ "PacketOrder" SG_ 2151890944 TICR_Ind1Req 1;
BA_ "SignalLongName" SG_ 2151890944 TICR_Ind1Req "Telematics Indication Control Request : Indication 1 Request";
BA_ "VNSigAllNodes" SG_ 2151890944 TICR_Ind1Req 1;
BA_ "GenSigSendType" SG_ 2151251968 TICS_Ind1V 10;
BA_ "VNSigInfotainment" SG_ 2151251968 TICS_Ind1V 1;
BA_ "SignalType" SG_ 2151251968 TICS_Ind1V "ENM";
BA_ "PacketOrder" SG_ 2151251968 TICS_Ind1V 3;
BA_ "SignalLongName" SG_ 2151251968 TICS_Ind1V "Telematics Indication Control Status : Indicator 1 Validity";
BA_ "VNSigAllNodes" SG_ 2151251968 TICS_Ind1V 1;
BA_ "GenSigDeltaValue" SG_ 2151251968 TICS_Ind1FlshRtOnSt 1;
BA_ "GenSigSendType" SG_ 2151251968 TICS_Ind1FlshRtOnSt 12;
BA_ "VNSigInfotainment" SG_ 2151251968 TICS_Ind1FlshRtOnSt 1;
BA_ "SignalType" SG_ 2151251968 TICS_Ind1FlshRtOnSt "UNM";
BA_ "PacketOrder" SG_ 2151251968 TICS_Ind1FlshRtOnSt 5;
BA_ "SignalLongName" SG_ 2151251968 TICS_Ind1FlshRtOnSt "Telematics Indication Control Status : Indicator 1 Flash Rate On Status";
BA_ "VNSigAllNodes" SG_ 2151251968 TICS_Ind1FlshRtOnSt 1;
BA_ "GenSigDeltaValue" SG_ 2151251968 TICS_Ind1FlshRtOffSt 1;
BA_ "GenSigSendType" SG_ 2151251968 TICS_Ind1FlshRtOffSt 12;
BA_ "VNSigInfotainment" SG_ 2151251968 TICS_Ind1FlshRtOffSt 1;
BA_ "SignalType" SG_ 2151251968 TICS_Ind1FlshRtOffSt "UNM";
BA_ "PacketOrder" SG_ 2151251968 TICS_Ind1FlshRtOffSt 4;
BA_ "SignalLongName" SG_ 2151251968 TICS_Ind1FlshRtOffSt "Telematics Indication Control Status : Indicator 1 Flash Rate Off Status";
BA_ "VNSigAllNodes" SG_ 2151251968 TICS_Ind1FlshRtOffSt 1;
BA_ "GenSigSendType" SG_ 2151251968 TICS_Ind1 10;
BA_ "VNSigInfotainment" SG_ 2151251968 TICS_Ind1 1;
BA_ "SignalType" SG_ 2151251968 TICS_Ind1 "ENM";
BA_ "PacketOrder" SG_ 2151251968 TICS_Ind1 2;
BA_ "SignalLongName" SG_ 2151251968 TICS_Ind1 "Telematics Indication Control Status : Indicator 1";
BA_ "VNSigAllNodes" SG_ 2151251968 TICS_Ind1 1;
BA_ "GenSigSendType" SG_ 2151251968 TICS_Ind1Stat 10;
BA_ "VNSigInfotainment" SG_ 2151251968 TICS_Ind1Stat 1;
BA_ "SignalType" SG_ 2151251968 TICS_Ind1Stat "ENM";
BA_ "PacketOrder" SG_ 2151251968 TICS_Ind1Stat 1;
BA_ "SignalLongName" SG_ 2151251968 TICS_Ind1Stat "Telematics Indication Control Status : Indication 1 Status";
BA_ "VNSigAllNodes" SG_ 2151251968 TICS_Ind1Stat 1;
BA_ "GenSigSendType" SG_ 2155495424 RmStrHtdStEnRq 10;
BA_ "SignalType" SG_ 2155495424 RmStrHtdStEnRq "ENM";
BA_ "SignalLongName" SG_ 2155495424 RmStrHtdStEnRq "Remote Start Heated Seat Enable Request";
BA_ "VNSigAllNodes" SG_ 2155495424 RmStrHtdStEnRq 1;
BA_ "GenSigSendType" SG_ 2155495424 RmStrCldStEnReq 10;
BA_ "SignalType" SG_ 2155495424 RmStrCldStEnReq "ENM";
BA_ "SignalLongName" SG_ 2155495424 RmStrCldStEnReq "Remote Start Cooled Seat Enable Request";
BA_ "VNSigAllNodes" SG_ 2155495424 RmStrCldStEnReq 1;
BA_ "SignalType" SG_ 2149990400 ElcTransRngRq "ENM";
BA_ "SignalLongName" SG_ 2149990400 ElcTransRngRq "Electronic Transmission Range Request";
BA_ "VNSigAllNodes" SG_ 2149990400 ElcTransRngRq 1;
BA_ "SignalType" SG_ 2149990400 TrnsfrCsRngShfSpdLmt "UNM";
BA_ "SignalLongName" SG_ 2149990400 TrnsfrCsRngShfSpdLmt "Transfer Case Range Shift Speed Limit";
BA_ "VNSigAllNodes" SG_ 2149990400 TrnsfrCsRngShfSpdLmt 1;
BA_ "SignalType" SG_ 2149990400 TrlrBrkngVDA "ENM";
BA_ "SignalLongName" SG_ 2149990400 TrlrBrkngVDA "Trailer Braking Virtual Device Availability";
BA_ "GenSigStartValue" SG_ 2149990400 TrlrBrkngVDA 1;
BA_ "VNSigAllNodes" SG_ 2149990400 TrlrBrkngVDA 1;
BA_ "SignalType" SG_ 2149990400 SecAxlOperMod "ENM";
BA_ "SignalLongName" SG_ 2149990400 SecAxlOperMod "Secondary Axle Operational Mode";
BA_ "VNSigAllNodes" SG_ 2149990400 SecAxlOperMod 1;
BA_ "SignalType" SG_ 2149990400 InstFuelConsmpRate "UNM";
BA_ "SignalLongName" SG_ 2149990400 InstFuelConsmpRate "Instantaneous Fuel Consumption Rate";
BA_ "VNSigAllNodes" SG_ 2149990400 InstFuelConsmpRate 1;
BA_ "SignalType" SG_ 2149990400 MotStBltUnblIO "BLN";
BA_ "SignalLongName" SG_ 2149990400 MotStBltUnblIO "Motorized Seat Belt Unavailable Indication On";
BA_ "VNSigAllNodes" SG_ 2149990400 MotStBltUnblIO 1;
BA_ "SignalType" SG_ 2149990400 MotStBltFldIO "BLN";
BA_ "SignalLongName" SG_ 2149990400 MotStBltFldIO "Motorized Seat Belt Failed Indication On";
BA_ "VNSigAllNodes" SG_ 2149990400 MotStBltFldIO 1;
BA_ "SignalType" SG_ 2149990400 TransNtrlCntrlMdStat "ENM";
BA_ "SignalLongName" SG_ 2149990400 TransNtrlCntrlMdStat "Transmission Neutral Control Mode Status";
BA_ "VNSigAllNodes" SG_ 2149990400 TransNtrlCntrlMdStat 1;
BA_ "SignalType" SG_ 2149990400 TrlrWiringFltIO "BLN";
BA_ "SignalLongName" SG_ 2149990400 TrlrWiringFltIO "Trailer Wiring Fault Indication On";
BA_ "VNSigAllNodes" SG_ 2149990400 TrlrWiringFltIO 1;
BA_ "SignalType" SG_ 2149990400 TrlrCnctdIO "BLN";
BA_ "SignalLongName" SG_ 2149990400 TrlrCnctdIO "Trailer Connected Indication On";
BA_ "VNSigAllNodes" SG_ 2149990400 TrlrCnctdIO 1;
BA_ "SignalType" SG_ 2149990400 TrlrBrkngGainSetIO "BLN";
BA_ "SignalLongName" SG_ 2149990400 TrlrBrkngGainSetIO "Trailer Braking Gain Setting Indication On";
BA_ "VNSigAllNodes" SG_ 2149990400 TrlrBrkngGainSetIO 1;
BA_ "SignalType" SG_ 2149990400 TrlrBrkngGainSet "UNM";
BA_ "SignalLongName" SG_ 2149990400 TrlrBrkngGainSet "Trailer Braking Gain Setting";
BA_ "VNSigAllNodes" SG_ 2149990400 TrlrBrkngGainSet 1;
BA_ "SignalType" SG_ 2149990400 TrlrBrkngFrcOtpt "UNM";
BA_ "SignalLongName" SG_ 2149990400 TrlrBrkngFrcOtpt "Trailer Braking Force Output";
BA_ "VNSigAllNodes" SG_ 2149990400 TrlrBrkngFrcOtpt 1;
BA_ "SignalType" SG_ 2149990400 SrvTrlrBrkngSysIO "BLN";
BA_ "SignalLongName" SG_ 2149990400 SrvTrlrBrkngSysIO "ServiceTrailer Braking System Indication On";
BA_ "VNSigAllNodes" SG_ 2149990400 SrvTrlrBrkngSysIO 1;
BA_ "SignalType" SG_ 2149990400 ChkTrlrIO "BLN";
BA_ "SignalLongName" SG_ 2149990400 ChkTrlrIO "Check Trailer Indication On";
BA_ "VNSigAllNodes" SG_ 2149990400 ChkTrlrIO 1;
BA_ "SignalType" SG_ 2149990400 ScndryAxleVDA "ENM";
BA_ "SignalLongName" SG_ 2149990400 ScndryAxleVDA "Secondary Axle Virtual Device Availability";
BA_ "GenSigStartValue" SG_ 2149990400 ScndryAxleVDA 1;
BA_ "VNSigAllNodes" SG_ 2149990400 ScndryAxleVDA 1;
BA_ "SignalType" SG_ 2149990400 TrlrHtchSwAtv_ITBC "BLN";
BA_ "SignalLongName" SG_ 2149990400 TrlrHtchSwAtv_ITBC "Trailer Hitch Switch Active ITBC";
BA_ "VNSigAllNodes" SG_ 2149990400 TrlrHtchSwAtv_ITBC 1;
BA_ "SignalType" SG_ 2149990400 AdvHlmpsVDA "ENM";
BA_ "SignalLongName" SG_ 2149990400 AdvHlmpsVDA "Advance Headlamps Virtual Device Availability";
BA_ "GenSigStartValue" SG_ 2149990400 AdvHlmpsVDA 1;
BA_ "VNSigAllNodes" SG_ 2149990400 AdvHlmpsVDA 1;
BA_ "SignalType" SG_ 2149990400 ABSIO "BLN";
BA_ "SignalLongName" SG_ 2149990400 ABSIO "Antilock Brake System Indication On";
BA_ "VNSigAllNodes" SG_ 2149990400 ABSIO 1;
BA_ "SignalType" SG_ 2149990400 ACCHdwayStngIO "BLN";
BA_ "SignalLongName" SG_ 2149990400 ACCHdwayStngIO "Adaptive Cruise Control Headway Setting Indication On";
BA_ "VNSigAllNodes" SG_ 2149990400 ACCHdwayStngIO 1;
BA_ "SignalType" SG_ 2149990400 StpOnBrkToRelPBIndOn "BLN";
BA_ "SignalLongName" SG_ 2149990400 StpOnBrkToRelPBIndOn "Step On Brake To Release Park Brake Indication On";
BA_ "VNSigAllNodes" SG_ 2149990400 StpOnBrkToRelPBIndOn 1;
BA_ "SignalType" SG_ 2149990400 SADmpVDA "ENM";
BA_ "SignalLongName" SG_ 2149990400 SADmpVDA "Semi Active Damping Virtual Device Availability";
BA_ "GenSigStartValue" SG_ 2149990400 SADmpVDA 1;
BA_ "VNSigAllNodes" SG_ 2149990400 SADmpVDA 1;
BA_ "SignalType" SG_ 2149990400 ACCDrvrSeltdSpdIO "BLN";
BA_ "SignalLongName" SG_ 2149990400 ACCDrvrSeltdSpdIO "Adaptive Cruise Control Driver Selected Speed Indication On";
BA_ "VNSigAllNodes" SG_ 2149990400 ACCDrvrSeltdSpdIO 1;
BA_ "SignalType" SG_ 2149990400 TreInfMonSysRstPrfmd "BLN";
BA_ "SignalLongName" SG_ 2149990400 TreInfMonSysRstPrfmd "Tire Inflation Monitoring System Reset Performed";
BA_ "VNSigAllNodes" SG_ 2149990400 TreInfMonSysRstPrfmd 1;
BA_ "SignalType" SG_ 2149990400 DrvThrtlOvrdIO "BLN";
BA_ "SignalLongName" SG_ 2149990400 DrvThrtlOvrdIO "Driver Throttle Override Indication On";
BA_ "VNSigAllNodes" SG_ 2149990400 DrvThrtlOvrdIO 1;
BA_ "SignalType" SG_ 2155380736 ServFuelSysTrnsfrPmpIO "BLN";
BA_ "SignalLongName" SG_ 2155380736 ServFuelSysTrnsfrPmpIO "Service Fuel System Transfer Pump Indication On";
BA_ "VNSigAllNodes" SG_ 2155380736 ServFuelSysTrnsfrPmpIO 1;
BA_ "SignalType" SG_ 2155380736 ACCmCltEngd "BLN";
BA_ "SignalLongName" SG_ 2155380736 ACCmCltEngd "Air Conditioning Compressor Clutch Engaged";
BA_ "VNSigAllNodes" SG_ 2155380736 ACCmCltEngd 1;
BA_ "SignalType" SG_ 2155380736 StrAsstRdcdLvl3IO "BLN";
BA_ "SignalLongName" SG_ 2155380736 StrAsstRdcdLvl3IO "Steering Assist Reduced Level 3 Indication On";
BA_ "VNSigAllNodes" SG_ 2155380736 StrAsstRdcdLvl3IO 1;
BA_ "SignalType" SG_ 2155380736 StrAsstRdcdLvl2IO "BLN";
BA_ "SignalLongName" SG_ 2155380736 StrAsstRdcdLvl2IO "Steering Assist Reduced Level 2 Indication On";
BA_ "VNSigAllNodes" SG_ 2155380736 StrAsstRdcdLvl2IO 1;
BA_ "SignalType" SG_ 2155380736 StrngAsstRdcdIO "BLN";
BA_ "SignalLongName" SG_ 2155380736 StrngAsstRdcdIO "Steering Assist Reduced Indication On";
BA_ "VNSigAllNodes" SG_ 2155380736 StrngAsstRdcdIO 1;
BA_ "SignalType" SG_ 2155380736 ARSFlrIO "BLN";
BA_ "SignalLongName" SG_ 2155380736 ARSFlrIO "Active Rear Steer Failure Indication On";
BA_ "VNSigAllNodes" SG_ 2155380736 ARSFlrIO 1;
BA_ "SignalType" SG_ 2155380736 PwrPkFnSpd "UNM";
BA_ "SignalLongName" SG_ 2155380736 PwrPkFnSpd "Power Pack Fan Speed";
BA_ "VNSigAllNodes" SG_ 2155380736 PwrPkFnSpd 1;
BA_ "SignalType" SG_ 2155380736 PwrPckAirInTempFlt "UNM";
BA_ "SignalLongName" SG_ 2155380736 PwrPckAirInTempFlt "Power Pack Air Inlet Temperature Filtered";
BA_ "VNSigAllNodes" SG_ 2155380736 PwrPckAirInTempFlt 1;
BA_ "SignalType" SG_ 2155380736 PTExPrtclFltrWrn2IO "BLN";
BA_ "SignalLongName" SG_ 2155380736 PTExPrtclFltrWrn2IO "Powertrain Exhaust Particle Filter Warning 2 Indication On";
BA_ "VNSigAllNodes" SG_ 2155380736 PTExPrtclFltrWrn2IO 1;
BA_ "SignalType" SG_ 2155380736 EngOilHotIO "BLN";
BA_ "SignalLongName" SG_ 2155380736 EngOilHotIO "Engine Oil Hot Indication On";
BA_ "VNSigAllNodes" SG_ 2155380736 EngOilHotIO 1;
BA_ "SignalType" SG_ 2155380736 RrLevVDA "ENM";
BA_ "SignalLongName" SG_ 2155380736 RrLevVDA "Rear Leveling Virtual Device Availability";
BA_ "GenSigStartValue" SG_ 2155380736 RrLevVDA 1;
BA_ "VNSigAllNodes" SG_ 2155380736 RrLevVDA 1;
BA_ "SignalType" SG_ 2155380736 EngWtrInFlIO "BLN";
BA_ "SignalLongName" SG_ 2155380736 EngWtrInFlIO "Engine Water In Fuel Indication On";
BA_ "VNSigAllNodes" SG_ 2155380736 EngWtrInFlIO 1;
BA_ "SignalType" SG_ 2155380736 AdvFrntLghtSysIndRq "ENM";
BA_ "SignalLongName" SG_ 2155380736 AdvFrntLghtSysIndRq "Advanced Front Lighting System Indication Request";
BA_ "VNSigAllNodes" SG_ 2155380736 AdvFrntLghtSysIndRq 1;
BA_ "SignalType" SG_ 2155380736 PTExPrtclFltrWrnIO "BLN";
BA_ "SignalLongName" SG_ 2155380736 PTExPrtclFltrWrnIO "Powertrain Exhaust Particle Filter Warning Indication On";
BA_ "VNSigAllNodes" SG_ 2155380736 PTExPrtclFltrWrnIO 1;
BA_ "SignalType" SG_ 2155380736 AirCndOffIO "BLN";
BA_ "SignalLongName" SG_ 2155380736 AirCndOffIO "Air Conditioning Off Indication On";
BA_ "VNSigAllNodes" SG_ 2155380736 AirCndOffIO 1;
BA_ "SignalType" SG_ 2155380736 HdLtLvlFlrIO "BLN";
BA_ "SignalLongName" SG_ 2155380736 HdLtLvlFlrIO "Head Light Leveling Failure Indication On";
BA_ "VNSigAllNodes" SG_ 2155380736 HdLtLvlFlrIO 1;
BA_ "SignalType" SG_ 2155380736 PwrStrIO "BLN";
BA_ "SignalLongName" SG_ 2155380736 PwrStrIO "Power Steering Indication On";
BA_ "VNSigAllNodes" SG_ 2155380736 PwrStrIO 1;
BA_ "SignalType" SG_ 2155380736 EngHt_StpEngIO "BLN";
BA_ "SignalLongName" SG_ 2155380736 EngHt_StpEngIO "Engine Hot / Stop Engine Indication On";
BA_ "VNSigAllNodes" SG_ 2155380736 EngHt_StpEngIO 1;
BA_ "SignalType" SG_ 2155380736 CkFlFilrCapIO "BLN";
BA_ "SignalLongName" SG_ 2155380736 CkFlFilrCapIO "Check Fuel Filler Cap Indication On";
BA_ "VNSigAllNodes" SG_ 2155380736 CkFlFilrCapIO 1;
BA_ "SignalType" SG_ 2155380736 RdcdPwrIO "BLN";
BA_ "SignalLongName" SG_ 2155380736 RdcdPwrIO "Reduced Power Indication On";
BA_ "VNSigAllNodes" SG_ 2155380736 RdcdPwrIO 1;
BA_ "SignalType" SG_ 2155380736 EngOilPrsLwIO "BLN";
BA_ "SignalLongName" SG_ 2155380736 EngOilPrsLwIO "Engine Oil Pressure Low Indication On";
BA_ "VNSigAllNodes" SG_ 2155380736 EngOilPrsLwIO 1;
BA_ "SignalType" SG_ 2155380736 EngOilLvlLwIO "BLN";
BA_ "SignalLongName" SG_ 2155380736 EngOilLvlLwIO "Engine Oil Level Low Indication On";
BA_ "VNSigAllNodes" SG_ 2155380736 EngOilLvlLwIO 1;
BA_ "SignalType" SG_ 2155380736 EngOilChngIO "BLN";
BA_ "SignalLongName" SG_ 2155380736 EngOilChngIO "Engine Oil Change Indication On";
BA_ "VNSigAllNodes" SG_ 2155380736 EngOilChngIO 1;
BA_ "SignalType" SG_ 2155380736 EngHotFuelEnrchmntIO "BLN";
BA_ "SignalLongName" SG_ 2155380736 EngHotFuelEnrchmntIO "Engine Hot Fuel Enrichment Indication On";
BA_ "VNSigAllNodes" SG_ 2155380736 EngHotFuelEnrchmntIO 1;
BA_ "GenSigSendType" SG_ 2155380736 DslGlwPlgIO 10;
BA_ "SignalType" SG_ 2155380736 DslGlwPlgIO "BLN";
BA_ "SignalLongName" SG_ 2155380736 DslGlwPlgIO "Diesel Glow Plug Indication On";
BA_ "VNSigAllNodes" SG_ 2155380736 DslGlwPlgIO 1;
BA_ "SignalType" SG_ 2155380736 SrvLevSysIO "BLN";
BA_ "SignalLongName" SG_ 2155380736 SrvLevSysIO "Service Leveling System Indication On";
BA_ "VNSigAllNodes" SG_ 2155380736 SrvLevSysIO 1;
BA_ "SignalType" SG_ 2155380736 VehOvrLdIndOn "BLN";
BA_ "SignalLongName" SG_ 2155380736 VehOvrLdIndOn "Vehicle Overloaded Indication On";
BA_ "VNSigAllNodes" SG_ 2155380736 VehOvrLdIndOn 1;
BA_ "SignalType" SG_ 2150498304 OAT_PT_EstV "ENM";
BA_ "SignalLongName" SG_ 2150498304 OAT_PT_EstV "Outside Air Temperature Powertrain Estimated Validity";
BA_ "VNSigAllNodes" SG_ 2150498304 OAT_PT_EstV 1;
BA_ "SignalType" SG_ 2150498304 EngOilPrsV "ENM";
BA_ "SignalLongName" SG_ 2150498304 EngOilPrsV "Engine Oil Pressure Validity";
BA_ "VNSigAllNodes" SG_ 2150498304 EngOilPrsV 1;
BA_ "SignalType" SG_ 2150498304 EngOilPrs "UNM";
BA_ "SignalLongName" SG_ 2150498304 EngOilPrs "Engine Oil Pressure";
BA_ "VNSigAllNodes" SG_ 2150498304 EngOilPrs 1;
BA_ "SignalType" SG_ 2150498304 EngOilTmpV "ENM";
BA_ "SignalLongName" SG_ 2150498304 EngOilTmpV "Engine Oil Temperature Validity";
BA_ "VNSigAllNodes" SG_ 2150498304 EngOilTmpV 1;
BA_ "SignalType" SG_ 2150498304 EngOilTmp "UNM";
BA_ "SignalLongName" SG_ 2150498304 EngOilTmp "Engine Oil Temperature";
BA_ "VNSigAllNodes" SG_ 2150498304 EngOilTmp 1;
BA_ "SignalType" SG_ 2150498304 OAT_PT_Est "UNM";
BA_ "SignalLongName" SG_ 2150498304 OAT_PT_Est "Outside Air Temperature Powertrain Estimated";
BA_ "VNSigAllNodes" SG_ 2150498304 OAT_PT_Est 1;
BA_ "SignalType" SG_ 2150498304 TrnOilTmpV "ENM";
BA_ "SignalLongName" SG_ 2150498304 TrnOilTmpV "Transmission Oil Temperature Validity";
BA_ "VNSigAllNodes" SG_ 2150498304 TrnOilTmpV 1;
BA_ "SignalType" SG_ 2150498304 TrnOilTmp "UNM";
BA_ "SignalLongName" SG_ 2150498304 TrnOilTmp "Transmission Oil Temperature";
BA_ "VNSigAllNodes" SG_ 2150498304 TrnOilTmp 1;
BA_ "GenSigSendOnInit" SG_ 2150498304 EngCltTmpV 1;
BA_ "SignalType" SG_ 2150498304 EngCltTmpV "ENM";
BA_ "SignalLongName" SG_ 2150498304 EngCltTmpV "Engine Coolant Temperature Validity";
BA_ "VNSigAllNodes" SG_ 2150498304 EngCltTmpV 1;
BA_ "GenSigSendOnInit" SG_ 2150498304 EngCltTmp 1;
BA_ "SignalType" SG_ 2150498304 EngCltTmp "UNM";
BA_ "SignalLongName" SG_ 2150498304 EngCltTmp "Engine Coolant Temperature";
BA_ "VNSigAllNodes" SG_ 2150498304 EngCltTmp 1;
BA_ "SignalType" SG_ 2150498304 EngIntAirTmpV "ENM";
BA_ "SignalLongName" SG_ 2150498304 EngIntAirTmpV "Engine Intake Air Temperature Validity";
BA_ "VNSigAllNodes" SG_ 2150498304 EngIntAirTmpV 1;
BA_ "SignalType" SG_ 2150498304 EngIntAirTmp "UNM";
BA_ "SignalLongName" SG_ 2150498304 EngIntAirTmp "Engine Intake Air Temperature";
BA_ "VNSigAllNodes" SG_ 2150498304 EngIntAirTmp 1;
BA_ "SignalType" SG_ 2150498304 OAT_PT_EstM "ENM";
BA_ "SignalLongName" SG_ 2150498304 OAT_PT_EstM "Outside Air Temperature Powertrain Estimated Mask";
BA_ "VNSigAllNodes" SG_ 2150498304 OAT_PT_EstM 1;
BA_ "SignalType" SG_ 2150498304 BarPrsAbsV "ENM";
BA_ "SignalLongName" SG_ 2150498304 BarPrsAbsV "Barometric Pressure Absolute Validity";
BA_ "VNSigAllNodes" SG_ 2150498304 BarPrsAbsV 1;
BA_ "SignalType" SG_ 2150498304 BarPrsAbs "UNM";
BA_ "SignalLongName" SG_ 2150498304 BarPrsAbs "Barometric Pressure Absolute";
BA_ "VNSigAllNodes" SG_ 2150498304 BarPrsAbs 1;
BA_ "GenSigSendType" SG_ 2151047168 HdUpDspAnmtStat 10;
BA_ "SignalType" SG_ 2151047168 HdUpDspAnmtStat "ENM";
BA_ "SignalLongName" SG_ 2151047168 HdUpDspAnmtStat "Head Up Display Animation Status";
BA_ "VNSigAllNodes" SG_ 2151047168 HdUpDspAnmtStat 1;
BA_ "GenSigSendType" SG_ 2151047168 HUDActv 10;
BA_ "GenSigSendOnInit" SG_ 2151047168 HUDActv 1;
BA_ "VNSigInfotainment" SG_ 2151047168 HUDActv 1;
BA_ "SignalType" SG_ 2151047168 HUDActv "BLN";
BA_ "SignalLongName" SG_ 2151047168 HUDActv "Head Up Display Active";
BA_ "VNSigAllNodes" SG_ 2151047168 HUDActv 1;
BA_ "SignalType" SG_ 2155331584 WhlRotStatTmstmpRes "UNM";
BA_ "SignalLongName" SG_ 2155331584 WhlRotStatTmstmpRes "Wheel Rotational Status Timestamp Resolution";
BA_ "VNSigAllNodes" SG_ 2155331584 WhlRotStatTmstmpRes 1;
BA_ "SignalType" SG_ 2155331584 WhlPlsPerRevNonDrvn "UNM";
BA_ "SignalLongName" SG_ 2155331584 WhlPlsPerRevNonDrvn "Wheel Pulses Per Revolution Non Driven";
BA_ "VNSigAllNodes" SG_ 2155331584 WhlPlsPerRevNonDrvn 1;
BA_ "SignalType" SG_ 2155331584 WhlPlsPerRevDrvn "UNM";
BA_ "SignalLongName" SG_ 2155331584 WhlPlsPerRevDrvn "Wheel Pulses Per Revolution Driven";
BA_ "VNSigAllNodes" SG_ 2155331584 WhlPlsPerRevDrvn 1;
BA_ "GenSigSendType" SG_ 2154225664 RLDrHndleSwAtv 10;
BA_ "SignalType" SG_ 2154225664 RLDrHndleSwAtv "BLN";
BA_ "SignalLongName" SG_ 2154225664 RLDrHndleSwAtv "Rear Left Door Handle Switch Active";
BA_ "VNSigAllNodes" SG_ 2154225664 RLDrHndleSwAtv 1;
BA_ "GenSigSendType" SG_ 2154225664 RRDrHndleSwAtv 10;
BA_ "SignalType" SG_ 2154225664 RRDrHndleSwAtv "BLN";
BA_ "SignalLongName" SG_ 2154225664 RRDrHndleSwAtv "Rear Right Door Handle Switch Active";
BA_ "VNSigAllNodes" SG_ 2154225664 RRDrHndleSwAtv 1;
BA_ "GenSigSendType" SG_ 2154225664 RCHndleSwAtv 10;
BA_ "SignalType" SG_ 2154225664 RCHndleSwAtv "BLN";
BA_ "SignalLongName" SG_ 2154225664 RCHndleSwAtv "Rear Closure Handle Switch Active";
BA_ "VNSigAllNodes" SG_ 2154225664 RCHndleSwAtv 1;
BA_ "GenSigSendType" SG_ 2154225664 PasDrHndleSwAtv 10;
BA_ "SignalType" SG_ 2154225664 PasDrHndleSwAtv "BLN";
BA_ "SignalLongName" SG_ 2154225664 PasDrHndleSwAtv "Passenger Door Handle Switch Active";
BA_ "VNSigAllNodes" SG_ 2154225664 PasDrHndleSwAtv 1;
BA_ "GenSigSendType" SG_ 2154225664 DrvDrHndleSwAtv 10;
BA_ "SignalType" SG_ 2154225664 DrvDrHndleSwAtv "BLN";
BA_ "SignalLongName" SG_ 2154225664 DrvDrHndleSwAtv "Driver Door Handle Switch Active";
BA_ "VNSigAllNodes" SG_ 2154225664 DrvDrHndleSwAtv 1;
BA_ "GenSigSendType" SG_ 2149900288 BTTethrngPrngReq 10;
BA_ "SignalType" SG_ 2149900288 BTTethrngPrngReq "ENM";
BA_ "SignalLongName" SG_ 2149900288 BTTethrngPrngReq "Bluetooth Tethering Pairing Request";
BA_ "VNSigAllNodes" SG_ 2149900288 BTTethrngPrngReq 1;
BA_ "GenSigSendType" SG_ 2149900288 EnhSrvAudAlRq 10;
BA_ "SignalType" SG_ 2149900288 EnhSrvAudAlRq "ENM";
BA_ "SignalLongName" SG_ 2149900288 EnhSrvAudAlRq "Enhanced Services Audible External Alert Request";
BA_ "VNSigAllNodes" SG_ 2149900288 EnhSrvAudAlRq 1;
BA_ "GenSigDeltaValue" SG_ 2149900288 EnhSvVehTopSpdLim 1;
BA_ "GenSigSendType" SG_ 2149900288 EnhSvVehTopSpdLim 12;
BA_ "SignalType" SG_ 2149900288 EnhSvVehTopSpdLim "UNM";
BA_ "SignalLongName" SG_ 2149900288 EnhSvVehTopSpdLim "Enhanced Services Vehicle Top Speed Limit Value";
BA_ "GenSigStartValue" SG_ 2149900288 EnhSvVehTopSpdLim 255;
BA_ "VNSigAllNodes" SG_ 2149900288 EnhSvVehTopSpdLim 1;
BA_ "GenSigSendType" SG_ 2149900288 EnhSrvVisAlRq 10;
BA_ "GenSigSendOnInit" SG_ 2149900288 EnhSrvVisAlRq 1;
BA_ "SignalType" SG_ 2149900288 EnhSrvVisAlRq "ENM";
BA_ "SignalLongName" SG_ 2149900288 EnhSrvVisAlRq "Enhanced Services Visible External Alert Request";
BA_ "VNSigAllNodes" SG_ 2149900288 EnhSrvVisAlRq 1;
BA_ "GenSigSendType" SG_ 2149900288 EnhSrvRmStrtRq 10;
BA_ "SignalType" SG_ 2149900288 EnhSrvRmStrtRq "ENM";
BA_ "SignalLongName" SG_ 2149900288 EnhSrvRmStrtRq "Enhanced Services Remote Start Request";
BA_ "VNSigAllNodes" SG_ 2149900288 EnhSrvRmStrtRq 1;
BA_ "GenSigSendType" SG_ 2149900288 EnhSrvRClsRlsRq 10;
BA_ "SignalType" SG_ 2149900288 EnhSrvRClsRlsRq "ENM";
BA_ "SignalLongName" SG_ 2149900288 EnhSrvRClsRlsRq "Enhanced Services Rear Closure Release Request";
BA_ "VNSigAllNodes" SG_ 2149900288 EnhSrvRClsRlsRq 1;
BA_ "GenSigSendType" SG_ 2149900288 EnhSrvLckRq 10;
BA_ "SignalType" SG_ 2149900288 EnhSrvLckRq "ENM";
BA_ "SignalLongName" SG_ 2149900288 EnhSrvLckRq "Enhanced Services Locking Request";
BA_ "VNSigAllNodes" SG_ 2149900288 EnhSrvLckRq 1;
BA_ "GenSigDeltaValue" SG_ 2159001600 ODIEDDIPC_FUCID 1;
BA_ "GenSigSendType" SG_ 2159001600 ODIEDDIPC_FUCID 12;
BA_ "VNSigInfotainment" SG_ 2159001600 ODIEDDIPC_FUCID 1;
BA_ "SignalType" SG_ 2159001600 ODIEDDIPC_FUCID "UNM";
BA_ "PacketOrder" SG_ 2159001600 ODIEDDIPC_FUCID 19;
BA_ "SignalLongName" SG_ 2159001600 ODIEDDIPC_FUCID "Open Display Interface Enum Dynamic Data : Functional Unit Class ID";
BA_ "VNSigAllNodes" SG_ 2159001600 ODIEDDIPC_FUCID 1;
BA_ "GenSigDeltaValue" SG_ 2159001600 ODIEDDIPC_Data18Value 1;
BA_ "GenSigSendType" SG_ 2159001600 ODIEDDIPC_Data18Value 12;
BA_ "VNSigInfotainment" SG_ 2159001600 ODIEDDIPC_Data18Value 1;
BA_ "SignalType" SG_ 2159001600 ODIEDDIPC_Data18Value "UNM";
BA_ "PacketOrder" SG_ 2159001600 ODIEDDIPC_Data18Value 18;
BA_ "SignalLongName" SG_ 2159001600 ODIEDDIPC_Data18Value "Open Display Interface Enum Dynamic Data : Data ID 18";
BA_ "VNSigAllNodes" SG_ 2159001600 ODIEDDIPC_Data18Value 1;
BA_ "GenSigDeltaValue" SG_ 2159001600 ODIEDDIPC_Data17Value 1;
BA_ "GenSigSendType" SG_ 2159001600 ODIEDDIPC_Data17Value 12;
BA_ "VNSigInfotainment" SG_ 2159001600 ODIEDDIPC_Data17Value 1;
BA_ "SignalType" SG_ 2159001600 ODIEDDIPC_Data17Value "UNM";
BA_ "PacketOrder" SG_ 2159001600 ODIEDDIPC_Data17Value 17;
BA_ "SignalLongName" SG_ 2159001600 ODIEDDIPC_Data17Value "Open Display Interface Enum Dynamic Data : Data ID 17";
BA_ "VNSigAllNodes" SG_ 2159001600 ODIEDDIPC_Data17Value 1;
BA_ "GenSigDeltaValue" SG_ 2159001600 ODIEDDIPC_Data16Value 1;
BA_ "GenSigSendType" SG_ 2159001600 ODIEDDIPC_Data16Value 12;
BA_ "VNSigInfotainment" SG_ 2159001600 ODIEDDIPC_Data16Value 1;
BA_ "SignalType" SG_ 2159001600 ODIEDDIPC_Data16Value "UNM";
BA_ "PacketOrder" SG_ 2159001600 ODIEDDIPC_Data16Value 16;
BA_ "SignalLongName" SG_ 2159001600 ODIEDDIPC_Data16Value "Open Display Interface Enum Dynamic Data : Data ID 16";
BA_ "VNSigAllNodes" SG_ 2159001600 ODIEDDIPC_Data16Value 1;
BA_ "GenSigDeltaValue" SG_ 2159001600 ODIEDDIPC_Data15Value 1;
BA_ "GenSigSendType" SG_ 2159001600 ODIEDDIPC_Data15Value 12;
BA_ "VNSigInfotainment" SG_ 2159001600 ODIEDDIPC_Data15Value 1;
BA_ "SignalType" SG_ 2159001600 ODIEDDIPC_Data15Value "UNM";
BA_ "PacketOrder" SG_ 2159001600 ODIEDDIPC_Data15Value 15;
BA_ "SignalLongName" SG_ 2159001600 ODIEDDIPC_Data15Value "Open Display Interface Enum Dynamic Data : Data ID 15";
BA_ "VNSigAllNodes" SG_ 2159001600 ODIEDDIPC_Data15Value 1;
BA_ "GenSigDeltaValue" SG_ 2159001600 ODIEDDIPC_Data14Value 1;
BA_ "GenSigSendType" SG_ 2159001600 ODIEDDIPC_Data14Value 12;
BA_ "VNSigInfotainment" SG_ 2159001600 ODIEDDIPC_Data14Value 1;
BA_ "SignalType" SG_ 2159001600 ODIEDDIPC_Data14Value "UNM";
BA_ "PacketOrder" SG_ 2159001600 ODIEDDIPC_Data14Value 14;
BA_ "SignalLongName" SG_ 2159001600 ODIEDDIPC_Data14Value "Open Display Interface Enum Dynamic Data : Data ID 14";
BA_ "VNSigAllNodes" SG_ 2159001600 ODIEDDIPC_Data14Value 1;
BA_ "GenSigDeltaValue" SG_ 2159001600 ODIEDDIPC_Data13Value 1;
BA_ "GenSigSendType" SG_ 2159001600 ODIEDDIPC_Data13Value 12;
BA_ "VNSigInfotainment" SG_ 2159001600 ODIEDDIPC_Data13Value 1;
BA_ "SignalType" SG_ 2159001600 ODIEDDIPC_Data13Value "UNM";
BA_ "PacketOrder" SG_ 2159001600 ODIEDDIPC_Data13Value 13;
BA_ "SignalLongName" SG_ 2159001600 ODIEDDIPC_Data13Value "Open Display Interface Enum Dynamic Data : Data ID 13";
BA_ "VNSigAllNodes" SG_ 2159001600 ODIEDDIPC_Data13Value 1;
BA_ "GenSigDeltaValue" SG_ 2159001600 ODIEDDIPC_Data12Value 1;
BA_ "GenSigSendType" SG_ 2159001600 ODIEDDIPC_Data12Value 12;
BA_ "VNSigInfotainment" SG_ 2159001600 ODIEDDIPC_Data12Value 1;
BA_ "SignalType" SG_ 2159001600 ODIEDDIPC_Data12Value "UNM";
BA_ "PacketOrder" SG_ 2159001600 ODIEDDIPC_Data12Value 12;
BA_ "SignalLongName" SG_ 2159001600 ODIEDDIPC_Data12Value "Open Display Interface Enum Dynamic Data : Data ID 12";
BA_ "VNSigAllNodes" SG_ 2159001600 ODIEDDIPC_Data12Value 1;
BA_ "GenSigDeltaValue" SG_ 2159001600 ODIEDDIPC_Data11Value 1;
BA_ "GenSigSendType" SG_ 2159001600 ODIEDDIPC_Data11Value 12;
BA_ "VNSigInfotainment" SG_ 2159001600 ODIEDDIPC_Data11Value 1;
BA_ "SignalType" SG_ 2159001600 ODIEDDIPC_Data11Value "UNM";
BA_ "PacketOrder" SG_ 2159001600 ODIEDDIPC_Data11Value 11;
BA_ "SignalLongName" SG_ 2159001600 ODIEDDIPC_Data11Value "Open Display Interface Enum Dynamic Data : Data ID 11";
BA_ "VNSigAllNodes" SG_ 2159001600 ODIEDDIPC_Data11Value 1;
BA_ "GenSigDeltaValue" SG_ 2159001600 ODIEDDIPC_Data10Value 1;
BA_ "GenSigSendType" SG_ 2159001600 ODIEDDIPC_Data10Value 12;
BA_ "VNSigInfotainment" SG_ 2159001600 ODIEDDIPC_Data10Value 1;
BA_ "SignalType" SG_ 2159001600 ODIEDDIPC_Data10Value "UNM";
BA_ "PacketOrder" SG_ 2159001600 ODIEDDIPC_Data10Value 10;
BA_ "SignalLongName" SG_ 2159001600 ODIEDDIPC_Data10Value "Open Display Interface Enum Dynamic Data : Data ID 10";
BA_ "VNSigAllNodes" SG_ 2159001600 ODIEDDIPC_Data10Value 1;
BA_ "GenSigDeltaValue" SG_ 2159001600 ODIEDDIPC_Data9Value 1;
BA_ "GenSigSendType" SG_ 2159001600 ODIEDDIPC_Data9Value 12;
BA_ "VNSigInfotainment" SG_ 2159001600 ODIEDDIPC_Data9Value 1;
BA_ "SignalType" SG_ 2159001600 ODIEDDIPC_Data9Value "UNM";
BA_ "PacketOrder" SG_ 2159001600 ODIEDDIPC_Data9Value 9;
BA_ "SignalLongName" SG_ 2159001600 ODIEDDIPC_Data9Value "Open Display Interface Enum Dynamic Data : Data ID 9";
BA_ "VNSigAllNodes" SG_ 2159001600 ODIEDDIPC_Data9Value 1;
BA_ "GenSigDeltaValue" SG_ 2159001600 ODIEDDIPC_Data8Value 1;
BA_ "GenSigSendType" SG_ 2159001600 ODIEDDIPC_Data8Value 12;
BA_ "VNSigInfotainment" SG_ 2159001600 ODIEDDIPC_Data8Value 1;
BA_ "SignalType" SG_ 2159001600 ODIEDDIPC_Data8Value "UNM";
BA_ "PacketOrder" SG_ 2159001600 ODIEDDIPC_Data8Value 8;
BA_ "SignalLongName" SG_ 2159001600 ODIEDDIPC_Data8Value "Open Display Interface Enum Dynamic Data : Data ID 8";
BA_ "VNSigAllNodes" SG_ 2159001600 ODIEDDIPC_Data8Value 1;
BA_ "GenSigDeltaValue" SG_ 2159001600 ODIEDDIPC_Data7Value 1;
BA_ "GenSigSendType" SG_ 2159001600 ODIEDDIPC_Data7Value 12;
BA_ "VNSigInfotainment" SG_ 2159001600 ODIEDDIPC_Data7Value 1;
BA_ "SignalType" SG_ 2159001600 ODIEDDIPC_Data7Value "UNM";
BA_ "PacketOrder" SG_ 2159001600 ODIEDDIPC_Data7Value 7;
BA_ "SignalLongName" SG_ 2159001600 ODIEDDIPC_Data7Value "Open Display Interface Enum Dynamic Data : Data ID 7";
BA_ "VNSigAllNodes" SG_ 2159001600 ODIEDDIPC_Data7Value 1;
BA_ "GenSigDeltaValue" SG_ 2159001600 ODIEDDIPC_Data6Value 1;
BA_ "GenSigSendType" SG_ 2159001600 ODIEDDIPC_Data6Value 12;
BA_ "VNSigInfotainment" SG_ 2159001600 ODIEDDIPC_Data6Value 1;
BA_ "SignalType" SG_ 2159001600 ODIEDDIPC_Data6Value "UNM";
BA_ "PacketOrder" SG_ 2159001600 ODIEDDIPC_Data6Value 6;
BA_ "SignalLongName" SG_ 2159001600 ODIEDDIPC_Data6Value "Open Display Interface Enum Dynamic Data : Data ID 6";
BA_ "VNSigAllNodes" SG_ 2159001600 ODIEDDIPC_Data6Value 1;
BA_ "GenSigDeltaValue" SG_ 2159001600 ODIEDDIPC_Data5Value 1;
BA_ "GenSigSendType" SG_ 2159001600 ODIEDDIPC_Data5Value 12;
BA_ "VNSigInfotainment" SG_ 2159001600 ODIEDDIPC_Data5Value 1;
BA_ "SignalType" SG_ 2159001600 ODIEDDIPC_Data5Value "UNM";
BA_ "PacketOrder" SG_ 2159001600 ODIEDDIPC_Data5Value 5;
BA_ "SignalLongName" SG_ 2159001600 ODIEDDIPC_Data5Value "Open Display Interface Enum Dynamic Data : Data ID 5";
BA_ "VNSigAllNodes" SG_ 2159001600 ODIEDDIPC_Data5Value 1;
BA_ "GenSigDeltaValue" SG_ 2159001600 ODIEDDIPC_Data4Value 1;
BA_ "GenSigSendType" SG_ 2159001600 ODIEDDIPC_Data4Value 12;
BA_ "VNSigInfotainment" SG_ 2159001600 ODIEDDIPC_Data4Value 1;
BA_ "SignalType" SG_ 2159001600 ODIEDDIPC_Data4Value "UNM";
BA_ "PacketOrder" SG_ 2159001600 ODIEDDIPC_Data4Value 4;
BA_ "SignalLongName" SG_ 2159001600 ODIEDDIPC_Data4Value "Open Display Interface Enum Dynamic Data : Data ID 4";
BA_ "VNSigAllNodes" SG_ 2159001600 ODIEDDIPC_Data4Value 1;
BA_ "GenSigDeltaValue" SG_ 2159001600 ODIEDDIPC_Data3Value 1;
BA_ "GenSigSendType" SG_ 2159001600 ODIEDDIPC_Data3Value 12;
BA_ "VNSigInfotainment" SG_ 2159001600 ODIEDDIPC_Data3Value 1;
BA_ "SignalType" SG_ 2159001600 ODIEDDIPC_Data3Value "UNM";
BA_ "PacketOrder" SG_ 2159001600 ODIEDDIPC_Data3Value 3;
BA_ "SignalLongName" SG_ 2159001600 ODIEDDIPC_Data3Value "Open Display Interface Enum Dynamic Data : Data ID 3";
BA_ "VNSigAllNodes" SG_ 2159001600 ODIEDDIPC_Data3Value 1;
BA_ "GenSigDeltaValue" SG_ 2159001600 ODIEDDIPC_Data2Value 1;
BA_ "GenSigSendType" SG_ 2159001600 ODIEDDIPC_Data2Value 12;
BA_ "VNSigInfotainment" SG_ 2159001600 ODIEDDIPC_Data2Value 1;
BA_ "SignalType" SG_ 2159001600 ODIEDDIPC_Data2Value "UNM";
BA_ "PacketOrder" SG_ 2159001600 ODIEDDIPC_Data2Value 2;
BA_ "SignalLongName" SG_ 2159001600 ODIEDDIPC_Data2Value "Open Display Interface Enum Dynamic Data : Data ID 2";
BA_ "VNSigAllNodes" SG_ 2159001600 ODIEDDIPC_Data2Value 1;
BA_ "GenSigDeltaValue" SG_ 2159001600 ODIEDDIPC_Data1Value 1;
BA_ "GenSigSendType" SG_ 2159001600 ODIEDDIPC_Data1Value 12;
BA_ "VNSigInfotainment" SG_ 2159001600 ODIEDDIPC_Data1Value 1;
BA_ "SignalType" SG_ 2159001600 ODIEDDIPC_Data1Value "UNM";
BA_ "PacketOrder" SG_ 2159001600 ODIEDDIPC_Data1Value 1;
BA_ "SignalLongName" SG_ 2159001600 ODIEDDIPC_Data1Value "Open Display Interface Enum Dynamic Data : Data ID 1";
BA_ "VNSigAllNodes" SG_ 2159001600 ODIEDDIPC_Data1Value 1;
BA_ "GenSigDeltaValue" SG_ 2158993408 ODIEDDCS_FUCID 1;
BA_ "GenSigSendType" SG_ 2158993408 ODIEDDCS_FUCID 12;
BA_ "GenSigSendOnInit" SG_ 2158993408 ODIEDDCS_FUCID 1;
BA_ "VNSigInfotainment" SG_ 2158993408 ODIEDDCS_FUCID 1;
BA_ "SignalType" SG_ 2158993408 ODIEDDCS_FUCID "UNM";
BA_ "PacketOrder" SG_ 2158993408 ODIEDDCS_FUCID 19;
BA_ "SignalLongName" SG_ 2158993408 ODIEDDCS_FUCID "Open Display Interface Enum Dynamic Data : Functional Unit Class ID";
BA_ "VNSigAllNodes" SG_ 2158993408 ODIEDDCS_FUCID 1;
BA_ "GenSigDeltaValue" SG_ 2158993408 ODIEDDCS_Data9Value 1;
BA_ "GenSigSendType" SG_ 2158993408 ODIEDDCS_Data9Value 12;
BA_ "GenSigSendOnInit" SG_ 2158993408 ODIEDDCS_Data9Value 1;
BA_ "VNSigInfotainment" SG_ 2158993408 ODIEDDCS_Data9Value 1;
BA_ "SignalType" SG_ 2158993408 ODIEDDCS_Data9Value "UNM";
BA_ "PacketOrder" SG_ 2158993408 ODIEDDCS_Data9Value 9;
BA_ "SignalLongName" SG_ 2158993408 ODIEDDCS_Data9Value "Open Display Interface Enum Dynamic Data : Data ID 9";
BA_ "VNSigAllNodes" SG_ 2158993408 ODIEDDCS_Data9Value 1;
BA_ "GenSigDeltaValue" SG_ 2158993408 ODIEDDCS_Data8Value 1;
BA_ "GenSigSendType" SG_ 2158993408 ODIEDDCS_Data8Value 12;
BA_ "GenSigSendOnInit" SG_ 2158993408 ODIEDDCS_Data8Value 1;
BA_ "VNSigInfotainment" SG_ 2158993408 ODIEDDCS_Data8Value 1;
BA_ "SignalType" SG_ 2158993408 ODIEDDCS_Data8Value "UNM";
BA_ "PacketOrder" SG_ 2158993408 ODIEDDCS_Data8Value 8;
BA_ "SignalLongName" SG_ 2158993408 ODIEDDCS_Data8Value "Open Display Interface Enum Dynamic Data : Data ID 8";
BA_ "VNSigAllNodes" SG_ 2158993408 ODIEDDCS_Data8Value 1;
BA_ "GenSigDeltaValue" SG_ 2158993408 ODIEDDCS_Data7Value 1;
BA_ "GenSigSendType" SG_ 2158993408 ODIEDDCS_Data7Value 12;
BA_ "GenSigSendOnInit" SG_ 2158993408 ODIEDDCS_Data7Value 1;
BA_ "VNSigInfotainment" SG_ 2158993408 ODIEDDCS_Data7Value 1;
BA_ "SignalType" SG_ 2158993408 ODIEDDCS_Data7Value "UNM";
BA_ "PacketOrder" SG_ 2158993408 ODIEDDCS_Data7Value 7;
BA_ "SignalLongName" SG_ 2158993408 ODIEDDCS_Data7Value "Open Display Interface Enum Dynamic Data : Data ID 7";
BA_ "VNSigAllNodes" SG_ 2158993408 ODIEDDCS_Data7Value 1;
BA_ "GenSigDeltaValue" SG_ 2158993408 ODIEDDCS_Data6Value 1;
BA_ "GenSigSendType" SG_ 2158993408 ODIEDDCS_Data6Value 12;
BA_ "GenSigSendOnInit" SG_ 2158993408 ODIEDDCS_Data6Value 1;
BA_ "VNSigInfotainment" SG_ 2158993408 ODIEDDCS_Data6Value 1;
BA_ "SignalType" SG_ 2158993408 ODIEDDCS_Data6Value "UNM";
BA_ "PacketOrder" SG_ 2158993408 ODIEDDCS_Data6Value 6;
BA_ "SignalLongName" SG_ 2158993408 ODIEDDCS_Data6Value "Open Display Interface Enum Dynamic Data : Data ID 6";
BA_ "VNSigAllNodes" SG_ 2158993408 ODIEDDCS_Data6Value 1;
BA_ "GenSigDeltaValue" SG_ 2158993408 ODIEDDCS_Data5Value 1;
BA_ "GenSigSendType" SG_ 2158993408 ODIEDDCS_Data5Value 12;
BA_ "GenSigSendOnInit" SG_ 2158993408 ODIEDDCS_Data5Value 1;
BA_ "VNSigInfotainment" SG_ 2158993408 ODIEDDCS_Data5Value 1;
BA_ "SignalType" SG_ 2158993408 ODIEDDCS_Data5Value "UNM";
BA_ "PacketOrder" SG_ 2158993408 ODIEDDCS_Data5Value 5;
BA_ "SignalLongName" SG_ 2158993408 ODIEDDCS_Data5Value "Open Display Interface Enum Dynamic Data : Data ID 5";
BA_ "VNSigAllNodes" SG_ 2158993408 ODIEDDCS_Data5Value 1;
BA_ "GenSigDeltaValue" SG_ 2158993408 ODIEDDCS_Data4Value 1;
BA_ "GenSigSendType" SG_ 2158993408 ODIEDDCS_Data4Value 12;
BA_ "GenSigSendOnInit" SG_ 2158993408 ODIEDDCS_Data4Value 1;
BA_ "VNSigInfotainment" SG_ 2158993408 ODIEDDCS_Data4Value 1;
BA_ "SignalType" SG_ 2158993408 ODIEDDCS_Data4Value "UNM";
BA_ "PacketOrder" SG_ 2158993408 ODIEDDCS_Data4Value 4;
BA_ "SignalLongName" SG_ 2158993408 ODIEDDCS_Data4Value "Open Display Interface Enum Dynamic Data : Data ID 4";
BA_ "VNSigAllNodes" SG_ 2158993408 ODIEDDCS_Data4Value 1;
BA_ "GenSigDeltaValue" SG_ 2158993408 ODIEDDCS_Data3Value 1;
BA_ "GenSigSendType" SG_ 2158993408 ODIEDDCS_Data3Value 12;
BA_ "GenSigSendOnInit" SG_ 2158993408 ODIEDDCS_Data3Value 1;
BA_ "VNSigInfotainment" SG_ 2158993408 ODIEDDCS_Data3Value 1;
BA_ "SignalType" SG_ 2158993408 ODIEDDCS_Data3Value "UNM";
BA_ "PacketOrder" SG_ 2158993408 ODIEDDCS_Data3Value 3;
BA_ "SignalLongName" SG_ 2158993408 ODIEDDCS_Data3Value "Open Display Interface Enum Dynamic Data : Data ID 3";
BA_ "VNSigAllNodes" SG_ 2158993408 ODIEDDCS_Data3Value 1;
BA_ "GenSigDeltaValue" SG_ 2158993408 ODIEDDCS_Data2Value 1;
BA_ "GenSigSendType" SG_ 2158993408 ODIEDDCS_Data2Value 12;
BA_ "GenSigSendOnInit" SG_ 2158993408 ODIEDDCS_Data2Value 1;
BA_ "VNSigInfotainment" SG_ 2158993408 ODIEDDCS_Data2Value 1;
BA_ "SignalType" SG_ 2158993408 ODIEDDCS_Data2Value "UNM";
BA_ "PacketOrder" SG_ 2158993408 ODIEDDCS_Data2Value 2;
BA_ "SignalLongName" SG_ 2158993408 ODIEDDCS_Data2Value "Open Display Interface Enum Dynamic Data : Data ID 2";
BA_ "VNSigAllNodes" SG_ 2158993408 ODIEDDCS_Data2Value 1;
BA_ "GenSigDeltaValue" SG_ 2158993408 ODIEDDCS_Data18Value 1;
BA_ "GenSigSendType" SG_ 2158993408 ODIEDDCS_Data18Value 12;
BA_ "GenSigSendOnInit" SG_ 2158993408 ODIEDDCS_Data18Value 1;
BA_ "VNSigInfotainment" SG_ 2158993408 ODIEDDCS_Data18Value 1;
BA_ "SignalType" SG_ 2158993408 ODIEDDCS_Data18Value "UNM";
BA_ "PacketOrder" SG_ 2158993408 ODIEDDCS_Data18Value 18;
BA_ "SignalLongName" SG_ 2158993408 ODIEDDCS_Data18Value "Open Display Interface Enum Dynamic Data : Data ID 18";
BA_ "VNSigAllNodes" SG_ 2158993408 ODIEDDCS_Data18Value 1;
BA_ "GenSigDeltaValue" SG_ 2158993408 ODIEDDCS_Data17Value 1;
BA_ "GenSigSendType" SG_ 2158993408 ODIEDDCS_Data17Value 12;
BA_ "GenSigSendOnInit" SG_ 2158993408 ODIEDDCS_Data17Value 1;
BA_ "VNSigInfotainment" SG_ 2158993408 ODIEDDCS_Data17Value 1;
BA_ "SignalType" SG_ 2158993408 ODIEDDCS_Data17Value "UNM";
BA_ "PacketOrder" SG_ 2158993408 ODIEDDCS_Data17Value 17;
BA_ "SignalLongName" SG_ 2158993408 ODIEDDCS_Data17Value "Open Display Interface Enum Dynamic Data : Data ID 17";
BA_ "VNSigAllNodes" SG_ 2158993408 ODIEDDCS_Data17Value 1;
BA_ "GenSigDeltaValue" SG_ 2158993408 ODIEDDCS_Data16Value 1;
BA_ "GenSigSendType" SG_ 2158993408 ODIEDDCS_Data16Value 12;
BA_ "GenSigSendOnInit" SG_ 2158993408 ODIEDDCS_Data16Value 1;
BA_ "VNSigInfotainment" SG_ 2158993408 ODIEDDCS_Data16Value 1;
BA_ "SignalType" SG_ 2158993408 ODIEDDCS_Data16Value "UNM";
BA_ "PacketOrder" SG_ 2158993408 ODIEDDCS_Data16Value 16;
BA_ "SignalLongName" SG_ 2158993408 ODIEDDCS_Data16Value "Open Display Interface Enum Dynamic Data : Data ID 16";
BA_ "VNSigAllNodes" SG_ 2158993408 ODIEDDCS_Data16Value 1;
BA_ "GenSigDeltaValue" SG_ 2158993408 ODIEDDCS_Data15Value 1;
BA_ "GenSigSendType" SG_ 2158993408 ODIEDDCS_Data15Value 12;
BA_ "GenSigSendOnInit" SG_ 2158993408 ODIEDDCS_Data15Value 1;
BA_ "VNSigInfotainment" SG_ 2158993408 ODIEDDCS_Data15Value 1;
BA_ "SignalType" SG_ 2158993408 ODIEDDCS_Data15Value "UNM";
BA_ "PacketOrder" SG_ 2158993408 ODIEDDCS_Data15Value 15;
BA_ "SignalLongName" SG_ 2158993408 ODIEDDCS_Data15Value "Open Display Interface Enum Dynamic Data : Data ID 15";
BA_ "VNSigAllNodes" SG_ 2158993408 ODIEDDCS_Data15Value 1;
BA_ "GenSigDeltaValue" SG_ 2158993408 ODIEDDCS_Data14Value 1;
BA_ "GenSigSendType" SG_ 2158993408 ODIEDDCS_Data14Value 12;
BA_ "GenSigSendOnInit" SG_ 2158993408 ODIEDDCS_Data14Value 1;
BA_ "VNSigInfotainment" SG_ 2158993408 ODIEDDCS_Data14Value 1;
BA_ "SignalType" SG_ 2158993408 ODIEDDCS_Data14Value "UNM";
BA_ "PacketOrder" SG_ 2158993408 ODIEDDCS_Data14Value 14;
BA_ "SignalLongName" SG_ 2158993408 ODIEDDCS_Data14Value "Open Display Interface Enum Dynamic Data : Data ID 14";
BA_ "VNSigAllNodes" SG_ 2158993408 ODIEDDCS_Data14Value 1;
BA_ "GenSigDeltaValue" SG_ 2158993408 ODIEDDCS_Data13Value 1;
BA_ "GenSigSendType" SG_ 2158993408 ODIEDDCS_Data13Value 12;
BA_ "GenSigSendOnInit" SG_ 2158993408 ODIEDDCS_Data13Value 1;
BA_ "VNSigInfotainment" SG_ 2158993408 ODIEDDCS_Data13Value 1;
BA_ "SignalType" SG_ 2158993408 ODIEDDCS_Data13Value "UNM";
BA_ "PacketOrder" SG_ 2158993408 ODIEDDCS_Data13Value 13;
BA_ "SignalLongName" SG_ 2158993408 ODIEDDCS_Data13Value "Open Display Interface Enum Dynamic Data : Data ID 13";
BA_ "VNSigAllNodes" SG_ 2158993408 ODIEDDCS_Data13Value 1;
BA_ "GenSigDeltaValue" SG_ 2158993408 ODIEDDCS_Data12Value 1;
BA_ "GenSigSendType" SG_ 2158993408 ODIEDDCS_Data12Value 12;
BA_ "GenSigSendOnInit" SG_ 2158993408 ODIEDDCS_Data12Value 1;
BA_ "VNSigInfotainment" SG_ 2158993408 ODIEDDCS_Data12Value 1;
BA_ "SignalType" SG_ 2158993408 ODIEDDCS_Data12Value "UNM";
BA_ "PacketOrder" SG_ 2158993408 ODIEDDCS_Data12Value 12;
BA_ "SignalLongName" SG_ 2158993408 ODIEDDCS_Data12Value "Open Display Interface Enum Dynamic Data : Data ID 12";
BA_ "VNSigAllNodes" SG_ 2158993408 ODIEDDCS_Data12Value 1;
BA_ "GenSigDeltaValue" SG_ 2158993408 ODIEDDCS_Data11Value 1;
BA_ "GenSigSendType" SG_ 2158993408 ODIEDDCS_Data11Value 12;
BA_ "GenSigSendOnInit" SG_ 2158993408 ODIEDDCS_Data11Value 1;
BA_ "VNSigInfotainment" SG_ 2158993408 ODIEDDCS_Data11Value 1;
BA_ "SignalType" SG_ 2158993408 ODIEDDCS_Data11Value "UNM";
BA_ "PacketOrder" SG_ 2158993408 ODIEDDCS_Data11Value 11;
BA_ "SignalLongName" SG_ 2158993408 ODIEDDCS_Data11Value "Open Display Interface Enum Dynamic Data : Data ID 11";
BA_ "VNSigAllNodes" SG_ 2158993408 ODIEDDCS_Data11Value 1;
BA_ "GenSigDeltaValue" SG_ 2158993408 ODIEDDCS_Data10Value 1;
BA_ "GenSigSendType" SG_ 2158993408 ODIEDDCS_Data10Value 12;
BA_ "GenSigSendOnInit" SG_ 2158993408 ODIEDDCS_Data10Value 1;
BA_ "VNSigInfotainment" SG_ 2158993408 ODIEDDCS_Data10Value 1;
BA_ "SignalType" SG_ 2158993408 ODIEDDCS_Data10Value "UNM";
BA_ "PacketOrder" SG_ 2158993408 ODIEDDCS_Data10Value 10;
BA_ "SignalLongName" SG_ 2158993408 ODIEDDCS_Data10Value "Open Display Interface Enum Dynamic Data : Data ID 10";
BA_ "VNSigAllNodes" SG_ 2158993408 ODIEDDCS_Data10Value 1;
BA_ "GenSigDeltaValue" SG_ 2158993408 ODIEDDCS_Data1Value 1;
BA_ "GenSigSendType" SG_ 2158993408 ODIEDDCS_Data1Value 12;
BA_ "GenSigSendOnInit" SG_ 2158993408 ODIEDDCS_Data1Value 1;
BA_ "VNSigInfotainment" SG_ 2158993408 ODIEDDCS_Data1Value 1;
BA_ "SignalType" SG_ 2158993408 ODIEDDCS_Data1Value "UNM";
BA_ "PacketOrder" SG_ 2158993408 ODIEDDCS_Data1Value 1;
BA_ "SignalLongName" SG_ 2158993408 ODIEDDCS_Data1Value "Open Display Interface Enum Dynamic Data : Data ID 1";
BA_ "VNSigAllNodes" SG_ 2158993408 ODIEDDCS_Data1Value 1;
BA_ "GenSigSendType" SG_ 2154708992 ASS2AudSrcStatCode 10;
BA_ "VNSigInfotainment" SG_ 2154708992 ASS2AudSrcStatCode 1;
BA_ "SignalType" SG_ 2154708992 ASS2AudSrcStatCode "ENM";
BA_ "PacketOrder" SG_ 2154708992 ASS2AudSrcStatCode 3;
BA_ "SignalLongName" SG_ 2154708992 ASS2AudSrcStatCode "Audio Source Status 2 : Audio Source Status Code";
BA_ "VNSigAllNodes" SG_ 2154708992 ASS2AudSrcStatCode 1;
BA_ "GenSigSendType" SG_ 2154708992 ASS2AudSrcChType 10;
BA_ "VNSigInfotainment" SG_ 2154708992 ASS2AudSrcChType 1;
BA_ "SignalType" SG_ 2154708992 ASS2AudSrcChType "ENM";
BA_ "PacketOrder" SG_ 2154708992 ASS2AudSrcChType 2;
BA_ "SignalLongName" SG_ 2154708992 ASS2AudSrcChType "Audio Source Status 2 : Audio Source Channel Type";
BA_ "VNSigAllNodes" SG_ 2154708992 ASS2AudSrcChType 1;
BA_ "GenSigSendType" SG_ 2154708992 ASS2AudSrcType 10;
BA_ "VNSigInfotainment" SG_ 2154708992 ASS2AudSrcType 1;
BA_ "SignalType" SG_ 2154708992 ASS2AudSrcType "ENM";
BA_ "PacketOrder" SG_ 2154708992 ASS2AudSrcType 1;
BA_ "SignalLongName" SG_ 2154708992 ASS2AudSrcType "Audio Source Status 2 : Audio Source Type";
BA_ "VNSigAllNodes" SG_ 2154708992 ASS2AudSrcType 1;
BA_ "GenSigSendType" SG_ 2158985216 ODDMO_ReqType 10;
BA_ "VNSigInfotainment" SG_ 2158985216 ODDMO_ReqType 1;
BA_ "SignalType" SG_ 2158985216 ODDMO_ReqType "ENM";
BA_ "PacketOrder" SG_ 2158985216 ODDMO_ReqType 1;
BA_ "SignalLongName" SG_ 2158985216 ODDMO_ReqType "Open Display Interface Dynamic Data Multi Request OTIM : Request Type";
BA_ "VNSigAllNodes" SG_ 2158985216 ODDMO_ReqType 1;
BA_ "GenSigDeltaValue" SG_ 2158985216 ODDMO_FUCID 1;
BA_ "GenSigSendType" SG_ 2158985216 ODDMO_FUCID 12;
BA_ "VNSigInfotainment" SG_ 2158985216 ODDMO_FUCID 1;
BA_ "SignalType" SG_ 2158985216 ODDMO_FUCID "UNM";
BA_ "PacketOrder" SG_ 2158985216 ODDMO_FUCID 6;
BA_ "SignalLongName" SG_ 2158985216 ODDMO_FUCID "Open Display Interface Dynamic Data Multi Request OTIM : Functional Unit Class ID";
BA_ "VNSigAllNodes" SG_ 2158985216 ODDMO_FUCID 1;
BA_ "GenSigSendType" SG_ 2158985216 ODDMO_DispMID 10;
BA_ "VNSigInfotainment" SG_ 2158985216 ODDMO_DispMID 1;
BA_ "SignalType" SG_ 2158985216 ODDMO_DispMID "ENM";
BA_ "PacketOrder" SG_ 2158985216 ODDMO_DispMID 7;
BA_ "SignalLongName" SG_ 2158985216 ODDMO_DispMID "Open Display Interface Dynamic Data Multi Request OTIM : Display Mask Id";
BA_ "VNSigAllNodes" SG_ 2158985216 ODDMO_DispMID 1;
BA_ "GenSigSendType" SG_ 2158985216 ODDMO_DataID2Vld 10;
BA_ "VNSigInfotainment" SG_ 2158985216 ODDMO_DataID2Vld 1;
BA_ "SignalType" SG_ 2158985216 ODDMO_DataID2Vld "BLN";
BA_ "PacketOrder" SG_ 2158985216 ODDMO_DataID2Vld 5;
BA_ "SignalLongName" SG_ 2158985216 ODDMO_DataID2Vld "Open Display Interface Dynamic Data Multi Request OTIM : Data ID Two Valid";
BA_ "VNSigAllNodes" SG_ 2158985216 ODDMO_DataID2Vld 1;
BA_ "GenSigDeltaValue" SG_ 2158985216 ODDMO_DataID2 1;
BA_ "GenSigSendType" SG_ 2158985216 ODDMO_DataID2 12;
BA_ "VNSigInfotainment" SG_ 2158985216 ODDMO_DataID2 1;
BA_ "SignalType" SG_ 2158985216 ODDMO_DataID2 "UNM";
BA_ "PacketOrder" SG_ 2158985216 ODDMO_DataID2 9;
BA_ "SignalLongName" SG_ 2158985216 ODDMO_DataID2 "Open Display Interface Dynamic Data Multi Request OTIM : Data ID Two";
BA_ "VNSigAllNodes" SG_ 2158985216 ODDMO_DataID2 1;
BA_ "GenSigSendType" SG_ 2158985216 ODDMO_DataID3Vld 10;
BA_ "VNSigInfotainment" SG_ 2158985216 ODDMO_DataID3Vld 1;
BA_ "SignalType" SG_ 2158985216 ODDMO_DataID3Vld "BLN";
BA_ "PacketOrder" SG_ 2158985216 ODDMO_DataID3Vld 4;
BA_ "SignalLongName" SG_ 2158985216 ODDMO_DataID3Vld "Open Display Interface Dynamic Data Multi Request OTIM : Data ID Three Valid";
BA_ "VNSigAllNodes" SG_ 2158985216 ODDMO_DataID3Vld 1;
BA_ "GenSigDeltaValue" SG_ 2158985216 ODDMO_DataID3 1;
BA_ "GenSigSendType" SG_ 2158985216 ODDMO_DataID3 12;
BA_ "VNSigInfotainment" SG_ 2158985216 ODDMO_DataID3 1;
BA_ "SignalType" SG_ 2158985216 ODDMO_DataID3 "UNM";
BA_ "PacketOrder" SG_ 2158985216 ODDMO_DataID3 10;
BA_ "SignalLongName" SG_ 2158985216 ODDMO_DataID3 "Open Display Interface Dynamic Data Multi Request OTIM : Data ID Three";
BA_ "VNSigAllNodes" SG_ 2158985216 ODDMO_DataID3 1;
BA_ "GenSigDeltaValue" SG_ 2158985216 ODDMO_DataID1 1;
BA_ "GenSigSendType" SG_ 2158985216 ODDMO_DataID1 12;
BA_ "VNSigInfotainment" SG_ 2158985216 ODDMO_DataID1 1;
BA_ "SignalType" SG_ 2158985216 ODDMO_DataID1 "UNM";
BA_ "PacketOrder" SG_ 2158985216 ODDMO_DataID1 8;
BA_ "SignalLongName" SG_ 2158985216 ODDMO_DataID1 "Open Display Interface Dynamic Data Multi Request OTIM : Data ID One";
BA_ "VNSigAllNodes" SG_ 2158985216 ODDMO_DataID1 1;
BA_ "GenSigSendType" SG_ 2158985216 ODDMO_DataID4Vld 10;
BA_ "VNSigInfotainment" SG_ 2158985216 ODDMO_DataID4Vld 1;
BA_ "SignalType" SG_ 2158985216 ODDMO_DataID4Vld "BLN";
BA_ "PacketOrder" SG_ 2158985216 ODDMO_DataID4Vld 3;
BA_ "SignalLongName" SG_ 2158985216 ODDMO_DataID4Vld "Open Display Interface Dynamic Data Multi Request OTIM : Data ID Four Valid";
BA_ "VNSigAllNodes" SG_ 2158985216 ODDMO_DataID4Vld 1;
BA_ "GenSigDeltaValue" SG_ 2158985216 ODDMO_DataID4 1;
BA_ "GenSigSendType" SG_ 2158985216 ODDMO_DataID4 12;
BA_ "VNSigInfotainment" SG_ 2158985216 ODDMO_DataID4 1;
BA_ "SignalType" SG_ 2158985216 ODDMO_DataID4 "UNM";
BA_ "PacketOrder" SG_ 2158985216 ODDMO_DataID4 11;
BA_ "SignalLongName" SG_ 2158985216 ODDMO_DataID4 "Open Display Interface Dynamic Data Multi Request OTIM : Data ID Four";
BA_ "VNSigAllNodes" SG_ 2158985216 ODDMO_DataID4 1;
BA_ "GenSigSendType" SG_ 2158985216 ODDMO_DataID5Vld 10;
BA_ "VNSigInfotainment" SG_ 2158985216 ODDMO_DataID5Vld 1;
BA_ "SignalType" SG_ 2158985216 ODDMO_DataID5Vld "BLN";
BA_ "PacketOrder" SG_ 2158985216 ODDMO_DataID5Vld 2;
BA_ "SignalLongName" SG_ 2158985216 ODDMO_DataID5Vld "Open Display Interface Dynamic Data Multi Request OTIM : Data ID Five Valid";
BA_ "VNSigAllNodes" SG_ 2158985216 ODDMO_DataID5Vld 1;
BA_ "GenSigDeltaValue" SG_ 2158985216 ODDMO_DataID5 1;
BA_ "GenSigSendType" SG_ 2158985216 ODDMO_DataID5 12;
BA_ "VNSigInfotainment" SG_ 2158985216 ODDMO_DataID5 1;
BA_ "SignalType" SG_ 2158985216 ODDMO_DataID5 "UNM";
BA_ "PacketOrder" SG_ 2158985216 ODDMO_DataID5 12;
BA_ "SignalLongName" SG_ 2158985216 ODDMO_DataID5 "Open Display Interface Dynamic Data Multi Request OTIM : Data ID Five";
BA_ "VNSigAllNodes" SG_ 2158985216 ODDMO_DataID5 1;
BA_ "GenSigSendType" SG_ 2154471424 RrClsrSnwLdIO 10;
BA_ "SignalType" SG_ 2154471424 RrClsrSnwLdIO "BLN";
BA_ "SignalLongName" SG_ 2154471424 RrClsrSnwLdIO "Rear Closure Snow Load Indication On";
BA_ "VNSigAllNodes" SG_ 2154471424 RrClsrSnwLdIO 1;
BA_ "GenSigSendType" SG_ 2154471424 RrClosAjarSwAct 10;
BA_ "GenSigSendOnInit" SG_ 2154471424 RrClosAjarSwAct 1;
BA_ "SignalType" SG_ 2154471424 RrClosAjarSwAct "BLN";
BA_ "SignalLongName" SG_ 2154471424 RrClosAjarSwAct "Rear Closure Ajar Switch Active";
BA_ "VNSigAllNodes" SG_ 2154471424 RrClosAjarSwAct 1;
BA_ "GenSigDeltaValue" SG_ 2159149056 ODI_TEL2CntrStck 1;
BA_ "GenSigSendType" SG_ 2159149056 ODI_TEL2CntrStck 12;
BA_ "VNSigInfotainment" SG_ 2159149056 ODI_TEL2CntrStck 1;
BA_ "SignalType" SG_ 2159149056 ODI_TEL2CntrStck "UNM";
BA_ "SignalLongName" SG_ 2159149056 ODI_TEL2CntrStck "Open Display Interface TEL 2 CenterStack";
BA_ "VNSigAllNodes" SG_ 2159149056 ODI_TEL2CntrStck 1;
BA_ "GenSigDeltaValue" SG_ 2159116288 ODI_TEL2AxIP 1;
BA_ "GenSigSendType" SG_ 2159116288 ODI_TEL2AxIP 12;
BA_ "VNSigInfotainment" SG_ 2159116288 ODI_TEL2AxIP 1;
BA_ "SignalType" SG_ 2159116288 ODI_TEL2AxIP "UNM";
BA_ "SignalLongName" SG_ 2159116288 ODI_TEL2AxIP "Open Display Interface TEL 2 AuxIP";
BA_ "VNSigAllNodes" SG_ 2159116288 ODI_TEL2AxIP 1;
BA_ "GenSigSendType" SG_ 2158796800 ODII_ODIInd55 10;
BA_ "GenSigSendOnInit" SG_ 2158796800 ODII_ODIInd55 1;
BA_ "VNSigInfotainment" SG_ 2158796800 ODII_ODIInd55 1;
BA_ "SignalType" SG_ 2158796800 ODII_ODIInd55 "BLN";
BA_ "PacketOrder" SG_ 2158796800 ODII_ODIInd55 56;
BA_ "SignalLongName" SG_ 2158796800 ODII_ODIInd55 "Open Display Interface Indication : Open Display Interface Indication 55";
BA_ "VNSigAllNodes" SG_ 2158796800 ODII_ODIInd55 1;
BA_ "GenSigSendType" SG_ 2158796800 ODII_ODIInd54 10;
BA_ "GenSigSendOnInit" SG_ 2158796800 ODII_ODIInd54 1;
BA_ "VNSigInfotainment" SG_ 2158796800 ODII_ODIInd54 1;
BA_ "SignalType" SG_ 2158796800 ODII_ODIInd54 "BLN";
BA_ "PacketOrder" SG_ 2158796800 ODII_ODIInd54 55;
BA_ "SignalLongName" SG_ 2158796800 ODII_ODIInd54 "Open Display Interface Indication : Open Display Interface Indication 54";
BA_ "VNSigAllNodes" SG_ 2158796800 ODII_ODIInd54 1;
BA_ "GenSigSendType" SG_ 2158796800 ODII_ODIInd53 10;
BA_ "GenSigSendOnInit" SG_ 2158796800 ODII_ODIInd53 1;
BA_ "VNSigInfotainment" SG_ 2158796800 ODII_ODIInd53 1;
BA_ "SignalType" SG_ 2158796800 ODII_ODIInd53 "BLN";
BA_ "PacketOrder" SG_ 2158796800 ODII_ODIInd53 54;
BA_ "SignalLongName" SG_ 2158796800 ODII_ODIInd53 "Open Display Interface Indication : Open Display Interface Indication 53";
BA_ "VNSigAllNodes" SG_ 2158796800 ODII_ODIInd53 1;
BA_ "GenSigSendType" SG_ 2158796800 ODII_ODIInd52 10;
BA_ "GenSigSendOnInit" SG_ 2158796800 ODII_ODIInd52 1;
BA_ "VNSigInfotainment" SG_ 2158796800 ODII_ODIInd52 1;
BA_ "SignalType" SG_ 2158796800 ODII_ODIInd52 "BLN";
BA_ "PacketOrder" SG_ 2158796800 ODII_ODIInd52 53;
BA_ "SignalLongName" SG_ 2158796800 ODII_ODIInd52 "Open Display Interface Indication : Open Display Interface Indication 52";
BA_ "VNSigAllNodes" SG_ 2158796800 ODII_ODIInd52 1;
BA_ "GenSigSendType" SG_ 2158796800 ODII_ODIInd51 10;
BA_ "GenSigSendOnInit" SG_ 2158796800 ODII_ODIInd51 1;
BA_ "VNSigInfotainment" SG_ 2158796800 ODII_ODIInd51 1;
BA_ "SignalType" SG_ 2158796800 ODII_ODIInd51 "BLN";
BA_ "PacketOrder" SG_ 2158796800 ODII_ODIInd51 52;
BA_ "SignalLongName" SG_ 2158796800 ODII_ODIInd51 "Open Display Interface Indication : Open Display Interface Indication 51";
BA_ "VNSigAllNodes" SG_ 2158796800 ODII_ODIInd51 1;
BA_ "GenSigSendType" SG_ 2158796800 ODII_ODIInd50 10;
BA_ "GenSigSendOnInit" SG_ 2158796800 ODII_ODIInd50 1;
BA_ "VNSigInfotainment" SG_ 2158796800 ODII_ODIInd50 1;
BA_ "SignalType" SG_ 2158796800 ODII_ODIInd50 "BLN";
BA_ "PacketOrder" SG_ 2158796800 ODII_ODIInd50 51;
BA_ "SignalLongName" SG_ 2158796800 ODII_ODIInd50 "Open Display Interface Indication : Open Display Interface Indication 50";
BA_ "VNSigAllNodes" SG_ 2158796800 ODII_ODIInd50 1;
BA_ "GenSigSendType" SG_ 2158796800 ODII_ODIInd27 10;
BA_ "GenSigSendOnInit" SG_ 2158796800 ODII_ODIInd27 1;
BA_ "VNSigInfotainment" SG_ 2158796800 ODII_ODIInd27 1;
BA_ "SignalType" SG_ 2158796800 ODII_ODIInd27 "BLN";
BA_ "PacketOrder" SG_ 2158796800 ODII_ODIInd27 28;
BA_ "SignalLongName" SG_ 2158796800 ODII_ODIInd27 "Open Display Interface Indication : Open Display Interface Indication 27";
BA_ "VNSigAllNodes" SG_ 2158796800 ODII_ODIInd27 1;
BA_ "GenSigSendType" SG_ 2158796800 ODII_ODIInd26 10;
BA_ "GenSigSendOnInit" SG_ 2158796800 ODII_ODIInd26 1;
BA_ "VNSigInfotainment" SG_ 2158796800 ODII_ODIInd26 1;
BA_ "SignalType" SG_ 2158796800 ODII_ODIInd26 "BLN";
BA_ "PacketOrder" SG_ 2158796800 ODII_ODIInd26 27;
BA_ "SignalLongName" SG_ 2158796800 ODII_ODIInd26 "Open Display Interface Indication : Open Display Interface Indication 26";
BA_ "VNSigAllNodes" SG_ 2158796800 ODII_ODIInd26 1;
BA_ "GenSigSendType" SG_ 2158796800 ODII_ODIInd25 10;
BA_ "GenSigSendOnInit" SG_ 2158796800 ODII_ODIInd25 1;
BA_ "VNSigInfotainment" SG_ 2158796800 ODII_ODIInd25 1;
BA_ "SignalType" SG_ 2158796800 ODII_ODIInd25 "BLN";
BA_ "PacketOrder" SG_ 2158796800 ODII_ODIInd25 26;
BA_ "SignalLongName" SG_ 2158796800 ODII_ODIInd25 "Open Display Interface Indication : Open Display Interface Indication 25";
BA_ "VNSigAllNodes" SG_ 2158796800 ODII_ODIInd25 1;
BA_ "GenSigSendType" SG_ 2158796800 ODII_ODIInd24 10;
BA_ "GenSigSendOnInit" SG_ 2158796800 ODII_ODIInd24 1;
BA_ "VNSigInfotainment" SG_ 2158796800 ODII_ODIInd24 1;
BA_ "SignalType" SG_ 2158796800 ODII_ODIInd24 "BLN";
BA_ "PacketOrder" SG_ 2158796800 ODII_ODIInd24 25;
BA_ "SignalLongName" SG_ 2158796800 ODII_ODIInd24 "Open Display Interface Indication : Open Display Interface Indication 24";
BA_ "VNSigAllNodes" SG_ 2158796800 ODII_ODIInd24 1;
BA_ "GenSigSendType" SG_ 2158796800 ODII_ODIInd23 10;
BA_ "GenSigSendOnInit" SG_ 2158796800 ODII_ODIInd23 1;
BA_ "VNSigInfotainment" SG_ 2158796800 ODII_ODIInd23 1;
BA_ "SignalType" SG_ 2158796800 ODII_ODIInd23 "BLN";
BA_ "PacketOrder" SG_ 2158796800 ODII_ODIInd23 24;
BA_ "SignalLongName" SG_ 2158796800 ODII_ODIInd23 "Open Display Interface Indication : Open Display Interface Indication 23";
BA_ "VNSigAllNodes" SG_ 2158796800 ODII_ODIInd23 1;
BA_ "GenSigSendType" SG_ 2158796800 ODII_ODIInd22 10;
BA_ "GenSigSendOnInit" SG_ 2158796800 ODII_ODIInd22 1;
BA_ "VNSigInfotainment" SG_ 2158796800 ODII_ODIInd22 1;
BA_ "SignalType" SG_ 2158796800 ODII_ODIInd22 "BLN";
BA_ "PacketOrder" SG_ 2158796800 ODII_ODIInd22 23;
BA_ "SignalLongName" SG_ 2158796800 ODII_ODIInd22 "Open Display Interface Indication : Open Display Interface Indication 22";
BA_ "VNSigAllNodes" SG_ 2158796800 ODII_ODIInd22 1;
BA_ "GenSigSendType" SG_ 2158796800 ODII_ODIInd21 10;
BA_ "GenSigSendOnInit" SG_ 2158796800 ODII_ODIInd21 1;
BA_ "VNSigInfotainment" SG_ 2158796800 ODII_ODIInd21 1;
BA_ "SignalType" SG_ 2158796800 ODII_ODIInd21 "BLN";
BA_ "PacketOrder" SG_ 2158796800 ODII_ODIInd21 22;
BA_ "SignalLongName" SG_ 2158796800 ODII_ODIInd21 "Open Display Interface Indication : Open Display Interface Indication 21";
BA_ "VNSigAllNodes" SG_ 2158796800 ODII_ODIInd21 1;
BA_ "GenSigSendType" SG_ 2158796800 ODII_ODIInd20 10;
BA_ "GenSigSendOnInit" SG_ 2158796800 ODII_ODIInd20 1;
BA_ "VNSigInfotainment" SG_ 2158796800 ODII_ODIInd20 1;
BA_ "SignalType" SG_ 2158796800 ODII_ODIInd20 "BLN";
BA_ "PacketOrder" SG_ 2158796800 ODII_ODIInd20 21;
BA_ "SignalLongName" SG_ 2158796800 ODII_ODIInd20 "Open Display Interface Indication : Open Display Interface Indication 20";
BA_ "VNSigAllNodes" SG_ 2158796800 ODII_ODIInd20 1;
BA_ "GenSigSendType" SG_ 2158796800 ODII_ODIInd19 10;
BA_ "GenSigSendOnInit" SG_ 2158796800 ODII_ODIInd19 1;
BA_ "VNSigInfotainment" SG_ 2158796800 ODII_ODIInd19 1;
BA_ "SignalType" SG_ 2158796800 ODII_ODIInd19 "BLN";
BA_ "PacketOrder" SG_ 2158796800 ODII_ODIInd19 20;
BA_ "SignalLongName" SG_ 2158796800 ODII_ODIInd19 "Open Display Interface Indication : Open Display Interface Indication 19";
BA_ "VNSigAllNodes" SG_ 2158796800 ODII_ODIInd19 1;
BA_ "GenSigSendType" SG_ 2158796800 ODII_ODIInd18 10;
BA_ "GenSigSendOnInit" SG_ 2158796800 ODII_ODIInd18 1;
BA_ "VNSigInfotainment" SG_ 2158796800 ODII_ODIInd18 1;
BA_ "SignalType" SG_ 2158796800 ODII_ODIInd18 "BLN";
BA_ "PacketOrder" SG_ 2158796800 ODII_ODIInd18 19;
BA_ "SignalLongName" SG_ 2158796800 ODII_ODIInd18 "Open Display Interface Indication : Open Display Interface Indication 18";
BA_ "VNSigAllNodes" SG_ 2158796800 ODII_ODIInd18 1;
BA_ "GenSigSendType" SG_ 2158796800 ODII_ODIInd17 10;
BA_ "GenSigSendOnInit" SG_ 2158796800 ODII_ODIInd17 1;
BA_ "VNSigInfotainment" SG_ 2158796800 ODII_ODIInd17 1;
BA_ "SignalType" SG_ 2158796800 ODII_ODIInd17 "BLN";
BA_ "PacketOrder" SG_ 2158796800 ODII_ODIInd17 18;
BA_ "SignalLongName" SG_ 2158796800 ODII_ODIInd17 "Open Display Interface Indication : Open Display Interface Indication 17";
BA_ "VNSigAllNodes" SG_ 2158796800 ODII_ODIInd17 1;
BA_ "GenSigSendType" SG_ 2158796800 ODII_ODIInd16 10;
BA_ "GenSigSendOnInit" SG_ 2158796800 ODII_ODIInd16 1;
BA_ "VNSigInfotainment" SG_ 2158796800 ODII_ODIInd16 1;
BA_ "SignalType" SG_ 2158796800 ODII_ODIInd16 "BLN";
BA_ "PacketOrder" SG_ 2158796800 ODII_ODIInd16 17;
BA_ "SignalLongName" SG_ 2158796800 ODII_ODIInd16 "Open Display Interface Indication : Open Display Interface Indication 16";
BA_ "VNSigAllNodes" SG_ 2158796800 ODII_ODIInd16 1;
BA_ "GenSigSendType" SG_ 2158796800 ODII_ODIInd15 10;
BA_ "GenSigSendOnInit" SG_ 2158796800 ODII_ODIInd15 1;
BA_ "VNSigInfotainment" SG_ 2158796800 ODII_ODIInd15 1;
BA_ "SignalType" SG_ 2158796800 ODII_ODIInd15 "BLN";
BA_ "PacketOrder" SG_ 2158796800 ODII_ODIInd15 16;
BA_ "SignalLongName" SG_ 2158796800 ODII_ODIInd15 "Open Display Interface Indication : Open Display Interface Indication 15";
BA_ "VNSigAllNodes" SG_ 2158796800 ODII_ODIInd15 1;
BA_ "GenSigSendType" SG_ 2158796800 ODII_ODIInd14 10;
BA_ "GenSigSendOnInit" SG_ 2158796800 ODII_ODIInd14 1;
BA_ "VNSigInfotainment" SG_ 2158796800 ODII_ODIInd14 1;
BA_ "SignalType" SG_ 2158796800 ODII_ODIInd14 "BLN";
BA_ "PacketOrder" SG_ 2158796800 ODII_ODIInd14 15;
BA_ "SignalLongName" SG_ 2158796800 ODII_ODIInd14 "Open Display Interface Indication : Open Display Interface Indication 14";
BA_ "VNSigAllNodes" SG_ 2158796800 ODII_ODIInd14 1;
BA_ "GenSigSendType" SG_ 2158796800 ODII_ODIInd13 10;
BA_ "GenSigSendOnInit" SG_ 2158796800 ODII_ODIInd13 1;
BA_ "VNSigInfotainment" SG_ 2158796800 ODII_ODIInd13 1;
BA_ "SignalType" SG_ 2158796800 ODII_ODIInd13 "BLN";
BA_ "PacketOrder" SG_ 2158796800 ODII_ODIInd13 14;
BA_ "SignalLongName" SG_ 2158796800 ODII_ODIInd13 "Open Display Interface Indication : Open Display Interface Indication 13";
BA_ "VNSigAllNodes" SG_ 2158796800 ODII_ODIInd13 1;
BA_ "GenSigSendType" SG_ 2158796800 ODII_ODIInd12 10;
BA_ "GenSigSendOnInit" SG_ 2158796800 ODII_ODIInd12 1;
BA_ "VNSigInfotainment" SG_ 2158796800 ODII_ODIInd12 1;
BA_ "SignalType" SG_ 2158796800 ODII_ODIInd12 "BLN";
BA_ "PacketOrder" SG_ 2158796800 ODII_ODIInd12 13;
BA_ "SignalLongName" SG_ 2158796800 ODII_ODIInd12 "Open Display Interface Indication : Open Display Interface Indication 12";
BA_ "VNSigAllNodes" SG_ 2158796800 ODII_ODIInd12 1;
BA_ "GenSigSendType" SG_ 2158796800 ODII_ODIInd11 10;
BA_ "GenSigSendOnInit" SG_ 2158796800 ODII_ODIInd11 1;
BA_ "VNSigInfotainment" SG_ 2158796800 ODII_ODIInd11 1;
BA_ "SignalType" SG_ 2158796800 ODII_ODIInd11 "BLN";
BA_ "PacketOrder" SG_ 2158796800 ODII_ODIInd11 12;
BA_ "SignalLongName" SG_ 2158796800 ODII_ODIInd11 "Open Display Interface Indication : Open Display Interface Indication 11";
BA_ "VNSigAllNodes" SG_ 2158796800 ODII_ODIInd11 1;
BA_ "GenSigSendType" SG_ 2158796800 ODII_ODIInd10 10;
BA_ "GenSigSendOnInit" SG_ 2158796800 ODII_ODIInd10 1;
BA_ "VNSigInfotainment" SG_ 2158796800 ODII_ODIInd10 1;
BA_ "SignalType" SG_ 2158796800 ODII_ODIInd10 "BLN";
BA_ "PacketOrder" SG_ 2158796800 ODII_ODIInd10 11;
BA_ "SignalLongName" SG_ 2158796800 ODII_ODIInd10 "Open Display Interface Indication : Open Display Interface Indication 10";
BA_ "VNSigAllNodes" SG_ 2158796800 ODII_ODIInd10 1;
BA_ "GenSigSendType" SG_ 2158796800 ODII_ODIInd9 10;
BA_ "GenSigSendOnInit" SG_ 2158796800 ODII_ODIInd9 1;
BA_ "VNSigInfotainment" SG_ 2158796800 ODII_ODIInd9 1;
BA_ "SignalType" SG_ 2158796800 ODII_ODIInd9 "BLN";
BA_ "PacketOrder" SG_ 2158796800 ODII_ODIInd9 10;
BA_ "SignalLongName" SG_ 2158796800 ODII_ODIInd9 "Open Display Interface Indication : Open Display Interface Indication 9";
BA_ "VNSigAllNodes" SG_ 2158796800 ODII_ODIInd9 1;
BA_ "GenSigSendType" SG_ 2158796800 ODII_ODIInd8 10;
BA_ "GenSigSendOnInit" SG_ 2158796800 ODII_ODIInd8 1;
BA_ "VNSigInfotainment" SG_ 2158796800 ODII_ODIInd8 1;
BA_ "SignalType" SG_ 2158796800 ODII_ODIInd8 "BLN";
BA_ "PacketOrder" SG_ 2158796800 ODII_ODIInd8 9;
BA_ "SignalLongName" SG_ 2158796800 ODII_ODIInd8 "Open Display Interface Indication : Open Display Interface Indication 8";
BA_ "VNSigAllNodes" SG_ 2158796800 ODII_ODIInd8 1;
BA_ "GenSigSendType" SG_ 2158796800 ODII_ODIInd7 10;
BA_ "GenSigSendOnInit" SG_ 2158796800 ODII_ODIInd7 1;
BA_ "VNSigInfotainment" SG_ 2158796800 ODII_ODIInd7 1;
BA_ "SignalType" SG_ 2158796800 ODII_ODIInd7 "BLN";
BA_ "PacketOrder" SG_ 2158796800 ODII_ODIInd7 8;
BA_ "SignalLongName" SG_ 2158796800 ODII_ODIInd7 "Open Display Interface Indication : Open Display Interface Indication 7";
BA_ "VNSigAllNodes" SG_ 2158796800 ODII_ODIInd7 1;
BA_ "GenSigSendType" SG_ 2158796800 ODII_ODIInd6 10;
BA_ "GenSigSendOnInit" SG_ 2158796800 ODII_ODIInd6 1;
BA_ "VNSigInfotainment" SG_ 2158796800 ODII_ODIInd6 1;
BA_ "SignalType" SG_ 2158796800 ODII_ODIInd6 "BLN";
BA_ "PacketOrder" SG_ 2158796800 ODII_ODIInd6 7;
BA_ "SignalLongName" SG_ 2158796800 ODII_ODIInd6 "Open Display Interface Indication : Open Display Interface Indication 6";
BA_ "VNSigAllNodes" SG_ 2158796800 ODII_ODIInd6 1;
BA_ "GenSigSendType" SG_ 2158796800 ODII_ODIInd5 10;
BA_ "GenSigSendOnInit" SG_ 2158796800 ODII_ODIInd5 1;
BA_ "VNSigInfotainment" SG_ 2158796800 ODII_ODIInd5 1;
BA_ "SignalType" SG_ 2158796800 ODII_ODIInd5 "BLN";
BA_ "PacketOrder" SG_ 2158796800 ODII_ODIInd5 6;
BA_ "SignalLongName" SG_ 2158796800 ODII_ODIInd5 "Open Display Interface Indication : Open Display Interface Indication 5";
BA_ "VNSigAllNodes" SG_ 2158796800 ODII_ODIInd5 1;
BA_ "GenSigSendType" SG_ 2158796800 ODII_ODIInd4 10;
BA_ "GenSigSendOnInit" SG_ 2158796800 ODII_ODIInd4 1;
BA_ "VNSigInfotainment" SG_ 2158796800 ODII_ODIInd4 1;
BA_ "SignalType" SG_ 2158796800 ODII_ODIInd4 "BLN";
BA_ "PacketOrder" SG_ 2158796800 ODII_ODIInd4 5;
BA_ "SignalLongName" SG_ 2158796800 ODII_ODIInd4 "Open Display Interface Indication : Open Display Interface Indication 4";
BA_ "VNSigAllNodes" SG_ 2158796800 ODII_ODIInd4 1;
BA_ "GenSigSendType" SG_ 2158796800 ODII_ODIInd3 10;
BA_ "GenSigSendOnInit" SG_ 2158796800 ODII_ODIInd3 1;
BA_ "VNSigInfotainment" SG_ 2158796800 ODII_ODIInd3 1;
BA_ "SignalType" SG_ 2158796800 ODII_ODIInd3 "BLN";
BA_ "PacketOrder" SG_ 2158796800 ODII_ODIInd3 4;
BA_ "SignalLongName" SG_ 2158796800 ODII_ODIInd3 "Open Display Interface Indication : Open Display Interface Indication 3";
BA_ "VNSigAllNodes" SG_ 2158796800 ODII_ODIInd3 1;
BA_ "GenSigSendType" SG_ 2158796800 ODII_ODIInd2 10;
BA_ "GenSigSendOnInit" SG_ 2158796800 ODII_ODIInd2 1;
BA_ "VNSigInfotainment" SG_ 2158796800 ODII_ODIInd2 1;
BA_ "SignalType" SG_ 2158796800 ODII_ODIInd2 "BLN";
BA_ "PacketOrder" SG_ 2158796800 ODII_ODIInd2 3;
BA_ "SignalLongName" SG_ 2158796800 ODII_ODIInd2 "Open Display Interface Indication : Open Display Interface Indication 2";
BA_ "VNSigAllNodes" SG_ 2158796800 ODII_ODIInd2 1;
BA_ "GenSigSendType" SG_ 2158796800 ODII_ODIInd1 10;
BA_ "GenSigSendOnInit" SG_ 2158796800 ODII_ODIInd1 1;
BA_ "VNSigInfotainment" SG_ 2158796800 ODII_ODIInd1 1;
BA_ "SignalType" SG_ 2158796800 ODII_ODIInd1 "BLN";
BA_ "PacketOrder" SG_ 2158796800 ODII_ODIInd1 2;
BA_ "SignalLongName" SG_ 2158796800 ODII_ODIInd1 "Open Display Interface Indication : Open Display Interface Indication 1";
BA_ "VNSigAllNodes" SG_ 2158796800 ODII_ODIInd1 1;
BA_ "GenSigSendType" SG_ 2158796800 ODII_ODIInd56 10;
BA_ "GenSigSendOnInit" SG_ 2158796800 ODII_ODIInd56 1;
BA_ "VNSigInfotainment" SG_ 2158796800 ODII_ODIInd56 1;
BA_ "SignalType" SG_ 2158796800 ODII_ODIInd56 "BLN";
BA_ "PacketOrder" SG_ 2158796800 ODII_ODIInd56 57;
BA_ "SignalLongName" SG_ 2158796800 ODII_ODIInd56 "Open Display Interface Indication : Open Display Interface Indication 56";
BA_ "VNSigAllNodes" SG_ 2158796800 ODII_ODIInd56 1;
BA_ "GenSigSendType" SG_ 2158796800 ODII_ODIInd49 10;
BA_ "GenSigSendOnInit" SG_ 2158796800 ODII_ODIInd49 1;
BA_ "VNSigInfotainment" SG_ 2158796800 ODII_ODIInd49 1;
BA_ "SignalType" SG_ 2158796800 ODII_ODIInd49 "BLN";
BA_ "PacketOrder" SG_ 2158796800 ODII_ODIInd49 50;
BA_ "SignalLongName" SG_ 2158796800 ODII_ODIInd49 "Open Display Interface Indication : Open Display Interface Indication 49";
BA_ "VNSigAllNodes" SG_ 2158796800 ODII_ODIInd49 1;
BA_ "GenSigSendType" SG_ 2158796800 ODII_ODIInd48 10;
BA_ "GenSigSendOnInit" SG_ 2158796800 ODII_ODIInd48 1;
BA_ "VNSigInfotainment" SG_ 2158796800 ODII_ODIInd48 1;
BA_ "SignalType" SG_ 2158796800 ODII_ODIInd48 "BLN";
BA_ "PacketOrder" SG_ 2158796800 ODII_ODIInd48 49;
BA_ "SignalLongName" SG_ 2158796800 ODII_ODIInd48 "Open Display Interface Indication : Open Display Interface Indication 48";
BA_ "VNSigAllNodes" SG_ 2158796800 ODII_ODIInd48 1;
BA_ "GenSigSendType" SG_ 2158796800 ODII_ODIInd47 10;
BA_ "GenSigSendOnInit" SG_ 2158796800 ODII_ODIInd47 1;
BA_ "VNSigInfotainment" SG_ 2158796800 ODII_ODIInd47 1;
BA_ "SignalType" SG_ 2158796800 ODII_ODIInd47 "BLN";
BA_ "PacketOrder" SG_ 2158796800 ODII_ODIInd47 48;
BA_ "SignalLongName" SG_ 2158796800 ODII_ODIInd47 "Open Display Interface Indication : Open Display Interface Indication 47";
BA_ "VNSigAllNodes" SG_ 2158796800 ODII_ODIInd47 1;
BA_ "GenSigSendType" SG_ 2158796800 ODII_ODIInd46 10;
BA_ "GenSigSendOnInit" SG_ 2158796800 ODII_ODIInd46 1;
BA_ "VNSigInfotainment" SG_ 2158796800 ODII_ODIInd46 1;
BA_ "SignalType" SG_ 2158796800 ODII_ODIInd46 "BLN";
BA_ "PacketOrder" SG_ 2158796800 ODII_ODIInd46 47;
BA_ "SignalLongName" SG_ 2158796800 ODII_ODIInd46 "Open Display Interface Indication : Open Display Interface Indication 46";
BA_ "VNSigAllNodes" SG_ 2158796800 ODII_ODIInd46 1;
BA_ "GenSigSendType" SG_ 2158796800 ODII_ODIInd45 10;
BA_ "GenSigSendOnInit" SG_ 2158796800 ODII_ODIInd45 1;
BA_ "VNSigInfotainment" SG_ 2158796800 ODII_ODIInd45 1;
BA_ "SignalType" SG_ 2158796800 ODII_ODIInd45 "BLN";
BA_ "PacketOrder" SG_ 2158796800 ODII_ODIInd45 46;
BA_ "SignalLongName" SG_ 2158796800 ODII_ODIInd45 "Open Display Interface Indication : Open Display Interface Indication 45";
BA_ "VNSigAllNodes" SG_ 2158796800 ODII_ODIInd45 1;
BA_ "GenSigSendType" SG_ 2158796800 ODII_ODIInd44 10;
BA_ "GenSigSendOnInit" SG_ 2158796800 ODII_ODIInd44 1;
BA_ "VNSigInfotainment" SG_ 2158796800 ODII_ODIInd44 1;
BA_ "SignalType" SG_ 2158796800 ODII_ODIInd44 "BLN";
BA_ "PacketOrder" SG_ 2158796800 ODII_ODIInd44 45;
BA_ "SignalLongName" SG_ 2158796800 ODII_ODIInd44 "Open Display Interface Indication : Open Display Interface Indication 44";
BA_ "VNSigAllNodes" SG_ 2158796800 ODII_ODIInd44 1;
BA_ "GenSigSendType" SG_ 2158796800 ODII_ODIInd43 10;
BA_ "GenSigSendOnInit" SG_ 2158796800 ODII_ODIInd43 1;
BA_ "VNSigInfotainment" SG_ 2158796800 ODII_ODIInd43 1;
BA_ "SignalType" SG_ 2158796800 ODII_ODIInd43 "BLN";
BA_ "PacketOrder" SG_ 2158796800 ODII_ODIInd43 44;
BA_ "SignalLongName" SG_ 2158796800 ODII_ODIInd43 "Open Display Interface Indication : Open Display Interface Indication 43";
BA_ "VNSigAllNodes" SG_ 2158796800 ODII_ODIInd43 1;
BA_ "GenSigSendType" SG_ 2158796800 ODII_ODIInd42 10;
BA_ "GenSigSendOnInit" SG_ 2158796800 ODII_ODIInd42 1;
BA_ "VNSigInfotainment" SG_ 2158796800 ODII_ODIInd42 1;
BA_ "SignalType" SG_ 2158796800 ODII_ODIInd42 "BLN";
BA_ "PacketOrder" SG_ 2158796800 ODII_ODIInd42 43;
BA_ "SignalLongName" SG_ 2158796800 ODII_ODIInd42 "Open Display Interface Indication : Open Display Interface Indication 42";
BA_ "VNSigAllNodes" SG_ 2158796800 ODII_ODIInd42 1;
BA_ "GenSigSendType" SG_ 2158796800 ODII_ODIInd41 10;
BA_ "GenSigSendOnInit" SG_ 2158796800 ODII_ODIInd41 1;
BA_ "VNSigInfotainment" SG_ 2158796800 ODII_ODIInd41 1;
BA_ "SignalType" SG_ 2158796800 ODII_ODIInd41 "BLN";
BA_ "PacketOrder" SG_ 2158796800 ODII_ODIInd41 42;
BA_ "SignalLongName" SG_ 2158796800 ODII_ODIInd41 "Open Display Interface Indication : Open Display Interface Indication 41";
BA_ "VNSigAllNodes" SG_ 2158796800 ODII_ODIInd41 1;
BA_ "GenSigSendType" SG_ 2158796800 ODII_ODIInd40 10;
BA_ "GenSigSendOnInit" SG_ 2158796800 ODII_ODIInd40 1;
BA_ "VNSigInfotainment" SG_ 2158796800 ODII_ODIInd40 1;
BA_ "SignalType" SG_ 2158796800 ODII_ODIInd40 "BLN";
BA_ "PacketOrder" SG_ 2158796800 ODII_ODIInd40 41;
BA_ "SignalLongName" SG_ 2158796800 ODII_ODIInd40 "Open Display Interface Indication : Open Display Interface Indication 40";
BA_ "VNSigAllNodes" SG_ 2158796800 ODII_ODIInd40 1;
BA_ "GenSigSendType" SG_ 2158796800 ODII_ODIInd39 10;
BA_ "GenSigSendOnInit" SG_ 2158796800 ODII_ODIInd39 1;
BA_ "VNSigInfotainment" SG_ 2158796800 ODII_ODIInd39 1;
BA_ "SignalType" SG_ 2158796800 ODII_ODIInd39 "BLN";
BA_ "PacketOrder" SG_ 2158796800 ODII_ODIInd39 40;
BA_ "SignalLongName" SG_ 2158796800 ODII_ODIInd39 "Open Display Interface Indication : Open Display Interface Indication 39";
BA_ "VNSigAllNodes" SG_ 2158796800 ODII_ODIInd39 1;
BA_ "GenSigSendType" SG_ 2158796800 ODII_ODIInd38 10;
BA_ "GenSigSendOnInit" SG_ 2158796800 ODII_ODIInd38 1;
BA_ "VNSigInfotainment" SG_ 2158796800 ODII_ODIInd38 1;
BA_ "SignalType" SG_ 2158796800 ODII_ODIInd38 "BLN";
BA_ "PacketOrder" SG_ 2158796800 ODII_ODIInd38 39;
BA_ "SignalLongName" SG_ 2158796800 ODII_ODIInd38 "Open Display Interface Indication : Open Display Interface Indication 38";
BA_ "VNSigAllNodes" SG_ 2158796800 ODII_ODIInd38 1;
BA_ "GenSigSendType" SG_ 2158796800 ODII_ODIInd37 10;
BA_ "GenSigSendOnInit" SG_ 2158796800 ODII_ODIInd37 1;
BA_ "VNSigInfotainment" SG_ 2158796800 ODII_ODIInd37 1;
BA_ "SignalType" SG_ 2158796800 ODII_ODIInd37 "BLN";
BA_ "PacketOrder" SG_ 2158796800 ODII_ODIInd37 38;
BA_ "SignalLongName" SG_ 2158796800 ODII_ODIInd37 "Open Display Interface Indication : Open Display Interface Indication 37";
BA_ "VNSigAllNodes" SG_ 2158796800 ODII_ODIInd37 1;
BA_ "GenSigSendType" SG_ 2158796800 ODII_ODIInd36 10;
BA_ "GenSigSendOnInit" SG_ 2158796800 ODII_ODIInd36 1;
BA_ "VNSigInfotainment" SG_ 2158796800 ODII_ODIInd36 1;
BA_ "SignalType" SG_ 2158796800 ODII_ODIInd36 "BLN";
BA_ "PacketOrder" SG_ 2158796800 ODII_ODIInd36 37;
BA_ "SignalLongName" SG_ 2158796800 ODII_ODIInd36 "Open Display Interface Indication : Open Display Interface Indication 36";
BA_ "VNSigAllNodes" SG_ 2158796800 ODII_ODIInd36 1;
BA_ "GenSigSendType" SG_ 2158796800 ODII_ODIInd35 10;
BA_ "GenSigSendOnInit" SG_ 2158796800 ODII_ODIInd35 1;
BA_ "VNSigInfotainment" SG_ 2158796800 ODII_ODIInd35 1;
BA_ "SignalType" SG_ 2158796800 ODII_ODIInd35 "BLN";
BA_ "PacketOrder" SG_ 2158796800 ODII_ODIInd35 36;
BA_ "SignalLongName" SG_ 2158796800 ODII_ODIInd35 "Open Display Interface Indication : Open Display Interface Indication 35";
BA_ "VNSigAllNodes" SG_ 2158796800 ODII_ODIInd35 1;
BA_ "GenSigSendType" SG_ 2158796800 ODII_ODIInd34 10;
BA_ "GenSigSendOnInit" SG_ 2158796800 ODII_ODIInd34 1;
BA_ "VNSigInfotainment" SG_ 2158796800 ODII_ODIInd34 1;
BA_ "SignalType" SG_ 2158796800 ODII_ODIInd34 "BLN";
BA_ "PacketOrder" SG_ 2158796800 ODII_ODIInd34 35;
BA_ "SignalLongName" SG_ 2158796800 ODII_ODIInd34 "Open Display Interface Indication : Open Display Interface Indication 34";
BA_ "VNSigAllNodes" SG_ 2158796800 ODII_ODIInd34 1;
BA_ "GenSigSendType" SG_ 2158796800 ODII_ODIInd33 10;
BA_ "GenSigSendOnInit" SG_ 2158796800 ODII_ODIInd33 1;
BA_ "VNSigInfotainment" SG_ 2158796800 ODII_ODIInd33 1;
BA_ "SignalType" SG_ 2158796800 ODII_ODIInd33 "BLN";
BA_ "PacketOrder" SG_ 2158796800 ODII_ODIInd33 34;
BA_ "SignalLongName" SG_ 2158796800 ODII_ODIInd33 "Open Display Interface Indication : Open Display Interface Indication 33";
BA_ "VNSigAllNodes" SG_ 2158796800 ODII_ODIInd33 1;
BA_ "GenSigSendType" SG_ 2158796800 ODII_ODIInd32 10;
BA_ "GenSigSendOnInit" SG_ 2158796800 ODII_ODIInd32 1;
BA_ "VNSigInfotainment" SG_ 2158796800 ODII_ODIInd32 1;
BA_ "SignalType" SG_ 2158796800 ODII_ODIInd32 "BLN";
BA_ "PacketOrder" SG_ 2158796800 ODII_ODIInd32 33;
BA_ "SignalLongName" SG_ 2158796800 ODII_ODIInd32 "Open Display Interface Indication : Open Display Interface Indication 32";
BA_ "VNSigAllNodes" SG_ 2158796800 ODII_ODIInd32 1;
BA_ "GenSigSendType" SG_ 2158796800 ODII_ODIInd31 10;
BA_ "GenSigSendOnInit" SG_ 2158796800 ODII_ODIInd31 1;
BA_ "VNSigInfotainment" SG_ 2158796800 ODII_ODIInd31 1;
BA_ "SignalType" SG_ 2158796800 ODII_ODIInd31 "BLN";
BA_ "PacketOrder" SG_ 2158796800 ODII_ODIInd31 32;
BA_ "SignalLongName" SG_ 2158796800 ODII_ODIInd31 "Open Display Interface Indication : Open Display Interface Indication 31";
BA_ "VNSigAllNodes" SG_ 2158796800 ODII_ODIInd31 1;
BA_ "GenSigSendType" SG_ 2158796800 ODII_ODIInd30 10;
BA_ "GenSigSendOnInit" SG_ 2158796800 ODII_ODIInd30 1;
BA_ "VNSigInfotainment" SG_ 2158796800 ODII_ODIInd30 1;
BA_ "SignalType" SG_ 2158796800 ODII_ODIInd30 "BLN";
BA_ "PacketOrder" SG_ 2158796800 ODII_ODIInd30 31;
BA_ "SignalLongName" SG_ 2158796800 ODII_ODIInd30 "Open Display Interface Indication : Open Display Interface Indication 30";
BA_ "VNSigAllNodes" SG_ 2158796800 ODII_ODIInd30 1;
BA_ "GenSigSendType" SG_ 2158796800 ODII_ODIInd29 10;
BA_ "GenSigSendOnInit" SG_ 2158796800 ODII_ODIInd29 1;
BA_ "VNSigInfotainment" SG_ 2158796800 ODII_ODIInd29 1;
BA_ "SignalType" SG_ 2158796800 ODII_ODIInd29 "BLN";
BA_ "PacketOrder" SG_ 2158796800 ODII_ODIInd29 30;
BA_ "SignalLongName" SG_ 2158796800 ODII_ODIInd29 "Open Display Interface Indication : Open Display Interface Indication 29";
BA_ "VNSigAllNodes" SG_ 2158796800 ODII_ODIInd29 1;
BA_ "GenSigSendType" SG_ 2158796800 ODII_ODIInd28 10;
BA_ "GenSigSendOnInit" SG_ 2158796800 ODII_ODIInd28 1;
BA_ "VNSigInfotainment" SG_ 2158796800 ODII_ODIInd28 1;
BA_ "SignalType" SG_ 2158796800 ODII_ODIInd28 "BLN";
BA_ "PacketOrder" SG_ 2158796800 ODII_ODIInd28 29;
BA_ "SignalLongName" SG_ 2158796800 ODII_ODIInd28 "Open Display Interface Indication : Open Display Interface Indication 28";
BA_ "VNSigAllNodes" SG_ 2158796800 ODII_ODIInd28 1;
BA_ "GenSigDeltaValue" SG_ 2158796800 ODII_FUCID 1;
BA_ "GenSigSendType" SG_ 2158796800 ODII_FUCID 12;
BA_ "GenSigSendOnInit" SG_ 2158796800 ODII_FUCID 1;
BA_ "VNSigInfotainment" SG_ 2158796800 ODII_FUCID 1;
BA_ "SignalType" SG_ 2158796800 ODII_FUCID "UNM";
BA_ "PacketOrder" SG_ 2158796800 ODII_FUCID 1;
BA_ "SignalLongName" SG_ 2158796800 ODII_FUCID "Open Display Interface Indication : Functional Unit Class ID";
BA_ "VNSigAllNodes" SG_ 2158796800 ODII_FUCID 1;
BA_ "GenSigDeltaValue" SG_ 2158755840 ODIE_MultiFrRetCh 1;
BA_ "GenSigSendType" SG_ 2158755840 ODIE_MultiFrRetCh 12;
BA_ "VNSigInfotainment" SG_ 2158755840 ODIE_MultiFrRetCh 1;
BA_ "SignalType" SG_ 2158755840 ODIE_MultiFrRetCh "UNM";
BA_ "PacketOrder" SG_ 2158755840 ODIE_MultiFrRetCh 3;
BA_ "SignalLongName" SG_ 2158755840 ODIE_MultiFrRetCh "Open Display Interface Event Packet : MultiFrameReturnChannel";
BA_ "VNSigAllNodes" SG_ 2158755840 ODIE_MultiFrRetCh 1;
BA_ "GenSigDeltaValue" SG_ 2158755840 ODIE_FUCID 1;
BA_ "GenSigSendType" SG_ 2158755840 ODIE_FUCID 12;
BA_ "VNSigInfotainment" SG_ 2158755840 ODIE_FUCID 1;
BA_ "SignalType" SG_ 2158755840 ODIE_FUCID "UNM";
BA_ "PacketOrder" SG_ 2158755840 ODIE_FUCID 2;
BA_ "SignalLongName" SG_ 2158755840 ODIE_FUCID "Open Display Interface Event Packet : Functional Unit Class ID";
BA_ "VNSigAllNodes" SG_ 2158755840 ODIE_FUCID 1;
BA_ "GenSigDeltaValue" SG_ 2158755840 ODIE_EvID 1;
BA_ "GenSigSendType" SG_ 2158755840 ODIE_EvID 12;
BA_ "VNSigInfotainment" SG_ 2158755840 ODIE_EvID 1;
BA_ "SignalType" SG_ 2158755840 ODIE_EvID "UNM";
BA_ "PacketOrder" SG_ 2158755840 ODIE_EvID 1;
BA_ "SignalLongName" SG_ 2158755840 ODIE_EvID "Open Display Interface Event Packet : Event ID";
BA_ "VNSigAllNodes" SG_ 2158755840 ODIE_EvID 1;
BA_ "GenSigDeltaValue" SG_ 2159157248 ODI_CntrStck2TEL 1;
BA_ "GenSigSendType" SG_ 2159157248 ODI_CntrStck2TEL 12;
BA_ "VNSigInfotainment" SG_ 2159157248 ODI_CntrStck2TEL 1;
BA_ "SignalType" SG_ 2159157248 ODI_CntrStck2TEL "UNM";
BA_ "SignalLongName" SG_ 2159157248 ODI_CntrStck2TEL "Open Display Interface CenterStack 2 TEL";
BA_ "VNSigAllNodes" SG_ 2159157248 ODI_CntrStck2TEL 1;
BA_ "GenSigSendType" SG_ 2153955328 EngOffTmExtRngV 10;
BA_ "VNSigInfotainment" SG_ 2153955328 EngOffTmExtRngV 1;
BA_ "SignalType" SG_ 2153955328 EngOffTmExtRngV "ENM";
BA_ "SignalLongName" SG_ 2153955328 EngOffTmExtRngV "Engine Off Time Extended Range Validity";
BA_ "VNSigAllNodes" SG_ 2153955328 EngOffTmExtRngV 1;
BA_ "GenSigDeltaValue" SG_ 2153955328 EngOffTmExtRng 1;
BA_ "GenSigSendType" SG_ 2153955328 EngOffTmExtRng 12;
BA_ "GenSigSendOnInit" SG_ 2153955328 EngOffTmExtRng 2;
BA_ "VNSigInfotainment" SG_ 2153955328 EngOffTmExtRng 1;
BA_ "SignalType" SG_ 2153955328 EngOffTmExtRng "UNM";
BA_ "SignalLongName" SG_ 2153955328 EngOffTmExtRng "Engine Off Time Extended Range";
BA_ "VNSigAllNodes" SG_ 2153955328 EngOffTmExtRng 1;
BA_ "GenSigSendType" SG_ 2153955328 ElpsdTimeCntRstOcc 10;
BA_ "SignalType" SG_ 2153955328 ElpsdTimeCntRstOcc "BLN";
BA_ "SignalLongName" SG_ 2153955328 ElpsdTimeCntRstOcc "Elapsed Time Count Reset Occurred";
BA_ "VNSigAllNodes" SG_ 2153955328 ElpsdTimeCntRstOcc 1;
BA_ "GenSigDeltaValue" SG_ 2153955328 ElpsdTimeCnt 1;
BA_ "GenSigSendType" SG_ 2153955328 ElpsdTimeCnt 12;
BA_ "SignalType" SG_ 2153955328 ElpsdTimeCnt "UNM";
BA_ "SignalLongName" SG_ 2153955328 ElpsdTimeCnt "Elapsed Time Count";
BA_ "VNSigAllNodes" SG_ 2153955328 ElpsdTimeCnt 1;
BA_ "GenSigSendType" SG_ 2151063552 TrfRdsdInfCsStReq 10;
BA_ "SignalType" SG_ 2151063552 TrfRdsdInfCsStReq "ENM";
BA_ "SignalLongName" SG_ 2151063552 TrfRdsdInfCsStReq "Traffic and Roadside Information Customization Setting Request";
BA_ "VNSigAllNodes" SG_ 2151063552 TrfRdsdInfCsStReq 1;
BA_ "GenSigSendType" SG_ 2151063552 IntrStopAlrtCsSetReq 10;
BA_ "SignalType" SG_ 2151063552 IntrStopAlrtCsSetReq "ENM";
BA_ "SignalLongName" SG_ 2151063552 IntrStopAlrtCsSetReq "Intersection Stop Alert Customization Setting Request";
BA_ "VNSigAllNodes" SG_ 2151063552 IntrStopAlrtCsSetReq 1;
BA_ "GenSigSendType" SG_ 2151063552 CntdVehBrAltCsStReq 10;
BA_ "SignalType" SG_ 2151063552 CntdVehBrAltCsStReq "ENM";
BA_ "SignalLongName" SG_ 2151063552 CntdVehBrAltCsStReq "Connected Vehicle Braking Alerts Customization Setting Request";
BA_ "VNSigAllNodes" SG_ 2151063552 CntdVehBrAltCsStReq 1;
BA_ "GenSigDeltaValue" SG_ 2151063552 ICSTS_Y1TchCrdnt 1;
BA_ "GenSigSendType" SG_ 2151063552 ICSTS_Y1TchCrdnt 12;
BA_ "PacketOrder" SG_ 2151063552 ICSTS_Y1TchCrdnt 3;
BA_ "SignalType" SG_ 2151063552 ICSTS_Y1TchCrdnt "UNM";
BA_ "SignalLongName" SG_ 2151063552 ICSTS_Y1TchCrdnt "Integrated Center Stack Touch Status : Y1 Touch Coordinate";
BA_ "VNSigAllNodes" SG_ 2151063552 ICSTS_Y1TchCrdnt 1;
BA_ "GenSigDeltaValue" SG_ 2151063552 ICSTS_X1TchCrdnt 1;
BA_ "GenSigSendType" SG_ 2151063552 ICSTS_X1TchCrdnt 12;
BA_ "PacketOrder" SG_ 2151063552 ICSTS_X1TchCrdnt 2;
BA_ "SignalType" SG_ 2151063552 ICSTS_X1TchCrdnt "UNM";
BA_ "SignalLongName" SG_ 2151063552 ICSTS_X1TchCrdnt "Integrated Center Stack Touch Status : X1 Touch Coordinate";
BA_ "VNSigAllNodes" SG_ 2151063552 ICSTS_X1TchCrdnt 1;
BA_ "GenSigSendType" SG_ 2151063552 ICSTS_TchPrxmty 10;
BA_ "PacketOrder" SG_ 2151063552 ICSTS_TchPrxmty 1;
BA_ "SignalType" SG_ 2151063552 ICSTS_TchPrxmty "ENM";
BA_ "SignalLongName" SG_ 2151063552 ICSTS_TchPrxmty "Integrated Center Stack Touch Status : Touch Proximity";
BA_ "VNSigAllNodes" SG_ 2151063552 ICSTS_TchPrxmty 1;
BA_ "GenSigSendType" SG_ 2151063552 TrgdVidRecSwAct 10;
BA_ "SignalType" SG_ 2151063552 TrgdVidRecSwAct "BLN";
BA_ "SignalLongName" SG_ 2151063552 TrgdVidRecSwAct "Triggered Video Recorder Switch Active";
BA_ "VNSigAllNodes" SG_ 2151063552 TrgdVidRecSwAct 1;
BA_ "GenSigSendType" SG_ 2151063552 RrPedDetCstStReq 10;
BA_ "SignalType" SG_ 2151063552 RrPedDetCstStReq "ENM";
BA_ "SignalLongName" SG_ 2151063552 RrPedDetCstStReq "Rear Pedestrian Detection Customization Setting Request";
BA_ "VNSigAllNodes" SG_ 2151063552 RrPedDetCstStReq 1;
BA_ "GenSigSendType" SG_ 2151063552 CamVideoICSDispAct 10;
BA_ "SignalType" SG_ 2151063552 CamVideoICSDispAct "BLN";
BA_ "SignalLongName" SG_ 2151063552 CamVideoICSDispAct "Camera Video ICS Display Active";
BA_ "VNSigAllNodes" SG_ 2151063552 CamVideoICSDispAct 1;
BA_ "GenSigSendType" SG_ 2151063552 Frnt360CamSwAct 10;
BA_ "SignalType" SG_ 2151063552 Frnt360CamSwAct "BLN";
BA_ "SignalLongName" SG_ 2151063552 Frnt360CamSwAct "Front 360 Camera Switch Active";
BA_ "VNSigAllNodes" SG_ 2151063552 Frnt360CamSwAct 1;
BA_ "GenSigSendType" SG_ 2151063552 InftnOprAlwd 10;
BA_ "GenSigSendOnInit" SG_ 2151063552 InftnOprAlwd 1;
BA_ "VNSigInfotainment" SG_ 2151063552 InftnOprAlwd 1;
BA_ "SignalType" SG_ 2151063552 InftnOprAlwd "BLN";
BA_ "SignalLongName" SG_ 2151063552 InftnOprAlwd "Infotainment Operation Allowed";
BA_ "VNSigAllNodes" SG_ 2151063552 InftnOprAlwd 1;
BA_ "GenSigSendType" SG_ 2151063552 ValetMdAct 10;
BA_ "VNSigInfotainment" SG_ 2151063552 ValetMdAct 1;
BA_ "SignalType" SG_ 2151063552 ValetMdAct "BLN";
BA_ "SignalLongName" SG_ 2151063552 ValetMdAct "Valet Mode Active";
BA_ "VNSigAllNodes" SG_ 2151063552 ValetMdAct 1;
BA_ "GenSigSendType" SG_ 2157985792 FobProgEvntRqd 10;
BA_ "GenSigSendOnInit" SG_ 2157985792 FobProgEvntRqd 2;
BA_ "SignalType" SG_ 2157985792 FobProgEvntRqd "BLN";
BA_ "SignalLongName" SG_ 2157985792 FobProgEvntRqd "Fob Programming Event Requested";
BA_ "VNSigAllNodes" SG_ 2157985792 FobProgEvntRqd 1;
BA_ "GenSigSendType" SG_ 2151284736 PrkAstOprtrDsrdStat_1D0 10;
BA_ "GenSigSendOnInit" SG_ 2151284736 PrkAstOprtrDsrdStat_1D0 2;
BA_ "SignalType" SG_ 2151284736 PrkAstOprtrDsrdStat_1D0 "ENM";
BA_ "SignalLongName" SG_ 2151284736 PrkAstOprtrDsrdStat_1D0 "Park Assistance Operator Desired Status";
BA_ "VNSigAllNodes" SG_ 2151284736 PrkAstOprtrDsrdStat_1D0 1;
BA_ "GenSigSendType" SG_ 2151284736 TnDrvPrkAstOffUnbIO 10;
BA_ "SignalType" SG_ 2151284736 TnDrvPrkAstOffUnbIO "BLN";
BA_ "SignalLongName" SG_ 2151284736 TnDrvPrkAstOffUnbIO "Teen Driver Park Assist Off Unavailable Indication On";
BA_ "VNSigAllNodes" SG_ 2151284736 TnDrvPrkAstOffUnbIO 1;
BA_ "GenSigSendType" SG_ 2151284736 PrkAstFld 10;
BA_ "SignalType" SG_ 2151284736 PrkAstFld "BLN";
BA_ "SignalLongName" SG_ 2151284736 PrkAstFld "Parking Assistance Failed";
BA_ "VNSigAllNodes" SG_ 2151284736 PrkAstFld 1;
BA_ "GenSigSendType" SG_ 2151284736 PrkAstSnsDistrbdIO 10;
BA_ "SignalType" SG_ 2151284736 PrkAstSnsDistrbdIO "BLN";
BA_ "SignalLongName" SG_ 2151284736 PrkAstSnsDistrbdIO "Parking Assistance Sensors Disturbed Indication On";
BA_ "VNSigAllNodes" SG_ 2151284736 PrkAstSnsDistrbdIO 1;
BA_ "GenSigSendType" SG_ 2151284736 PrkAsstDisablIO 10;
BA_ "GenSigSendOnInit" SG_ 2151284736 PrkAsstDisablIO 2;
BA_ "SignalType" SG_ 2151284736 PrkAsstDisablIO "BLN";
BA_ "SignalLongName" SG_ 2151284736 PrkAsstDisablIO "Parking Assistance Disabled Indication On";
BA_ "VNSigAllNodes" SG_ 2151284736 PrkAsstDisablIO 1;
BA_ "GenSigSendType" SG_ 2151284736 PrkAstSnrsBlk 10;
BA_ "SignalType" SG_ 2151284736 PrkAstSnrsBlk "BLN";
BA_ "SignalLongName" SG_ 2151284736 PrkAstSnrsBlk "Parking Assistance Sensors Blocked";
BA_ "VNSigAllNodes" SG_ 2151284736 PrkAstSnrsBlk 1;
BA_ "GenSigSendType" SG_ 2151284736 PrkAsstClnPrkAstIO 10;
BA_ "SignalType" SG_ 2151284736 PrkAsstClnPrkAstIO "BLN";
BA_ "SignalLongName" SG_ 2151284736 PrkAsstClnPrkAstIO "Parking Assistance Clean Parking Assist Indication On";
BA_ "VNSigAllNodes" SG_ 2151284736 PrkAsstClnPrkAstIO 1;
BA_ "GenSigDeltaValue" SG_ 2159099904 ODI_DAB2AxIP 1;
BA_ "GenSigSendType" SG_ 2159099904 ODI_DAB2AxIP 12;
BA_ "VNSigInfotainment" SG_ 2159099904 ODI_DAB2AxIP 1;
BA_ "SignalType" SG_ 2159099904 ODI_DAB2AxIP "UNM";
BA_ "SignalLongName" SG_ 2159099904 ODI_DAB2AxIP "Open Display Interface DAB 2 AuxIP";
BA_ "VNSigAllNodes" SG_ 2159099904 ODI_DAB2AxIP 1;
BA_ "GenSigDeltaValue" SG_ 2159067136 ODI_DAB2IPC 1;
BA_ "GenSigSendType" SG_ 2159067136 ODI_DAB2IPC 12;
BA_ "VNSigInfotainment" SG_ 2159067136 ODI_DAB2IPC 1;
BA_ "SignalType" SG_ 2159067136 ODI_DAB2IPC "UNM";
BA_ "SignalLongName" SG_ 2159067136 ODI_DAB2IPC "Open Display Interface DAB 2 IPC";
BA_ "VNSigAllNodes" SG_ 2159067136 ODI_DAB2IPC 1;
BA_ "GenSigDeltaValue" SG_ 2159206400 ODI_AxIP2IPC 1;
BA_ "GenSigSendType" SG_ 2159206400 ODI_AxIP2IPC 12;
BA_ "VNSigInfotainment" SG_ 2159206400 ODI_AxIP2IPC 1;
BA_ "SignalType" SG_ 2159206400 ODI_AxIP2IPC "UNM";
BA_ "SignalLongName" SG_ 2159206400 ODI_AxIP2IPC "Open Display Interface AuxIP 2 IPC";
BA_ "VNSigAllNodes" SG_ 2159206400 ODI_AxIP2IPC 1;
BA_ "GenSigDeltaValue" SG_ 2159198208 ODI_IPC2AxIP 1;
BA_ "GenSigSendType" SG_ 2159198208 ODI_IPC2AxIP 12;
BA_ "VNSigInfotainment" SG_ 2159198208 ODI_IPC2AxIP 1;
BA_ "SignalType" SG_ 2159198208 ODI_IPC2AxIP "UNM";
BA_ "SignalLongName" SG_ 2159198208 ODI_IPC2AxIP "Open Display Interface IPC 2 AuxIP";
BA_ "VNSigAllNodes" SG_ 2159198208 ODI_IPC2AxIP 1;
BA_ "GenSigDeltaValue" SG_ 2159190016 ODI_AxIP2CntrStck 1;
BA_ "GenSigSendType" SG_ 2159190016 ODI_AxIP2CntrStck 12;
BA_ "VNSigInfotainment" SG_ 2159190016 ODI_AxIP2CntrStck 1;
BA_ "SignalType" SG_ 2159190016 ODI_AxIP2CntrStck "UNM";
BA_ "SignalLongName" SG_ 2159190016 ODI_AxIP2CntrStck "Open Display Interface AuxIP 2 CenterStack";
BA_ "VNSigAllNodes" SG_ 2159190016 ODI_AxIP2CntrStck 1;
BA_ "GenSigDeltaValue" SG_ 2159181824 ODI_CntrStck2AxIP 1;
BA_ "GenSigSendType" SG_ 2159181824 ODI_CntrStck2AxIP 12;
BA_ "VNSigInfotainment" SG_ 2159181824 ODI_CntrStck2AxIP 1;
BA_ "SignalType" SG_ 2159181824 ODI_CntrStck2AxIP "UNM";
BA_ "SignalLongName" SG_ 2159181824 ODI_CntrStck2AxIP "Open Display Interface CenterStack 2 AuxIP";
BA_ "VNSigAllNodes" SG_ 2159181824 ODI_CntrStck2AxIP 1;
BA_ "GenSigDeltaValue" SG_ 2159173632 ODI_IPC2CntrStck 1;
BA_ "GenSigSendType" SG_ 2159173632 ODI_IPC2CntrStck 12;
BA_ "VNSigInfotainment" SG_ 2159173632 ODI_IPC2CntrStck 1;
BA_ "SignalType" SG_ 2159173632 ODI_IPC2CntrStck "UNM";
BA_ "SignalLongName" SG_ 2159173632 ODI_IPC2CntrStck "Open Display Interface IPC 2 CenterStack";
BA_ "VNSigAllNodes" SG_ 2159173632 ODI_IPC2CntrStck 1;
BA_ "GenSigDeltaValue" SG_ 2159165440 ODI_CntrStck2IPC 1;
BA_ "GenSigSendType" SG_ 2159165440 ODI_CntrStck2IPC 12;
BA_ "VNSigInfotainment" SG_ 2159165440 ODI_CntrStck2IPC 1;
BA_ "SignalType" SG_ 2159165440 ODI_CntrStck2IPC "UNM";
BA_ "SignalLongName" SG_ 2159165440 ODI_CntrStck2IPC "Open Display Interface CenterStack 2 IPC";
BA_ "VNSigAllNodes" SG_ 2159165440 ODI_CntrStck2IPC 1;
BA_ "GenSigDeltaValue" SG_ 2159108096 ODI_AxIP2DAB 1;
BA_ "GenSigSendType" SG_ 2159108096 ODI_AxIP2DAB 12;
BA_ "VNSigInfotainment" SG_ 2159108096 ODI_AxIP2DAB 1;
BA_ "SignalType" SG_ 2159108096 ODI_AxIP2DAB "UNM";
BA_ "SignalLongName" SG_ 2159108096 ODI_AxIP2DAB "Open Display Interface AuxIP 2 DAB";
BA_ "VNSigAllNodes" SG_ 2159108096 ODI_AxIP2DAB 1;
BA_ "GenSigDeltaValue" SG_ 2159075328 ODI_IPC2DAB 1;
BA_ "GenSigSendType" SG_ 2159075328 ODI_IPC2DAB 12;
BA_ "VNSigInfotainment" SG_ 2159075328 ODI_IPC2DAB 1;
BA_ "SignalType" SG_ 2159075328 ODI_IPC2DAB "UNM";
BA_ "SignalLongName" SG_ 2159075328 ODI_IPC2DAB "Open Display Interface IPC 2 DAB";
BA_ "VNSigAllNodes" SG_ 2159075328 ODI_IPC2DAB 1;
BA_ "GenSigSendType" SG_ 2151718912 ChmVolSt 10;
BA_ "SignalType" SG_ 2151718912 ChmVolSt "ENM";
BA_ "SignalLongName" SG_ 2151718912 ChmVolSt "Chime Volume Status";
BA_ "VNSigAllNodes" SG_ 2151718912 ChmVolSt 1;
BA_ "GenSigSendType" SG_ 2151718912 ChmAct 10;
BA_ "GenSigSendOnInit" SG_ 2151718912 ChmAct 1;
BA_ "VNSigInfotainment" SG_ 2151718912 ChmAct 1;
BA_ "VNSigIntermediate" SG_ 2151718912 ChmAct 1;
BA_ "SignalType" SG_ 2151718912 ChmAct "BLN";
BA_ "SignalLongName" SG_ 2151718912 ChmAct "Chime Active";
BA_ "VNSigAllNodes" SG_ 2151718912 ChmAct 1;
BA_ "GenSigSendType" SG_ 2155479040 EleRngEstAdjCstStReq 10;
BA_ "VNSigInfotainment" SG_ 2155479040 EleRngEstAdjCstStReq 1;
BA_ "SignalType" SG_ 2155479040 EleRngEstAdjCstStReq "ENM";
BA_ "SignalLongName" SG_ 2155479040 EleRngEstAdjCstStReq "Electric Range Estimation Adjustment Customization Setting Request";
BA_ "VNSigAllNodes" SG_ 2155479040 EleRngEstAdjCstStReq 1;
BA_ "GenSigSendType" SG_ 2155479040 WPRSCstStReq 10;
BA_ "VNSigInfotainment" SG_ 2155479040 WPRSCstStReq 1;
BA_ "SignalType" SG_ 2155479040 WPRSCstStReq "ENM";
BA_ "SignalLongName" SG_ 2155479040 WPRSCstStReq "Wall Powered Remote Start Customization Setting Request";
BA_ "VNSigAllNodes" SG_ 2155479040 WPRSCstStReq 1;
BA_ "GenSigSendType" SG_ 2155479040 DrvStyPerfMdCsStReq 10;
BA_ "SignalType" SG_ 2155479040 DrvStyPerfMdCsStReq "ENM";
BA_ "SignalLongName" SG_ 2155479040 DrvStyPerfMdCsStReq "Driving Style Performance Mode Customization Setting Request";
BA_ "VNSigAllNodes" SG_ 2155479040 DrvStyPerfMdCsStReq 1;
BA_ "GenSigSendType" SG_ 2155479040 PsngStPerfMdCsStReq 10;
BA_ "SignalType" SG_ 2155479040 PsngStPerfMdCsStReq "ENM";
BA_ "SignalLongName" SG_ 2155479040 PsngStPerfMdCsStReq "Passenger Seat Performance Mode Customization Setting Request";
BA_ "VNSigAllNodes" SG_ 2155479040 PsngStPerfMdCsStReq 1;
BA_ "GenSigSendType" SG_ 2155479040 DrvrStPerfMdCsStReq 10;
BA_ "SignalType" SG_ 2155479040 DrvrStPerfMdCsStReq "ENM";
BA_ "SignalLongName" SG_ 2155479040 DrvrStPerfMdCsStReq "Driver Seat Performance Mode Customization Setting Request";
BA_ "VNSigAllNodes" SG_ 2155479040 DrvrStPerfMdCsStReq 1;
BA_ "GenSigSendType" SG_ 2155479040 ACCPerfMdCsStReq 10;
BA_ "SignalType" SG_ 2155479040 ACCPerfMdCsStReq "ENM";
BA_ "SignalLongName" SG_ 2155479040 ACCPerfMdCsStReq "Adaptive Cruise Control Performance Mode Customization Setting Request";
BA_ "VNSigAllNodes" SG_ 2155479040 ACCPerfMdCsStReq 1;
BA_ "GenSigSendType" SG_ 2155479040 ElvtdIdlCstStReq 10;
BA_ "SignalType" SG_ 2155479040 ElvtdIdlCstStReq "ENM";
BA_ "SignalLongName" SG_ 2155479040 ElvtdIdlCstStReq "Elevated Idle Customization Setting Request";
BA_ "VNSigAllNodes" SG_ 2155479040 ElvtdIdlCstStReq 1;
BA_ "GenSigSendType" SG_ 2155479040 PedFrndlyAlrtCsStReq 10;
BA_ "SignalType" SG_ 2155479040 PedFrndlyAlrtCsStReq "ENM";
BA_ "SignalLongName" SG_ 2155479040 PedFrndlyAlrtCsStReq "Pedestrian Friendly Alert Customization Setting Request";
BA_ "VNSigAllNodes" SG_ 2155479040 PedFrndlyAlrtCsStReq 1;
BA_ "GenSigSendType" SG_ 2155479040 SndPerfMdCsStRq 10;
BA_ "SignalType" SG_ 2155479040 SndPerfMdCsStRq "ENM";
BA_ "SignalLongName" SG_ 2155479040 SndPerfMdCsStRq "Sound Performance Mode Customization Setting Request";
BA_ "VNSigAllNodes" SG_ 2155479040 SndPerfMdCsStRq 1;
BA_ "GenSigSendType" SG_ 2155479040 DispPerfMdCsStRq 10;
BA_ "SignalType" SG_ 2155479040 DispPerfMdCsStRq "ENM";
BA_ "SignalLongName" SG_ 2155479040 DispPerfMdCsStRq "Display Performance Mode Customization Setting Request";
BA_ "VNSigAllNodes" SG_ 2155479040 DispPerfMdCsStRq 1;
BA_ "GenSigSendType" SG_ 2155479040 SusCustStngReq 10;
BA_ "GenSigSendOnInit" SG_ 2155479040 SusCustStngReq 1;
BA_ "SignalType" SG_ 2155479040 SusCustStngReq "ENM";
BA_ "SignalLongName" SG_ 2155479040 SusCustStngReq "Suspension Customization Setting Request";
BA_ "VNSigAllNodes" SG_ 2155479040 SusCustStngReq 1;
BA_ "GenSigSendType" SG_ 2155479040 StrCustStngReq 10;
BA_ "GenSigSendOnInit" SG_ 2155479040 StrCustStngReq 1;
BA_ "SignalType" SG_ 2155479040 StrCustStngReq "ENM";
BA_ "SignalLongName" SG_ 2155479040 StrCustStngReq "Steering Customization Setting Request";
BA_ "VNSigAllNodes" SG_ 2155479040 StrCustStngReq 1;
BA_ "GenSigSendType" SG_ 2155479040 RstrCustFctrDef 10;
BA_ "GenSigSendOnInit" SG_ 2155479040 RstrCustFctrDef 1;
BA_ "VNSigInfotainment" SG_ 2155479040 RstrCustFctrDef 1;
BA_ "SignalType" SG_ 2155479040 RstrCustFctrDef "ENM";
BA_ "SignalLongName" SG_ 2155479040 RstrCustFctrDef "Restore Customization Factory Defaults";
BA_ "VNSigAllNodes" SG_ 2155479040 RstrCustFctrDef 1;
BA_ "GenSigSendType" SG_ 2155479040 DrvlnCustStngReq 10;
BA_ "GenSigSendOnInit" SG_ 2155479040 DrvlnCustStngReq 1;
BA_ "SignalType" SG_ 2155479040 DrvlnCustStngReq "ENM";
BA_ "SignalLongName" SG_ 2155479040 DrvlnCustStngReq "Driveline Customization Setting Request";
BA_ "VNSigAllNodes" SG_ 2155479040 DrvlnCustStngReq 1;
BA_ "GenSigSendType" SG_ 2151383040 TreInfMonSysRstReq 10;
BA_ "SignalType" SG_ 2151383040 TreInfMonSysRstReq "BLN";
BA_ "SignalLongName" SG_ 2151383040 TreInfMonSysRstReq "Tire Inflation Monitoring System Reset Requested";
BA_ "VNSigAllNodes" SG_ 2151383040 TreInfMonSysRstReq 1;
BA_ "SignalType" SG_ 1350 DgnInf_LS546 "UNM";
BA_ "SignalLongName" SG_ 1350 DgnInf_LS546 "Diagnostic Information LS546";
BA_ "VNSigDiagnostic" SG_ 1350 DgnInf_LS546 1;
BA_ "VNSigAllNodes" SG_ 1350 DgnInf_LS546 1;
BA_ "SignalType" SG_ 1606 DgnInf "UNM";
BA_ "SignalLongName" SG_ 1606 DgnInf "Diagnostic Information";
BA_ "VNSigDiagnostic" SG_ 1606 DgnInf 1;
BA_ "VNSigAllNodes" SG_ 1606 DgnInf 1;
BA_ "SignalType" SG_ 1355 DgnInf_LS54B "UNM";
BA_ "SignalLongName" SG_ 1355 DgnInf_LS54B "Diagnostic Information LS54B";
BA_ "VNSigDiagnostic" SG_ 1355 DgnInf_LS54B 1;
BA_ "VNSigAllNodes" SG_ 1355 DgnInf_LS54B 1;
BA_ "SignalType" SG_ 1611 DgnInf "UNM";
BA_ "SignalLongName" SG_ 1611 DgnInf "Diagnostic Information";
BA_ "VNSigDiagnostic" SG_ 1611 DgnInf 1;
BA_ "VNSigAllNodes" SG_ 1611 DgnInf 1;
BA_ "SignalType" SG_ 1374 DgnInf_LS55E "UNM";
BA_ "SignalLongName" SG_ 1374 DgnInf_LS55E "Diagnostic Information LS55E";
BA_ "VNSigDiagnostic" SG_ 1374 DgnInf_LS55E 1;
BA_ "VNSigAllNodes" SG_ 1374 DgnInf_LS55E 1;
BA_ "SignalType" SG_ 1630 DgnInf "UNM";
BA_ "SignalLongName" SG_ 1630 DgnInf "Diagnostic Information";
BA_ "VNSigDiagnostic" SG_ 1630 DgnInf 1;
BA_ "VNSigAllNodes" SG_ 1630 DgnInf 1;
BA_ "GenSigSendType" SG_ 2155421696 PsvEntAprchDrctn 10;
BA_ "GenSigSendOnInit" SG_ 2155421696 PsvEntAprchDrctn 2;
BA_ "SignalType" SG_ 2155421696 PsvEntAprchDrctn "ENM";
BA_ "SignalLongName" SG_ 2155421696 PsvEntAprchDrctn "Passive Entry Approach Direction";
BA_ "VNSigAllNodes" SG_ 2155421696 PsvEntAprchDrctn 1;
BA_ "GenSigSendType" SG_ 2155421696 PsvEntApprchDtcd 10;
BA_ "GenSigSendOnInit" SG_ 2155421696 PsvEntApprchDtcd 2;
BA_ "SignalType" SG_ 2155421696 PsvEntApprchDtcd "BLN";
BA_ "SignalLongName" SG_ 2155421696 PsvEntApprchDtcd "Passive Entry Approach Detected";
BA_ "VNSigAllNodes" SG_ 2155421696 PsvEntApprchDtcd 1;
BA_ "GenSigSendType" SG_ 2155421696 PsvEntApprchCnfgReq 10;
BA_ "GenSigSendOnInit" SG_ 2155421696 PsvEntApprchCnfgReq 2;
BA_ "SignalType" SG_ 2155421696 PsvEntApprchCnfgReq "ENM";
BA_ "SignalLongName" SG_ 2155421696 PsvEntApprchCnfgReq "Passive Entry Approach Configuration Request";
BA_ "VNSigAllNodes" SG_ 2155421696 PsvEntApprchCnfgReq 1;
BA_ "GenSigSendType" SG_ 2155421696 ServKylsStSysIO 10;
BA_ "GenSigSendOnInit" SG_ 2155421696 ServKylsStSysIO 2;
BA_ "SignalType" SG_ 2155421696 ServKylsStSysIO "BLN";
BA_ "SignalLongName" SG_ 2155421696 ServKylsStSysIO "Service Keyless Start System Indication On";
BA_ "VNSigAllNodes" SG_ 2155421696 ServKylsStSysIO 1;
BA_ "GenSigDeltaValue" SG_ 2155421696 PsvEntChlng 1;
BA_ "GenSigSendType" SG_ 2155421696 PsvEntChlng 12;
BA_ "GenSigSendOnInit" SG_ 2155421696 PsvEntChlng 2;
BA_ "SignalType" SG_ 2155421696 PsvEntChlng "UNM";
BA_ "SignalLongName" SG_ 2155421696 PsvEntChlng "Passive Entry Challenge";
BA_ "VNSigAllNodes" SG_ 2155421696 PsvEntChlng 1;
BA_ "GenSigSendType" SG_ 2155413504 TireLRIPrsV 10;
BA_ "GenSigSendOnInit" SG_ 2155413504 TireLRIPrsV 1;
BA_ "SignalType" SG_ 2155413504 TireLRIPrsV "ENM";
BA_ "SignalLongName" SG_ 2155413504 TireLRIPrsV "Tire Left Rear Inner Pressure Validity";
BA_ "VNSigAllNodes" SG_ 2155413504 TireLRIPrsV 1;
BA_ "GenSigSendType" SG_ 2155413504 TireLRIPrsStat 10;
BA_ "GenSigSendOnInit" SG_ 2155413504 TireLRIPrsStat 1;
BA_ "SignalType" SG_ 2155413504 TireLRIPrsStat "ENM";
BA_ "SignalLongName" SG_ 2155413504 TireLRIPrsStat "Tire Left Rear Inner Pressure Status";
BA_ "VNSigAllNodes" SG_ 2155413504 TireLRIPrsStat 1;
BA_ "GenSigDeltaValue" SG_ 2155413504 TireLRIPrs 1;
BA_ "GenSigSendType" SG_ 2155413504 TireLRIPrs 12;
BA_ "GenSigSendOnInit" SG_ 2155413504 TireLRIPrs 1;
BA_ "SignalType" SG_ 2155413504 TireLRIPrs "UNM";
BA_ "SignalLongName" SG_ 2155413504 TireLRIPrs "Tire Left Rear Inner Pressure";
BA_ "GenSigStartValue" SG_ 2155413504 TireLRIPrs 255;
BA_ "VNSigAllNodes" SG_ 2155413504 TireLRIPrs 1;
BA_ "GenSigSendType" SG_ 2155413504 TireRRIPrsV 10;
BA_ "GenSigSendOnInit" SG_ 2155413504 TireRRIPrsV 1;
BA_ "SignalType" SG_ 2155413504 TireRRIPrsV "ENM";
BA_ "SignalLongName" SG_ 2155413504 TireRRIPrsV "Tire Right Rear Inner Pressure Validity";
BA_ "VNSigAllNodes" SG_ 2155413504 TireRRIPrsV 1;
BA_ "GenSigSendType" SG_ 2155413504 TireRRIPrsStat 10;
BA_ "GenSigSendOnInit" SG_ 2155413504 TireRRIPrsStat 1;
BA_ "SignalType" SG_ 2155413504 TireRRIPrsStat "ENM";
BA_ "SignalLongName" SG_ 2155413504 TireRRIPrsStat "Tire Right Rear Inner Pressure Status";
BA_ "VNSigAllNodes" SG_ 2155413504 TireRRIPrsStat 1;
BA_ "GenSigDeltaValue" SG_ 2155413504 TireRRIPrs 1;
BA_ "GenSigSendType" SG_ 2155413504 TireRRIPrs 12;
BA_ "GenSigSendOnInit" SG_ 2155413504 TireRRIPrs 1;
BA_ "SignalType" SG_ 2155413504 TireRRIPrs "UNM";
BA_ "SignalLongName" SG_ 2155413504 TireRRIPrs "Tire Right Rear Inner Pressure";
BA_ "GenSigStartValue" SG_ 2155413504 TireRRIPrs 255;
BA_ "VNSigAllNodes" SG_ 2155413504 TireRRIPrs 1;
BA_ "GenSigSendType" SG_ 2155413504 PsvLckngReqd 10;
BA_ "SignalType" SG_ 2155413504 PsvLckngReqd "BLN";
BA_ "SignalLongName" SG_ 2155413504 PsvLckngReqd "Passive Locking Requested";
BA_ "VNSigAllNodes" SG_ 2155413504 PsvLckngReqd 1;
BA_ "GenSigDeltaValue" SG_ 2155413504 PsvApprchVehId 1;
BA_ "GenSigSendType" SG_ 2155413504 PsvApprchVehId 12;
BA_ "SignalType" SG_ 2155413504 PsvApprchVehId "UNM";
BA_ "SignalLongName" SG_ 2155413504 PsvApprchVehId "Passive Approach Vehicle Identifier";
BA_ "VNSigAllNodes" SG_ 2155413504 PsvApprchVehId 1;
BA_ "GenSigSendType" SG_ 2155413504 DrvrDrKeyCylUlkSwAct 10;
BA_ "SignalType" SG_ 2155413504 DrvrDrKeyCylUlkSwAct "BLN";
BA_ "SignalLongName" SG_ 2155413504 DrvrDrKeyCylUlkSwAct "Driver Door Key Cylinder Unlock Switch Active";
BA_ "VNSigAllNodes" SG_ 2155413504 DrvrDrKeyCylUlkSwAct 1;
BA_ "GenSigSendType" SG_ 2155413504 DrvrDrKeyCylUlkSwActV 10;
BA_ "SignalType" SG_ 2155413504 DrvrDrKeyCylUlkSwActV "ENM";
BA_ "SignalLongName" SG_ 2155413504 DrvrDrKeyCylUlkSwActV "Driver Door Key Cylinder Unlock Switch Active Validity";
BA_ "VNSigAllNodes" SG_ 2155413504 DrvrDrKeyCylUlkSwActV 1;
BA_ "GenSigSendType" SG_ 2159026176 ODD_InvldData 10;
BA_ "VNSigInfotainment" SG_ 2159026176 ODD_InvldData 1;
BA_ "SignalType" SG_ 2159026176 ODD_InvldData "BLN";
BA_ "PacketOrder" SG_ 2159026176 ODD_InvldData 2;
BA_ "SignalLongName" SG_ 2159026176 ODD_InvldData "Open Display Interface Dynamic Data : Invalid Data";
BA_ "VNSigAllNodes" SG_ 2159026176 ODD_InvldData 1;
BA_ "GenSigDeltaValue" SG_ 2159026176 ODD_FUCID 1;
BA_ "GenSigSendType" SG_ 2159026176 ODD_FUCID 12;
BA_ "VNSigInfotainment" SG_ 2159026176 ODD_FUCID 1;
BA_ "SignalType" SG_ 2159026176 ODD_FUCID "UNM";
BA_ "PacketOrder" SG_ 2159026176 ODD_FUCID 3;
BA_ "SignalLongName" SG_ 2159026176 ODD_FUCID "Open Display Interface Dynamic Data : Functional Unit Class ID";
BA_ "VNSigAllNodes" SG_ 2159026176 ODD_FUCID 1;
BA_ "GenSigDeltaValue" SG_ 2159026176 ODD_DataVal 1;
BA_ "GenSigSendType" SG_ 2159026176 ODD_DataVal 12;
BA_ "VNSigInfotainment" SG_ 2159026176 ODD_DataVal 1;
BA_ "SignalType" SG_ 2159026176 ODD_DataVal "UNM";
BA_ "PacketOrder" SG_ 2159026176 ODD_DataVal 5;
BA_ "SignalLongName" SG_ 2159026176 ODD_DataVal "Open Display Interface Dynamic Data : Data Value";
BA_ "VNSigAllNodes" SG_ 2159026176 ODD_DataVal 1;
BA_ "GenSigDeltaValue" SG_ 2159026176 ODD_DataType 1;
BA_ "GenSigSendType" SG_ 2159026176 ODD_DataType 10;
BA_ "VNSigInfotainment" SG_ 2159026176 ODD_DataType 1;
BA_ "SignalType" SG_ 2159026176 ODD_DataType "ENM";
BA_ "PacketOrder" SG_ 2159026176 ODD_DataType 1;
BA_ "SignalLongName" SG_ 2159026176 ODD_DataType "Open Display Interface Dynamic Data : Data Type";
BA_ "VNSigAllNodes" SG_ 2159026176 ODD_DataType 1;
BA_ "GenSigDeltaValue" SG_ 2159026176 ODD_DataId 1;
BA_ "GenSigSendType" SG_ 2159026176 ODD_DataId 12;
BA_ "VNSigInfotainment" SG_ 2159026176 ODD_DataId 1;
BA_ "SignalType" SG_ 2159026176 ODD_DataId "UNM";
BA_ "PacketOrder" SG_ 2159026176 ODD_DataId 4;
BA_ "SignalLongName" SG_ 2159026176 ODD_DataId "Open Display Interface Dynamic Data : Data ID";
BA_ "VNSigAllNodes" SG_ 2159026176 ODD_DataId 1;
BA_REL_ "GenSigSuprvResp" BU_SG_REL_ V2V_LS SG_ 2150277120 PsngSysLong 1;
BA_REL_ "GenSigSuprvResp" BU_SG_REL_ VICM_LS SG_ 2150277120 PsngSysLong 1;
BA_REL_ "GenSigSuprvResp" BU_SG_REL_ EOCM_F_LS SG_ 2150277120 PsngSysLong 1;
BA_REL_ "GenSigSuprvResp" BU_SG_REL_ EOCM_F_LS SG_ 2150277120 PsngSysLong 1;
BA_REL_ "GenSigSuprvResp" BU_SG_REL_ V2V_LS SG_ 2150277120 PsngSysLat 1;
BA_REL_ "GenSigSuprvResp" BU_SG_REL_ VICM_LS SG_ 2150277120 PsngSysLat 1;
BA_REL_ "GenSigSuprvResp" BU_SG_REL_ EOCM_F_LS SG_ 2150277120 PsngSysLat 1;
BA_REL_ "GenSigSuprvResp" BU_SG_REL_ EOCM_F_LS SG_ 2150277120 PsngSysLat 1;
BA_REL_ "GenSigSuprvResp" BU_SG_REL_ V2V_LS SG_ 2150285312 PsngSysHding 1;
BA_REL_ "GenSigSuprvResp" BU_SG_REL_ FCM_LS SG_ 2150285312 PsngSysHding 1;
BA_REL_ "GenSigSuprvResp" BU_SG_REL_ EOCM_F_LS SG_ 2150285312 PsngSysHding 1;
BA_REL_ "GenSigSuprvResp" BU_SG_REL_ BSM_LS SG_ 2150285312 PsngSysElvtn 1;
BA_REL_ "GenSigSuprvResp" BU_SG_REL_ V2V_LS SG_ 2150285312 PsngSysElvtn 1;
BA_REL_ "GenSigSuprvResp" BU_SG_REL_ VICM_LS SG_ 2150285312 PsngSysElvtn 1;
BA_REL_ "GenSigSuprvResp" BU_SG_REL_ VICM_LS SG_ 2150285312 PsngSysElvtn 1;
BA_REL_ "GenSigSuprvResp" BU_SG_REL_ EOCM_F_LS SG_ 2150285312 PsngSysElvtn 1;
BA_REL_ "GenSigSuprvResp" BU_SG_REL_ V2V_LS SG_ 2150285312 PsngSysDilPrcs 1;
BA_REL_ "GenSigSuprvResp" BU_SG_REL_ VICM_LS SG_ 2150285312 PsngSysDilPrcs 1;
BA_REL_ "GenSigSuprvResp" BU_SG_REL_ EOCM_F_LS SG_ 2150285312 PsngSysDilPrcs 1;
BA_REL_ "GenSigSuprvResp" BU_SG_REL_ EOCM_F_LS SG_ 2150285312 PsngSysDilPrcs 1;
BA_REL_ "GenSigSuprvResp" BU_SG_REL_ V2V_LS SG_ 2150285312 PsngSysCalcSpd 1;
BA_REL_ "GenSigSuprvResp" BU_SG_REL_ VICM_LS SG_ 2150285312 PsngSysCalcSpd 1;
BA_REL_ "GenSigSuprvResp" BU_SG_REL_ EOCM_F_LS SG_ 2150285312 PsngSysCalcSpd 1;
BA_REL_ "GenSigSuprvResp" BU_SG_REL_ EOCM_F_LS SG_ 2150285312 PsngSysCalcSpd 1;
BA_REL_ "GenSigSuprvResp" BU_SG_REL_ ISRVM_LS SG_ 2151890944 TICR_Ind1FlshRtOn 1;
BA_REL_ "GenSigSuprvResp" BU_SG_REL_ HBSM_LS SG_ 2151890944 TICR_Ind1FlshRtOn 1;
BA_REL_ "GenSigSuprvResp" BU_SG_REL_ ISRVM_LS SG_ 2151890944 TICR_Ind1FlshRtOff 1;
BA_REL_ "GenSigSuprvResp" BU_SG_REL_ HBSM_LS SG_ 2151890944 TICR_Ind1FlshRtOff 1;
BA_REL_ "GenSigSuprvResp" BU_SG_REL_ ISRVM_LS SG_ 2151890944 TICR_Ind1Cnt 1;
BA_REL_ "GenSigSuprvResp" BU_SG_REL_ HBSM_LS SG_ 2151890944 TICR_Ind1Cnt 1;
BA_REL_ "GenSigSuprvResp" BU_SG_REL_ ISRVM_LS SG_ 2151890944 TICR_Ind1 1;
BA_REL_ "GenSigSuprvResp" BU_SG_REL_ HBSM_LS SG_ 2151890944 TICR_Ind1 1;
BA_REL_ "GenSigSuprvResp" BU_SG_REL_ ISRVM_LS SG_ 2151890944 TICR_Ind1Req 1;
BA_REL_ "GenSigSuprvResp" BU_SG_REL_ HBSM_LS SG_ 2151890944 TICR_Ind1Req 1;
BA_REL_ "GenSigSuprvResp" BU_SG_REL_ VPM_LS SG_ 2149990400 ElcTransRngRq 1;
BA_REL_ "GenSigSuprvResp" BU_SG_REL_ EOCM2B_K1_LS SG_ 2149990400 TrnsfrCsRngShfSpdLmt 1;
BA_REL_ "GenSigSuprvResp" BU_SG_REL_ EOCM2A_K1_LS SG_ 2149990400 TrnsfrCsRngShfSpdLmt 1;
BA_REL_ "GenSigSuprvResp" BU_SG_REL_ IPC_LS SG_ 2149990400 TrnsfrCsRngShfSpdLmt 1;
BA_REL_ "GenSigSuprvResp" BU_SG_REL_ EOCM2B_K1_LS SG_ 2149990400 SecAxlOperMod 1;
BA_REL_ "GenSigSuprvResp" BU_SG_REL_ EOCM2A_K1_LS SG_ 2149990400 SecAxlOperMod 1;
BA_REL_ "GenSigSuprvResp" BU_SG_REL_ IPC_LS SG_ 2149990400 SecAxlOperMod 1;
BA_REL_ "GenSigSuprvResp" BU_SG_REL_ EOCM2B_K1_LS SG_ 2149990400 InstFuelConsmpRate 1;
BA_REL_ "GenSigSuprvResp" BU_SG_REL_ EOCM2A_K1_LS SG_ 2149990400 InstFuelConsmpRate 1;
BA_REL_ "GenSigSuprvResp" BU_SG_REL_ EOCM2B_K1_LS SG_ 2149990400 MotStBltUnblIO 1;
BA_REL_ "GenSigSuprvResp" BU_SG_REL_ EOCM2A_K1_LS SG_ 2149990400 MotStBltUnblIO 1;
BA_REL_ "GenSigSuprvResp" BU_SG_REL_ EOCM2B_K1_LS SG_ 2149990400 MotStBltFldIO 1;
BA_REL_ "GenSigSuprvResp" BU_SG_REL_ EOCM2A_K1_LS SG_ 2149990400 MotStBltFldIO 1;
BA_REL_ "GenSigSuprvResp" BU_SG_REL_ EOCM2B_K1_LS SG_ 2149990400 TransNtrlCntrlMdStat 1;
BA_REL_ "GenSigSuprvResp" BU_SG_REL_ EOCM2A_K1_LS SG_ 2149990400 TransNtrlCntrlMdStat 1;
BA_REL_ "GenSigSuprvResp" BU_SG_REL_ EOCM2B_K1_LS SG_ 2149990400 TrlrWiringFltIO 1;
BA_REL_ "GenSigSuprvResp" BU_SG_REL_ EOCM2A_K1_LS SG_ 2149990400 TrlrWiringFltIO 1;
BA_REL_ "GenSigSuprvResp" BU_SG_REL_ EOCM2B_K1_LS SG_ 2149990400 TrlrCnctdIO 1;
BA_REL_ "GenSigSuprvResp" BU_SG_REL_ EOCM2A_K1_LS SG_ 2149990400 TrlrCnctdIO 1;
BA_REL_ "GenSigSuprvResp" BU_SG_REL_ EOCM_F_LS SG_ 2149990400 TrlrCnctdIO 1;
BA_REL_ "GenSigSuprvResp" BU_SG_REL_ FCM_LS SG_ 2149990400 TrlrCnctdIO 1;
BA_REL_ "GenSigSuprvResp" BU_SG_REL_ EOCM2B_K1_LS SG_ 2149990400 TrlrBrkngGainSetIO 1;
BA_REL_ "GenSigSuprvResp" BU_SG_REL_ EOCM2A_K1_LS SG_ 2149990400 TrlrBrkngGainSetIO 1;
BA_REL_ "GenSigVDAFailComment" BU_SG_REL_ IPC_LS SG_ 2149990400 TrlrBrkngGainSetIO "TrlrBrkngVDA";
BA_REL_ "GenSigVDAFailResp" BU_SG_REL_ IPC_LS SG_ 2149990400 TrlrBrkngGainSetIO 1;
BA_REL_ "GenSigSuprvResp" BU_SG_REL_ IPC_LS SG_ 2149990400 TrlrBrkngGainSetIO 1;
BA_REL_ "GenSigSuprvResp" BU_SG_REL_ EOCM2B_K1_LS SG_ 2149990400 TrlrBrkngGainSet 1;
BA_REL_ "GenSigSuprvResp" BU_SG_REL_ EOCM2A_K1_LS SG_ 2149990400 TrlrBrkngGainSet 1;
BA_REL_ "GenSigVDAFailComment" BU_SG_REL_ IPC_LS SG_ 2149990400 TrlrBrkngGainSet "TrlrBrkngVDA";
BA_REL_ "GenSigVDAFailResp" BU_SG_REL_ IPC_LS SG_ 2149990400 TrlrBrkngGainSet 1;
BA_REL_ "GenSigSuprvResp" BU_SG_REL_ IPC_LS SG_ 2149990400 TrlrBrkngGainSet 1;
BA_REL_ "GenSigSuprvResp" BU_SG_REL_ EOCM2B_K1_LS SG_ 2149990400 TrlrBrkngFrcOtpt 1;
BA_REL_ "GenSigSuprvResp" BU_SG_REL_ EOCM2A_K1_LS SG_ 2149990400 TrlrBrkngFrcOtpt 1;
BA_REL_ "GenSigSuprvResp" BU_SG_REL_ EOCM2B_K1_LS SG_ 2149990400 SrvTrlrBrkngSysIO 1;
BA_REL_ "GenSigSuprvResp" BU_SG_REL_ EOCM2A_K1_LS SG_ 2149990400 SrvTrlrBrkngSysIO 1;
BA_REL_ "GenSigVDAFailComment" BU_SG_REL_ IPC_LS SG_ 2149990400 SrvTrlrBrkngSysIO "TrlrBrkngVDA";
BA_REL_ "GenSigVDAFailResp" BU_SG_REL_ IPC_LS SG_ 2149990400 SrvTrlrBrkngSysIO 1;
BA_REL_ "GenSigSuprvResp" BU_SG_REL_ IPC_LS SG_ 2149990400 SrvTrlrBrkngSysIO 1;
BA_REL_ "GenSigSuprvResp" BU_SG_REL_ EOCM2B_K1_LS SG_ 2149990400 ChkTrlrIO 1;
BA_REL_ "GenSigSuprvResp" BU_SG_REL_ EOCM2A_K1_LS SG_ 2149990400 ChkTrlrIO 1;
BA_REL_ "GenSigSuprvResp" BU_SG_REL_ EOCM2B_K1_LS SG_ 2149990400 TrlrHtchSwAtv_ITBC 1;
BA_REL_ "GenSigSuprvResp" BU_SG_REL_ EOCM2A_K1_LS SG_ 2149990400 TrlrHtchSwAtv_ITBC 1;
BA_REL_ "GenSigVDAFailComment" BU_SG_REL_ IPC_LS SG_ 2149990400 TrlrHtchSwAtv_ITBC "Trailer Braking Virtual Device Availability";
BA_REL_ "GenSigVDAFailResp" BU_SG_REL_ IPC_LS SG_ 2149990400 TrlrHtchSwAtv_ITBC 1;
BA_REL_ "GenSigSuprvResp" BU_SG_REL_ IPC_LS SG_ 2149990400 TrlrHtchSwAtv_ITBC 1;
BA_REL_ "GenSigSuprvResp" BU_SG_REL_ EOCM2B_K1_LS SG_ 2149990400 ABSIO 1;
BA_REL_ "GenSigSuprvResp" BU_SG_REL_ EOCM2A_K1_LS SG_ 2149990400 ABSIO 1;
BA_REL_ "GenSigSuprvResp" BU_SG_REL_ SDM_LS SG_ 2149990400 ABSIO 1;
BA_REL_ "GenSigVDAFailComment" BU_SG_REL_ IPC_LS SG_ 2149990400 ABSIO "BrkSysVDA";
BA_REL_ "GenSigVDAFailResp" BU_SG_REL_ IPC_LS SG_ 2149990400 ABSIO 1;
BA_REL_ "GenSigSuprvResp" BU_SG_REL_ IPC_LS SG_ 2149990400 ABSIO 1;
BA_REL_ "GenSigSuprvResp" BU_SG_REL_ EOCM2B_K1_LS SG_ 2149990400 ACCHdwayStngIO 1;
BA_REL_ "GenSigSuprvResp" BU_SG_REL_ EOCM2A_K1_LS SG_ 2149990400 ACCHdwayStngIO 1;
BA_REL_ "GenSigVDAFailComment" BU_SG_REL_ CHUD_LS SG_ 2149990400 ACCHdwayStngIO "AdapCrsCntVDA";
BA_REL_ "GenSigVDAFailResp" BU_SG_REL_ CHUD_LS SG_ 2149990400 ACCHdwayStngIO 1;
BA_REL_ "GenSigSuprvResp" BU_SG_REL_ CHUD_LS SG_ 2149990400 ACCHdwayStngIO 1;
BA_REL_ "GenSigVDAFailComment" BU_SG_REL_ HUD_LS SG_ 2149990400 ACCHdwayStngIO "AdapCrsCntVDA";
BA_REL_ "GenSigVDAFailResp" BU_SG_REL_ HUD_LS SG_ 2149990400 ACCHdwayStngIO 1;
BA_REL_ "GenSigSuprvResp" BU_SG_REL_ HUD_LS SG_ 2149990400 ACCHdwayStngIO 1;
BA_REL_ "GenSigSuprvResp" BU_SG_REL_ EOCM2B_K1_LS SG_ 2149990400 StpOnBrkToRelPBIndOn 1;
BA_REL_ "GenSigSuprvResp" BU_SG_REL_ EOCM2A_K1_LS SG_ 2149990400 StpOnBrkToRelPBIndOn 1;
BA_REL_ "GenSigSuprvResp" BU_SG_REL_ EOCM2B_K1_LS SG_ 2149990400 ACCDrvrSeltdSpdIO 1;
BA_REL_ "GenSigSuprvResp" BU_SG_REL_ EOCM2A_K1_LS SG_ 2149990400 ACCDrvrSeltdSpdIO 1;
BA_REL_ "GenSigVDAFailComment" BU_SG_REL_ CHUD_LS SG_ 2149990400 ACCDrvrSeltdSpdIO "AdapCrsCntVDA";
BA_REL_ "GenSigVDAFailResp" BU_SG_REL_ CHUD_LS SG_ 2149990400 ACCDrvrSeltdSpdIO 1;
BA_REL_ "GenSigSuprvResp" BU_SG_REL_ CHUD_LS SG_ 2149990400 ACCDrvrSeltdSpdIO 1;
BA_REL_ "GenSigVDAFailComment" BU_SG_REL_ HUD_LS SG_ 2149990400 ACCDrvrSeltdSpdIO "AdapCrsCntVDA";
BA_REL_ "GenSigVDAFailResp" BU_SG_REL_ HUD_LS SG_ 2149990400 ACCDrvrSeltdSpdIO 1;
BA_REL_ "GenSigSuprvResp" BU_SG_REL_ HUD_LS SG_ 2149990400 ACCDrvrSeltdSpdIO 1;
BA_REL_ "GenSigSuprvResp" BU_SG_REL_ EOCM2B_K1_LS SG_ 2149990400 TreInfMonSysRstPrfmd 1;
BA_REL_ "GenSigSuprvResp" BU_SG_REL_ EOCM2A_K1_LS SG_ 2149990400 TreInfMonSysRstPrfmd 1;
BA_REL_ "GenSigSuprvResp" BU_SG_REL_ EOCM2B_K1_LS SG_ 2149990400 DrvThrtlOvrdIO 1;
BA_REL_ "GenSigSuprvResp" BU_SG_REL_ EOCM2A_K1_LS SG_ 2149990400 DrvThrtlOvrdIO 1;
BA_REL_ "GenSigVDAFailComment" BU_SG_REL_ CHUD_LS SG_ 2149990400 DrvThrtlOvrdIO "AdapCrsCntVDA";
BA_REL_ "GenSigVDAFailResp" BU_SG_REL_ CHUD_LS SG_ 2149990400 DrvThrtlOvrdIO 1;
BA_REL_ "GenSigSuprvResp" BU_SG_REL_ CHUD_LS SG_ 2149990400 DrvThrtlOvrdIO 1;
BA_REL_ "GenSigVDAFailComment" BU_SG_REL_ HUD_LS SG_ 2149990400 DrvThrtlOvrdIO "AdapCrsCntVDA";
BA_REL_ "GenSigVDAFailResp" BU_SG_REL_ HUD_LS SG_ 2149990400 DrvThrtlOvrdIO 1;
BA_REL_ "GenSigSuprvResp" BU_SG_REL_ HUD_LS SG_ 2149990400 DrvThrtlOvrdIO 1;
BA_REL_ "GenSigSuprvResp" BU_SG_REL_ IPC_LS SG_ 2155380736 StrAsstRdcdLvl3IO 1;
BA_REL_ "GenSigSuprvResp" BU_SG_REL_ IPC_LS SG_ 2155380736 StrAsstRdcdLvl2IO 1;
BA_REL_ "GenSigSuprvResp" BU_SG_REL_ EOCM2B_K1_LS SG_ 2155380736 StrngAsstRdcdIO 1;
BA_REL_ "GenSigSuprvResp" BU_SG_REL_ EOCM2A_K1_LS SG_ 2155380736 StrngAsstRdcdIO 1;
BA_REL_ "GenSigSuprvResp" BU_SG_REL_ IPC_LS SG_ 2155380736 StrngAsstRdcdIO 1;
BA_REL_ "GenSigSuprvResp" BU_SG_REL_ EOCM2B_K1_LS SG_ 2155380736 ARSFlrIO 1;
BA_REL_ "GenSigSuprvResp" BU_SG_REL_ EOCM2A_K1_LS SG_ 2155380736 ARSFlrIO 1;
BA_REL_ "GenSigSuprvResp" BU_SG_REL_ APA_LS SG_ 2155380736 ARSFlrIO 1;
BA_REL_ "GenSigSuprvResp" BU_SG_REL_ EOCM2B_K1_LS SG_ 2155380736 PwrPkFnSpd 1;
BA_REL_ "GenSigSuprvResp" BU_SG_REL_ EOCM2A_K1_LS SG_ 2155380736 PwrPkFnSpd 1;
BA_REL_ "GenSigSuprvResp" BU_SG_REL_ LCM_LS SG_ 2155380736 PwrPkFnSpd 1;
BA_REL_ "GenSigSuprvResp" BU_SG_REL_ PTM_LS SG_ 2155380736 PwrPkFnSpd 1;
BA_REL_ "GenSigSuprvResp" BU_SG_REL_ EOCM2B_K1_LS SG_ 2155380736 PwrPckAirInTempFlt 1;
BA_REL_ "GenSigSuprvResp" BU_SG_REL_ EOCM2A_K1_LS SG_ 2155380736 PwrPckAirInTempFlt 1;
BA_REL_ "GenSigSuprvResp" BU_SG_REL_ EOCM2B_K1_LS SG_ 2155380736 PTExPrtclFltrWrn2IO 1;
BA_REL_ "GenSigSuprvResp" BU_SG_REL_ EOCM2A_K1_LS SG_ 2155380736 PTExPrtclFltrWrn2IO 1;
BA_REL_ "GenSigSuprvResp" BU_SG_REL_ EOCM2B_K1_LS SG_ 2155380736 EngOilHotIO 1;
BA_REL_ "GenSigSuprvResp" BU_SG_REL_ EOCM2A_K1_LS SG_ 2155380736 EngOilHotIO 1;
BA_REL_ "GenSigSuprvResp" BU_SG_REL_ EOCM2B_K1_LS SG_ 2155380736 EngWtrInFlIO 1;
BA_REL_ "GenSigSuprvResp" BU_SG_REL_ EOCM2A_K1_LS SG_ 2155380736 EngWtrInFlIO 1;
BA_REL_ "GenSigSuprvResp" BU_SG_REL_ EOCM2B_K1_LS SG_ 2155380736 AdvFrntLghtSysIndRq 1;
BA_REL_ "GenSigSuprvResp" BU_SG_REL_ EOCM2A_K1_LS SG_ 2155380736 AdvFrntLghtSysIndRq 1;
BA_REL_ "GenSigSuprvResp" BU_SG_REL_ EOCM_F_LS SG_ 2155380736 AdvFrntLghtSysIndRq 1;
BA_REL_ "GenSigSuprvResp" BU_SG_REL_ EOCM2B_K1_LS SG_ 2155380736 PTExPrtclFltrWrnIO 1;
BA_REL_ "GenSigSuprvResp" BU_SG_REL_ EOCM2A_K1_LS SG_ 2155380736 PTExPrtclFltrWrnIO 1;
BA_REL_ "GenSigSuprvResp" BU_SG_REL_ EOCM2B_K1_LS SG_ 2155380736 AirCndOffIO 1;
BA_REL_ "GenSigSuprvResp" BU_SG_REL_ EOCM2A_K1_LS SG_ 2155380736 AirCndOffIO 1;
BA_REL_ "GenSigSuprvResp" BU_SG_REL_ EOCM2B_K1_LS SG_ 2155380736 HdLtLvlFlrIO 1;
BA_REL_ "GenSigSuprvResp" BU_SG_REL_ EOCM2A_K1_LS SG_ 2155380736 HdLtLvlFlrIO 1;
BA_REL_ "GenSigSuprvResp" BU_SG_REL_ EOCM2B_K1_LS SG_ 2155380736 PwrStrIO 1;
BA_REL_ "GenSigSuprvResp" BU_SG_REL_ EOCM2A_K1_LS SG_ 2155380736 PwrStrIO 1;
BA_REL_ "GenSigSuprvResp" BU_SG_REL_ EOCM2B_K1_LS SG_ 2155380736 EngHt_StpEngIO 1;
BA_REL_ "GenSigSuprvResp" BU_SG_REL_ EOCM2A_K1_LS SG_ 2155380736 EngHt_StpEngIO 1;
BA_REL_ "GenSigSuprvResp" BU_SG_REL_ EOCM2B_K1_LS SG_ 2155380736 CkFlFilrCapIO 1;
BA_REL_ "GenSigSuprvResp" BU_SG_REL_ EOCM2A_K1_LS SG_ 2155380736 CkFlFilrCapIO 1;
BA_REL_ "GenSigSuprvResp" BU_SG_REL_ EOCM2B_K1_LS SG_ 2155380736 RdcdPwrIO 1;
BA_REL_ "GenSigSuprvResp" BU_SG_REL_ EOCM2A_K1_LS SG_ 2155380736 RdcdPwrIO 1;
BA_REL_ "GenSigVDAFailComment" BU_SG_REL_ SDM_LS SG_ 2155380736 RdcdPwrIO "Engine Virtual Device Availability";
BA_REL_ "GenSigVDAFailResp" BU_SG_REL_ SDM_LS SG_ 2155380736 RdcdPwrIO 1;
BA_REL_ "GenSigSuprvResp" BU_SG_REL_ SDM_LS SG_ 2155380736 RdcdPwrIO 1;
BA_REL_ "GenSigSuprvResp" BU_SG_REL_ EOCM2B_K1_LS SG_ 2155380736 EngOilPrsLwIO 1;
BA_REL_ "GenSigSuprvResp" BU_SG_REL_ EOCM2A_K1_LS SG_ 2155380736 EngOilPrsLwIO 1;
BA_REL_ "GenSigSuprvResp" BU_SG_REL_ EOCM2B_K1_LS SG_ 2155380736 EngOilLvlLwIO 1;
BA_REL_ "GenSigSuprvResp" BU_SG_REL_ EOCM2A_K1_LS SG_ 2155380736 EngOilLvlLwIO 1;
BA_REL_ "GenSigSuprvResp" BU_SG_REL_ EOCM2B_K1_LS SG_ 2155380736 EngOilChngIO 1;
BA_REL_ "GenSigSuprvResp" BU_SG_REL_ EOCM2A_K1_LS SG_ 2155380736 EngOilChngIO 1;
BA_REL_ "GenSigSuprvResp" BU_SG_REL_ EOCM2B_K1_LS SG_ 2155380736 EngHotFuelEnrchmntIO 1;
BA_REL_ "GenSigSuprvResp" BU_SG_REL_ EOCM2A_K1_LS SG_ 2155380736 EngHotFuelEnrchmntIO 1;
BA_REL_ "GenSigSuprvResp" BU_SG_REL_ EOCM2B_K1_LS SG_ 2155380736 DslGlwPlgIO 1;
BA_REL_ "GenSigSuprvResp" BU_SG_REL_ EOCM2A_K1_LS SG_ 2155380736 DslGlwPlgIO 1;
BA_REL_ "GenSigSuprvResp" BU_SG_REL_ EOCM2B_K1_LS SG_ 2155380736 SrvLevSysIO 1;
BA_REL_ "GenSigSuprvResp" BU_SG_REL_ EOCM2A_K1_LS SG_ 2155380736 SrvLevSysIO 1;
BA_REL_ "GenSigVDAFailComment" BU_SG_REL_ IPC_LS SG_ 2155380736 SrvLevSysIO "Rear Leveling Virtual Device Availability";
BA_REL_ "GenSigVDAFailResp" BU_SG_REL_ IPC_LS SG_ 2155380736 SrvLevSysIO 1;
BA_REL_ "GenSigSuprvResp" BU_SG_REL_ IPC_LS SG_ 2155380736 SrvLevSysIO 1;
BA_REL_ "GenSigSuprvResp" BU_SG_REL_ EOCM2B_K1_LS SG_ 2155380736 VehOvrLdIndOn 1;
BA_REL_ "GenSigSuprvResp" BU_SG_REL_ EOCM2A_K1_LS SG_ 2155380736 VehOvrLdIndOn 1;
BA_REL_ "GenSigVBitResp" BU_SG_REL_ AGC_LS SG_ 2150498304 EngOilPrs 1;
BA_REL_ "GenSigVDAFailComment" BU_SG_REL_ AGC_LS SG_ 2150498304 EngOilPrs "Engine Virtual Device Availability";
BA_REL_ "GenSigVDAFailResp" BU_SG_REL_ AGC_LS SG_ 2150498304 EngOilPrs 1;
BA_REL_ "GenSigSuprvResp" BU_SG_REL_ AGC_LS SG_ 2150498304 EngOilPrs 1;
BA_REL_ "GenSigVBitResp" BU_SG_REL_ AGC_LS SG_ 2150498304 EngOilTmp 1;
BA_REL_ "GenSigVDAFailComment" BU_SG_REL_ AGC_LS SG_ 2150498304 EngOilTmp "Engine Virtual Device Availability";
BA_REL_ "GenSigVDAFailResp" BU_SG_REL_ AGC_LS SG_ 2150498304 EngOilTmp 1;
BA_REL_ "GenSigSuprvResp" BU_SG_REL_ AGC_LS SG_ 2150498304 EngOilTmp 1;
BA_REL_ "GenSigVBitResp" BU_SG_REL_ AGC_LS SG_ 2150498304 TrnOilTmp 1;
BA_REL_ "GenSigVDAFailComment" BU_SG_REL_ AGC_LS SG_ 2150498304 TrnOilTmp "Transmission Virtual Device Availability";
BA_REL_ "GenSigVDAFailResp" BU_SG_REL_ AGC_LS SG_ 2150498304 TrnOilTmp 1;
BA_REL_ "GenSigSuprvResp" BU_SG_REL_ AGC_LS SG_ 2150498304 TrnOilTmp 1;
BA_REL_ "GenSigSuprvResp" BU_SG_REL_ CSM_LS SG_ 2150498304 EngCltTmp 1;
BA_REL_ "GenSigSuprvResp" BU_SG_REL_ RadioHead_LS SG_ 2150498304 EngCltTmp 1;
BA_REL_ "GenSigSuprvResp" BU_SG_REL_ RadioHead_LS SG_ 2150498304 EngCltTmp 1;
BA_REL_ "GenSigSuprvResp" BU_SG_REL_ ECC_LS SG_ 2150498304 EngCltTmp 1;
BA_REL_ "GenSigSuprvResp" BU_SG_REL_ ECC_LS SG_ 2150498304 EngCltTmp 1;
BA_REL_ "GenSigSuprvResp" BU_SG_REL_ ECC_LS SG_ 2150498304 EngCltTmp 1;
BA_REL_ "GenSigVDAFailComment" BU_SG_REL_ PSD_R_LS SG_ 2150498304 OAT_PT_EstM "Engine Virtual Device Availability";
BA_REL_ "GenSigVDAFailResp" BU_SG_REL_ PSD_R_LS SG_ 2150498304 OAT_PT_EstM 1;
BA_REL_ "GenSigSuprvResp" BU_SG_REL_ PSD_R_LS SG_ 2150498304 OAT_PT_EstM 1;
BA_REL_ "GenSigVDAFailComment" BU_SG_REL_ PSD_L_LS SG_ 2150498304 OAT_PT_EstM "Engine Virtual Device Availability";
BA_REL_ "GenSigVDAFailResp" BU_SG_REL_ PSD_L_LS SG_ 2150498304 OAT_PT_EstM 1;
BA_REL_ "GenSigSuprvResp" BU_SG_REL_ PSD_L_LS SG_ 2150498304 OAT_PT_EstM 1;
BA_REL_ "GenSigSuprvResp" BU_SG_REL_ EOCM_F_LS SG_ 2151047168 HUDActv 1;
BA_REL_ "GenSigSuprvResp" BU_SG_REL_ BCM_LS SG_ 2151047168 HUDActv 1;
BA_REL_ "GenSigSuprvResp" BU_SG_REL_ RadioHead_LS SG_ 2149900288 BTTethrngPrngReq 1;
BA_REL_ "GenSigSuprvResp" BU_SG_REL_ BCM_LS SG_ 2149900288 EnhSrvVisAlRq 1;
BA_REL_ "GenSigSuprvResp" BU_SG_REL_ RCRM_LS SG_ 2154471424 RrClosAjarSwAct 1;
BA_REL_ "GenSigSuprvResp" BU_SG_REL_ VPM_LS SG_ 2154471424 RrClosAjarSwAct 1;
BA_REL_ "GenSigSuprvResp" BU_SG_REL_ ARB_LS SG_ 2154471424 RrClosAjarSwAct 1;
BA_REL_ "GenSigSuprvResp" BU_SG_REL_ CSM_LS SG_ 2154471424 RrClosAjarSwAct 1;
BA_REL_ "GenSigSuprvResp" BU_SG_REL_ RadioHead_LS SG_ 2154471424 RrClosAjarSwAct 1;
BA_REL_ "GenSigSuprvResp" BU_SG_REL_ RadioHead_LS SG_ 2154471424 RrClosAjarSwAct 1;
BA_REL_ "GenSigSuprvResp" BU_SG_REL_ ECC_LS SG_ 2154471424 RrClosAjarSwAct 2;
BA_REL_ "GenSigSuprvResp" BU_SG_REL_ PEPS_LS SG_ 2154471424 RrClosAjarSwAct 2;
BA_REL_ "GenSigSuprvResp" BU_SG_REL_ BCM_LS SG_ 2154471424 RrClosAjarSwAct 1;
BA_REL_ "GenSigSuprvResp" BU_SG_REL_ BCM_LS SG_ 2154471424 RrClosAjarSwAct 1;
BA_REL_ "GenSigSuprvResp" BU_SG_REL_ BCM_LS SG_ 2154471424 RrClosAjarSwAct 1;
BA_REL_ "GenSigSuprvResp" BU_SG_REL_ BCM_LS SG_ 2154471424 RrClosAjarSwAct 1;
BA_REL_ "GenSigSuprvResp" BU_SG_REL_ BCM_LS SG_ 2154471424 RrClosAjarSwAct 1;
BA_REL_ "GenSigSuprvResp" BU_SG_REL_ BCM_LS SG_ 2154471424 RrClosAjarSwAct 1;
BA_REL_ "GenSigSuprvResp" BU_SG_REL_ BCM_LS SG_ 2154471424 RrClosAjarSwAct 1;
BA_REL_ "GenSigSuprvResp" BU_SG_REL_ BCM_LS SG_ 2154471424 RrClosAjarSwAct 1;
BA_REL_ "GenSigSuprvResp" BU_SG_REL_ BCM_LS SG_ 2154471424 RrClosAjarSwAct 1;
BA_REL_ "GenSigSuprvResp" BU_SG_REL_ VPM_LS SG_ 2151063552 CamVideoICSDispAct 1;
BA_REL_ "GenSigSuprvResp" BU_SG_REL_ VPM_LS SG_ 2151063552 Frnt360CamSwAct 1;
BA_REL_ "GenSigSuprvResp" BU_SG_REL_ LCM_LS SG_ 2151063552 InftnOprAlwd 1;
BA_REL_ "GenSigSuprvResp" BU_SG_REL_ PTM_LS SG_ 2151063552 InftnOprAlwd 1;
BA_REL_ "GenSigSuprvResp" BU_SG_REL_ BCM_LS SG_ 2151063552 InftnOprAlwd 1;
BA_REL_ "GenSigSuprvResp" BU_SG_REL_ RSC_LS SG_ 2151063552 InftnOprAlwd 1;
BA_REL_ "GenSigSuprvResp" BU_SG_REL_ TCP_LS SG_ 2151063552 InftnOprAlwd 1;
BA_REL_ "GenSigSuprvResp" BU_SG_REL_ OTIM_LS SG_ 2151063552 InftnOprAlwd 1;
BA_REL_ "GenSigSuprvResp" BU_SG_REL_ UHP_Low SG_ 2151063552 InftnOprAlwd 1;
BA_REL_ "GenSigSuprvResp" BU_SG_REL_ ONSTAR_LS SG_ 2151063552 InftnOprAlwd 1;
BA_REL_ "GenSigSuprvResp" BU_SG_REL_ PDIM_LS SG_ 2151063552 InftnOprAlwd 1;
BA_REL_ "GenSigSuprvResp" BU_SG_REL_ AMP_LS SG_ 2151063552 InftnOprAlwd 1;
BA_REL_ "GenSigSuprvResp" BU_SG_REL_ ICS_LS SG_ 2151063552 ValetMdAct 1;
BA_REL_ "GenSigSuprvResp" BU_SG_REL_ LCM_LS SG_ 2151063552 ValetMdAct 1;
BA_REL_ "GenSigSuprvResp" BU_SG_REL_ PTM_LS SG_ 2151063552 ValetMdAct 1;
BA_REL_ "GenSigSuprvResp" BU_SG_REL_ LVMPC_LS SG_ 2151063552 ValetMdAct 1;
BA_REL_ "GenSigSuprvResp" BU_SG_REL_ BCM_LS SG_ 2151063552 ValetMdAct 1;
BA_REL_ "GenSigSuprvResp" BU_SG_REL_ BCM_LS SG_ 2151063552 ValetMdAct 1;
BA_REL_ "GenSigSuprvResp" BU_SG_REL_ BCM_LS SG_ 2151063552 ValetMdAct 1;
BA_REL_ "GenSigSuprvResp" BU_SG_REL_ BCM_LS SG_ 2151063552 ValetMdAct 1;
BA_REL_ "GenSigSuprvResp" BU_SG_REL_ BCM_LS SG_ 2151063552 ValetMdAct 1;
BA_REL_ "GenSigSuprvResp" BU_SG_REL_ BCM_LS SG_ 2151063552 ValetMdAct 1;
BA_REL_ "GenSigSuprvResp" BU_SG_REL_ SBZA_R_LS SG_ 2151284736 PrkAstOprtrDsrdStat_1D0 1;
BA_REL_ "GenSigSuprvResp" BU_SG_REL_ SBZA_L_LS SG_ 2151284736 PrkAstOprtrDsrdStat_1D0 1;
BA_REL_ "GenSigSuprvResp" BU_SG_REL_ IPC_LS SG_ 2151284736 TnDrvPrkAstOffUnbIO 1;
BA_REL_ "GenSigSuprvResp" BU_SG_REL_ IPC_LS SG_ 2151284736 PrkAsstDisablIO 1;
BA_REL_ "GenSigSuprvResp" BU_SG_REL_ V2V_LS SG_ 2151718912 ChmVolSt 1;
BA_REL_ "GenSigSuprvResp" BU_SG_REL_ VPM_LS SG_ 2151718912 ChmAct 1;
BA_REL_ "GenSigSuprvResp" BU_SG_REL_ FCM_LS SG_ 2151718912 ChmAct 1;
BA_REL_ "GenSigSuprvResp" BU_SG_REL_ TCP_LS SG_ 2151718912 ChmAct 1;
BA_REL_ "GenSigSuprvResp" BU_SG_REL_ V2V_LS SG_ 2151718912 ChmAct 1;
BA_REL_ "GenSigSuprvResp" BU_SG_REL_ EOCM_F_LS SG_ 2151718912 ChmAct 1;
BA_REL_ "GenSigSuprvResp" BU_SG_REL_ EOCM_F_LS SG_ 2151718912 ChmAct 1;
BA_REL_ "GenSigSuprvResp" BU_SG_REL_ EOCM_F_LS SG_ 2151718912 ChmAct 1;
BA_REL_ "GenSigSuprvResp" BU_SG_REL_ ONSTAR_LS SG_ 2151718912 ChmAct 1;
BA_REL_ "GenSigSuprvResp" BU_SG_REL_ RadioHead_LS SG_ 2151718912 ChmAct 1;
BA_REL_ "GenSigSuprvResp" BU_SG_REL_ UPA_LS SG_ 2151718912 ChmAct 1;
BA_REL_ "GenSigRxStartValue" BU_SG_REL_ TIM_B_LS SG_ 2151718912 ChmAct "0";
BA_REL_ "GenSigRxStartValue" BU_SG_REL_ TIM_A_LS SG_ 2151718912 ChmAct "0";
BA_REL_ "GenSigRxStartValue" BU_SG_REL_ TIM_LS SG_ 2151718912 ChmAct "0";
BA_REL_ "GenSigSuprvResp" BU_SG_REL_ LCM_LS SG_ 2151718912 ChmAct 1;
BA_REL_ "GenSigSuprvResp" BU_SG_REL_ PTM_LS SG_ 2151718912 ChmAct 1;
BA_REL_ "GenSigSuprvResp" BU_SG_REL_ BCM_LS SG_ 2151718912 ChmAct 1;
BA_REL_ "GenSigSuprvResp" BU_SG_REL_ BCM_LS SG_ 2151718912 ChmAct 1;
BA_REL_ "GenSigRxStartValue" BU_SG_REL_ SDM_LS SG_ 2151718912 ChmAct "0";
BA_REL_ "GenSigSuprvResp" BU_SG_REL_ SDM_LS SG_ 2151718912 ChmAct 1;
BA_REL_ "GenSigSuprvResp" BU_SG_REL_ APA_LS SG_ 2151718912 ChmAct 1;
BA_REL_ "GenSigSuprvResp" BU_SG_REL_ APA_LS SG_ 2151718912 ChmAct 1;
BA_REL_ "GenSigSuprvResp" BU_SG_REL_ BCM_LS SG_ 2155479040 DrvStyPerfMdCsStReq 1;
BA_REL_ "GenSigSuprvResp" BU_SG_REL_ BCM_LS SG_ 2155479040 PsngStPerfMdCsStReq 1;
BA_REL_ "GenSigSuprvResp" BU_SG_REL_ BCM_LS SG_ 2155479040 DrvrStPerfMdCsStReq 1;
BA_REL_ "GenSigSuprvResp" BU_SG_REL_ BCM_LS SG_ 2155479040 ACCPerfMdCsStReq 1;
BA_REL_ "GenSigSuprvResp" BU_SG_REL_ BCM_LS SG_ 2155479040 PedFrndlyAlrtCsStReq 1;
BA_REL_ "GenSigSuprvResp" BU_SG_REL_ VPM_LS SG_ 2155479040 RstrCustFctrDef 1;
BA_REL_ "GenSigSuprvResp" BU_SG_REL_ VIS2_LS SG_ 2155479040 RstrCustFctrDef 1;
BA_REL_ "GenSigSuprvResp" BU_SG_REL_ FCM_LS SG_ 2155479040 RstrCustFctrDef 1;
BA_REL_ "GenSigSuprvResp" BU_SG_REL_ HBSM_LS SG_ 2155479040 RstrCustFctrDef 1;
BA_REL_ "GenSigSuprvResp" BU_SG_REL_ BSM_LS SG_ 2155479040 RstrCustFctrDef 1;
BA_REL_ "GenSigSuprvResp" BU_SG_REL_ VICM_LS SG_ 2155479040 RstrCustFctrDef 1;
BA_REL_ "GenSigSuprvResp" BU_SG_REL_ BCM_LS SG_ 2155421696 PsvEntAprchDrctn 1;
BA_REL_ "GenSigSuprvResp" BU_SG_REL_ BCM_LS SG_ 2155421696 PsvEntApprchDtcd 1;
BA_REL_ "GenSigSuprvResp" BU_SG_REL_ BCM_LS SG_ 2155421696 PsvEntApprchCnfgReq 1;
BA_REL_ "GenSigSuprvResp" BU_SG_REL_ BCM_LS SG_ 2155421696 PsvEntChlng 1;
BA_REL_ "GenSigSuprvResp" BU_SG_REL_ V2V_LS SG_ 2155413504 TireLRIPrs 1;
BA_REL_ "GenSigSuprvResp" BU_SG_REL_ TCP_LS SG_ 2155413504 TireLRIPrs 1;
BA_REL_ "GenSigSuprvResp" BU_SG_REL_ ONSTAR_LS SG_ 2155413504 TireLRIPrs 1;
BA_REL_ "GenSigSuprvResp" BU_SG_REL_ IPC_LS SG_ 2155413504 TireLRIPrs 1;
BA_REL_ "GenSigSuprvResp" BU_SG_REL_ V2V_LS SG_ 2155413504 TireRRIPrs 1;
BA_REL_ "GenSigSuprvResp" BU_SG_REL_ TCP_LS SG_ 2155413504 TireRRIPrs 1;
BA_REL_ "GenSigSuprvResp" BU_SG_REL_ ONSTAR_LS SG_ 2155413504 TireRRIPrs 1;
BA_REL_ "GenSigSuprvResp" BU_SG_REL_ IPC_LS SG_ 2155413504 TireRRIPrs 1;
BA_REL_ "GenSigSuprvResp" BU_SG_REL_ PEPS_LS SG_ 2155413504 PsvLckngReqd 1;
BA_REL_ "GenSigSuprvResp" BU_SG_REL_ PEPS_LS SG_ 2155413504 PsvApprchVehId 1;
VAL_ 2150277120 PsngSysLongV 1 "Invalid" 0 "Valid" ;
VAL_ 2150277120 PsngSysLatV 1 "Invalid" 0 "Valid" ;
VAL_ 2150285312 PsngSysHdingV 1 "Invalid" 0 "Valid" ;
VAL_ 2150285312 PsngSysElvtnV 1 "Invalid" 0 "Valid" ;
VAL_ 2150285312 PsngSysCalcSpdV 1 "Invalid" 0 "Valid" ;
VAL_ 2150285312 PsngSysDilPrcsV 1 "Invalid" 0 "Valid" ;
VAL_ 2151890944 TICR_Ind1 0 "Red" 1 "Green" 2 "Yellow" ;
VAL_ 2151890944 TICR_Ind1Req 0 "Off" 1 "Continuous Indication" 2 "Flashing" 3 "Count" ;
VAL_ 2151251968 TICS_Ind1V 1 "Invalid" 0 "Valid" ;
VAL_ 2151251968 TICS_Ind1 0 "Red" 1 "Green" 2 "Yellow" ;
VAL_ 2151251968 TICS_Ind1Stat 0 "Off" 1 "Continuous Indication" 2 "Flashing" 3 "Count" ;
VAL_ 2155495424 RmStrHtdStEnRq 1 "Enable Heated Seat" 0 "Disable Heated Seat" ;
VAL_ 2155495424 RmStrCldStEnReq 1 "Enable Cooled Seat" 0 "Disable Cooled Seat" ;
VAL_ 2149990400 ElcTransRngRq 7 "Unused and Reserved" 6 "Manual Range" 5 "Low Range" 4 "Drive" 3 "Neutral" 2 "Reverse" 1 "Park" 0 "No Request" ;
VAL_ 2149990400 TrlrBrkngVDA 1 "VirtualDeviceAvailable" 0 "VirtualDeviceUnavailable" ;
VAL_ 2149990400 SecAxlOperMod 3 "Active All Wheel Drive (High)" 2 "4 Wheel Drive Low Locked" 1 "4 Wheel Drive High Locked" 0 "2 Wheel Drive High" 15 "Neutral" 14 "Unknown" 7 "2 Wheel Drive Low" 6 "Active All Wheel Drive (Low)" 5 "4 Wheel Drive Low Open" 4 "4 Wheel Drive High Open" ;
VAL_ 2149990400 MotStBltUnblIO 1 "true" 0 "false" ;
VAL_ 2149990400 MotStBltFldIO 1 "true" 0 "false" ;
VAL_ 2149990400 TransNtrlCntrlMdStat 3 "Exiting Neutral Control" 2 "Neutral Control Active" 1 "Entering Neutral Control" 0 "Neutral Control Not Active" ;
VAL_ 2149990400 TrlrWiringFltIO 1 "true" 0 "false" ;
VAL_ 2149990400 TrlrCnctdIO 1 "true" 0 "false" ;
VAL_ 2149990400 TrlrBrkngGainSetIO 1 "true" 0 "false" ;
VAL_ 2149990400 SrvTrlrBrkngSysIO 1 "true" 0 "false" ;
VAL_ 2149990400 ChkTrlrIO 1 "true" 0 "false" ;
VAL_ 2149990400 ScndryAxleVDA 1 "VirtualDeviceAvailable" 0 "VirtualDeviceUnavailable" ;
VAL_ 2149990400 TrlrHtchSwAtv_ITBC 1 "true" 0 "false" ;
VAL_ 2149990400 AdvHlmpsVDA 1 "VirtualDeviceAvailable" 0 "VirtualDeviceUnavailable" ;
VAL_ 2149990400 ABSIO 1 "true" 0 "false" ;
VAL_ 2149990400 ACCHdwayStngIO 1 "true" 0 "false" ;
VAL_ 2149990400 StpOnBrkToRelPBIndOn 1 "true" 0 "false" ;
VAL_ 2149990400 SADmpVDA 1 "VirtualDeviceAvailable" 0 "VirtualDeviceUnavailable" ;
VAL_ 2149990400 ACCDrvrSeltdSpdIO 1 "true" 0 "false" ;
VAL_ 2149990400 TreInfMonSysRstPrfmd 1 "true" 0 "false" ;
VAL_ 2149990400 DrvThrtlOvrdIO 1 "true" 0 "false" ;
VAL_ 2155380736 ServFuelSysTrnsfrPmpIO 1 "true" 0 "false" ;
VAL_ 2155380736 ACCmCltEngd 1 "true" 0 "false" ;
VAL_ 2155380736 StrAsstRdcdLvl3IO 1 "true" 0 "false" ;
VAL_ 2155380736 StrAsstRdcdLvl2IO 1 "true" 0 "false" ;
VAL_ 2155380736 StrngAsstRdcdIO 1 "true" 0 "false" ;
VAL_ 2155380736 ARSFlrIO 1 "true" 0 "false" ;
VAL_ 2155380736 PTExPrtclFltrWrn2IO 1 "true" 0 "false" ;
VAL_ 2155380736 EngOilHotIO 1 "true" 0 "false" ;
VAL_ 2155380736 RrLevVDA 1 "VirtualDeviceAvailable" 0 "VirtualDeviceUnavailable" ;
VAL_ 2155380736 EngWtrInFlIO 1 "true" 0 "false" ;
VAL_ 2155380736 AdvFrntLghtSysIndRq 7 "Indication 7" 6 "Indication 6" 5 "Indication 5" 4 "Indication 4" 3 "Indication 3" 2 "Indication 2" 1 "Indication 1" 0 "No Indication" ;
VAL_ 2155380736 PTExPrtclFltrWrnIO 1 "true" 0 "false" ;
VAL_ 2155380736 AirCndOffIO 1 "true" 0 "false" ;
VAL_ 2155380736 HdLtLvlFlrIO 1 "true" 0 "false" ;
VAL_ 2155380736 PwrStrIO 1 "true" 0 "false" ;
VAL_ 2155380736 EngHt_StpEngIO 1 "true" 0 "false" ;
VAL_ 2155380736 CkFlFilrCapIO 1 "true" 0 "false" ;
VAL_ 2155380736 RdcdPwrIO 1 "true" 0 "false" ;
VAL_ 2155380736 EngOilPrsLwIO 1 "true" 0 "false" ;
VAL_ 2155380736 EngOilLvlLwIO 1 "true" 0 "false" ;
VAL_ 2155380736 EngOilChngIO 1 "true" 0 "false" ;
VAL_ 2155380736 EngHotFuelEnrchmntIO 1 "true" 0 "false" ;
VAL_ 2155380736 DslGlwPlgIO 1 "true" 0 "false" ;
VAL_ 2155380736 SrvLevSysIO 1 "true" 0 "false" ;
VAL_ 2155380736 VehOvrLdIndOn 1 "true" 0 "false" ;
VAL_ 2150498304 OAT_PT_EstV 1 "Invalid" 0 "Valid" ;
VAL_ 2150498304 EngOilPrsV 1 "Invalid" 0 "Valid" ;
VAL_ 2150498304 EngOilTmpV 1 "Invalid" 0 "Valid" ;
VAL_ 2150498304 TrnOilTmpV 1 "Invalid" 0 "Valid" ;
VAL_ 2150498304 EngCltTmpV 1 "Invalid" 0 "Valid" ;
VAL_ 2150498304 EngIntAirTmpV 1 "Invalid" 0 "Valid" ;
VAL_ 2150498304 OAT_PT_EstM 1 "Use Data" 0 "Don't Use Data" ;
VAL_ 2150498304 BarPrsAbsV 1 "Invalid" 0 "Valid" ;
VAL_ 2151047168 HdUpDspAnmtStat 0 "Animation Not Available" 1 "Animation Available" 2 "Welcome Active" 3 "CRANK Active" 4 "RUN Active" 5 "Good Bye Active" ;
VAL_ 2151047168 HUDActv 1 "true" 0 "false" ;
VAL_ 2154225664 RLDrHndleSwAtv 1 "true" 0 "false" ;
VAL_ 2154225664 RRDrHndleSwAtv 1 "true" 0 "false" ;
VAL_ 2154225664 RCHndleSwAtv 1 "true" 0 "false" ;
VAL_ 2154225664 PasDrHndleSwAtv 1 "true" 0 "false" ;
VAL_ 2154225664 DrvDrHndleSwAtv 1 "true" 0 "false" ;
VAL_ 2149900288 BTTethrngPrngReq 0 "No Action" 1 "Available" 2 "Bluetooth Address" 3 "Pairing PIN" 4 "Unused and Reserved" 5 "Delete Pairing Information" 6 "Enter Bluetooth Pairing Mode" ;
VAL_ 2149900288 EnhSrvAudAlRq 3 "Alarm" 2 "Chirp" 1 "Off" 0 "No Action" ;
VAL_ 2149900288 EnhSrvVisAlRq 3 "Repeated Flash" 2 "Single Flash" 1 "Off" 0 "No Action" ;
VAL_ 2149900288 EnhSrvRmStrtRq 2 "Engine Requested On" 1 "Engine Requested Off" 0 "No Activation" ;
VAL_ 2149900288 EnhSrvRClsRlsRq 1 "Release" 0 "No Action" ;
VAL_ 2149900288 EnhSrvLckRq 5 "Undeadbolt All" 4 "Deadbolt All" 3 "Unlock All" 2 "Unlock Driver Door" 1 "Lock All" 0 "No Action" ;
VAL_ 2154708992 ASS2AudSrcStatCode 5 "Producing Audio" 4 "Producing Silence" 3 "Reserved" 2 "Audio Not Available" 1 "Audio Available" 0 "Device Present" ;
VAL_ 2154708992 ASS2AudSrcChType 4 "Mono Emergency" 3 "Mixed" 2 "Stereo" 1 "Mono" 0 "No Action" ;
VAL_ 2154708992 ASS2AudSrcType 28 "Phone" 24 "Sat. Digital Audio Receiver System" 20 "Digital Audio Broadcast" 16 "Remote CD Changer" 12 "Remote Digital Video Disk" 8 "Auxiliary Device" 1 "Television Tuner" ;
VAL_ 2158985216 ODDMO_ReqType 0 "Subscribe: FU sends DynData back and then on change) " 1 "Unsubscribe: cancel previous Subscribe" ;
VAL_ 2158985216 ODDMO_DispMID 128 "Reserved" 64 "Reserved" 32 "OTIM" 16 "RearDisplayTwo" 8 "RearDisplayOne" 4 "AuxIP" 2 "CenterStack" 1 "IPC" ;
VAL_ 2158985216 ODDMO_DataID2Vld 1 "true" 0 "false" ;
VAL_ 2158985216 ODDMO_DataID3Vld 1 "true" 0 "false" ;
VAL_ 2158985216 ODDMO_DataID4Vld 1 "true" 0 "false" ;
VAL_ 2158985216 ODDMO_DataID5Vld 1 "true" 0 "false" ;
VAL_ 2154471424 RrClsrSnwLdIO 1 "true" 0 "false" ;
VAL_ 2154471424 RrClosAjarSwAct 1 "true" 0 "false" ;
VAL_ 2158796800 ODII_ODIInd55 1 "true" 0 "false" ;
VAL_ 2158796800 ODII_ODIInd54 1 "true" 0 "false" ;
VAL_ 2158796800 ODII_ODIInd53 1 "true" 0 "false" ;
VAL_ 2158796800 ODII_ODIInd52 1 "true" 0 "false" ;
VAL_ 2158796800 ODII_ODIInd51 1 "true" 0 "false" ;
VAL_ 2158796800 ODII_ODIInd50 1 "true" 0 "false" ;
VAL_ 2158796800 ODII_ODIInd27 1 "true" 0 "false" ;
VAL_ 2158796800 ODII_ODIInd26 1 "true" 0 "false" ;
VAL_ 2158796800 ODII_ODIInd25 1 "true" 0 "false" ;
VAL_ 2158796800 ODII_ODIInd24 1 "true" 0 "false" ;
VAL_ 2158796800 ODII_ODIInd23 1 "true" 0 "false" ;
VAL_ 2158796800 ODII_ODIInd22 1 "true" 0 "false" ;
VAL_ 2158796800 ODII_ODIInd21 1 "true" 0 "false" ;
VAL_ 2158796800 ODII_ODIInd20 1 "true" 0 "false" ;
VAL_ 2158796800 ODII_ODIInd19 1 "true" 0 "false" ;
VAL_ 2158796800 ODII_ODIInd18 1 "true" 0 "false" ;
VAL_ 2158796800 ODII_ODIInd17 1 "true" 0 "false" ;
VAL_ 2158796800 ODII_ODIInd16 1 "true" 0 "false" ;
VAL_ 2158796800 ODII_ODIInd15 1 "true" 0 "false" ;
VAL_ 2158796800 ODII_ODIInd14 1 "true" 0 "false" ;
VAL_ 2158796800 ODII_ODIInd13 1 "true" 0 "false" ;
VAL_ 2158796800 ODII_ODIInd12 1 "true" 0 "false" ;
VAL_ 2158796800 ODII_ODIInd11 1 "true" 0 "false" ;
VAL_ 2158796800 ODII_ODIInd10 1 "true" 0 "false" ;
VAL_ 2158796800 ODII_ODIInd9 1 "true" 0 "false" ;
VAL_ 2158796800 ODII_ODIInd8 1 "true" 0 "false" ;
VAL_ 2158796800 ODII_ODIInd7 1 "true" 0 "false" ;
VAL_ 2158796800 ODII_ODIInd6 1 "true" 0 "false" ;
VAL_ 2158796800 ODII_ODIInd5 1 "true" 0 "false" ;
VAL_ 2158796800 ODII_ODIInd4 1 "true" 0 "false" ;
VAL_ 2158796800 ODII_ODIInd3 1 "true" 0 "false" ;
VAL_ 2158796800 ODII_ODIInd2 1 "true" 0 "false" ;
VAL_ 2158796800 ODII_ODIInd1 1 "true" 0 "false" ;
VAL_ 2158796800 ODII_ODIInd56 1 "true" 0 "false" ;
VAL_ 2158796800 ODII_ODIInd49 1 "true" 0 "false" ;
VAL_ 2158796800 ODII_ODIInd48 1 "true" 0 "false" ;
VAL_ 2158796800 ODII_ODIInd47 1 "true" 0 "false" ;
VAL_ 2158796800 ODII_ODIInd46 1 "true" 0 "false" ;
VAL_ 2158796800 ODII_ODIInd45 1 "true" 0 "false" ;
VAL_ 2158796800 ODII_ODIInd44 1 "true" 0 "false" ;
VAL_ 2158796800 ODII_ODIInd43 1 "true" 0 "false" ;
VAL_ 2158796800 ODII_ODIInd42 1 "true" 0 "false" ;
VAL_ 2158796800 ODII_ODIInd41 1 "true" 0 "false" ;
VAL_ 2158796800 ODII_ODIInd40 1 "true" 0 "false" ;
VAL_ 2158796800 ODII_ODIInd39 1 "true" 0 "false" ;
VAL_ 2158796800 ODII_ODIInd38 1 "true" 0 "false" ;
VAL_ 2158796800 ODII_ODIInd37 1 "true" 0 "false" ;
VAL_ 2158796800 ODII_ODIInd36 1 "true" 0 "false" ;
VAL_ 2158796800 ODII_ODIInd35 1 "true" 0 "false" ;
VAL_ 2158796800 ODII_ODIInd34 1 "true" 0 "false" ;
VAL_ 2158796800 ODII_ODIInd33 1 "true" 0 "false" ;
VAL_ 2158796800 ODII_ODIInd32 1 "true" 0 "false" ;
VAL_ 2158796800 ODII_ODIInd31 1 "true" 0 "false" ;
VAL_ 2158796800 ODII_ODIInd30 1 "true" 0 "false" ;
VAL_ 2158796800 ODII_ODIInd29 1 "true" 0 "false" ;
VAL_ 2158796800 ODII_ODIInd28 1 "true" 0 "false" ;
VAL_ 2153955328 EngOffTmExtRngV 1 "Invalid" 0 "Valid" ;
VAL_ 2153955328 ElpsdTimeCntRstOcc 1 "true" 0 "false" ;
VAL_ 2151063552 TrfRdsdInfCsStReq 7 "Reserved5" 6 "Reserved4" 5 "Reserved3" 4 "Reserved2" 3 "Reserved1" 2 "On" 1 "Off" 0 "No Action" ;
VAL_ 2151063552 IntrStopAlrtCsSetReq 7 "Reserved4" 6 "Reserved3" 5 "Reserved2" 4 "Reserved1" 3 "Alert and Brake" 2 "Alert " 1 "Off" 0 "No Action" ;
VAL_ 2151063552 CntdVehBrAltCsStReq 7 "Reserved5" 6 "Reserved4" 5 "Reserved3" 4 "Reserved2" 3 "Reserved1" 2 "On" 1 "Off" 0 "No Action" ;
VAL_ 2151063552 ICSTS_TchPrxmty 2 "Touch" 1 "Near" 0 "Far" ;
VAL_ 2151063552 TrgdVidRecSwAct 1 "true" 0 "false" ;
VAL_ 2151063552 RrPedDetCstStReq 7 "Reserved3" 6 "Reserved2" 5 "Reserved1" 4 "Alert and Brake" 3 "Alert" 2 "On" 1 "Off" 0 "No Action" ;
VAL_ 2151063552 CamVideoICSDispAct 1 "true" 0 "false" ;
VAL_ 2151063552 Frnt360CamSwAct 1 "true" 0 "false" ;
VAL_ 2151063552 InftnOprAlwd 1 "true" 0 "false" ;
VAL_ 2151063552 ValetMdAct 1 "true" 0 "false" ;
VAL_ 2157985792 FobProgEvntRqd 1 "true" 0 "false" ;
VAL_ 2151284736 PrkAstOprtrDsrdStat_1D0 0 "Off" 1 "On" 2 "Tow Bar Attached" ;
VAL_ 2151284736 TnDrvPrkAstOffUnbIO 1 "true" 0 "false" ;
VAL_ 2151284736 PrkAstFld 1 "true" 0 "false" ;
VAL_ 2151284736 PrkAstSnsDistrbdIO 1 "true" 0 "false" ;
VAL_ 2151284736 PrkAsstDisablIO 1 "true" 0 "false" ;
VAL_ 2151284736 PrkAstSnrsBlk 1 "true" 0 "false" ;
VAL_ 2151284736 PrkAsstClnPrkAstIO 1 "true" 0 "false" ;
VAL_ 2151718912 ChmVolSt 0 "Normal" 1 "Loud" ;
VAL_ 2151718912 ChmAct 1 "true" 0 "false" ;
VAL_ 2155479040 EleRngEstAdjCstStReq 3 "Unused and Reserved 1" 2 "On" 1 "Off" 0 "No Action" ;
VAL_ 2155479040 WPRSCstStReq 7 "Unused and Reserved 5" 6 "Unused and Reserved 4" 5 "Unused and Reserved 3" 4 "Unused and Reserved 2" 3 "Unused and Reserved 1" 2 "On" 1 "Off" 0 "No Action" ;
VAL_ 2155479040 DrvStyPerfMdCsStReq 7 "Performance Mode 7" 6 "Performance Mode 6" 5 "Performance Mode 5" 4 "Performance Mode 4" 3 "Performance Mode 3" 2 "Performance Mode 2" 1 "Performance Mode 1" 0 "No Action" ;
VAL_ 2155479040 PsngStPerfMdCsStReq 7 "Auto" 6 "Performance Mode 6" 5 "Performance Mode 5" 4 "Performance Mode 4" 3 "Performance Mode 3" 2 "Performance Mode 2" 1 "Performance Mode 1" 0 "No Action" ;
VAL_ 2155479040 DrvrStPerfMdCsStReq 7 "Auto" 6 "Performance Mode 6" 5 "Performance Mode 5" 4 "Performance Mode 4" 3 "Performance Mode 3" 2 "Performance Mode 2" 1 "Performance Mode 1" 0 "No Action" ;
VAL_ 2155479040 ACCPerfMdCsStReq 7 "Auto" 6 "Performance Mode 6" 5 "Performance Mode 5" 4 "Performance Mode 4" 3 "Performance Mode 3" 2 "Performance Mode 2" 1 "Performance Mode 1" 0 "No Action" ;
VAL_ 2155479040 ElvtdIdlCstStReq 0 "No Action" 1 "Off" 2 "On" ;
VAL_ 2155479040 PedFrndlyAlrtCsStReq 0 "No Action" 1 "Off" 2 "On" ;
VAL_ 2155479040 SndPerfMdCsStRq 0 "No Action" 1 "Performance Mode 1" 2 "Performance Mode 2" 3 "Performance Mode 3" 4 "Performance Mode 4" 5 "Performance Mode 5" 6 "Performance Mode 6" 7 "Auto" ;
VAL_ 2155479040 DispPerfMdCsStRq 0 "No Action" 1 "Performance Mode 1" 2 "Performance Mode 2" 3 "Performance Mode 3" 4 "Performance Mode 4" 5 "Performance Mode 5" 6 "Performance Mode 6" 7 "Auto" ;
VAL_ 2155479040 SusCustStngReq 7 "Auto" 6 "Performance Mode 6" 5 "Performance Mode 5" 4 "Performance Mode 4" 3 "Performance Mode 3" 2 "Performance Mode 2" 1 "Performance Mode 1" 0 "No Action" ;
VAL_ 2155479040 StrCustStngReq 7 "Auto" 6 "Performance Mode 6" 5 "Performance Mode 5" 4 "Performance Mode 4" 3 "Performance Mode 3" 2 "Performance Mode 2" 1 "Performance Mode 1" 0 "No Action" ;
VAL_ 2155479040 RstrCustFctrDef 1 "Restore Defaults" 0 "No Action" ;
VAL_ 2155479040 DrvlnCustStngReq 7 "Auto" 6 "Performance Mode 6" 5 "Performance Mode 5" 4 "Performance Mode 4" 3 "Performance Mode 3" 2 "Performance Mode 2" 1 "Performance Mode 1" 0 "No Action" ;
VAL_ 2151383040 TreInfMonSysRstReq 1 "true" 0 "false" ;
VAL_ 2155421696 PsvEntAprchDrctn 0 "Driver" 1 "Co-Driver" 2 "Front" 3 "Rear" ;
VAL_ 2155421696 PsvEntApprchDtcd 1 "true" 0 "false" ;
VAL_ 2155421696 PsvEntApprchCnfgReq 0 "Level 0" 1 "Level 1" 2 "Level 2" 3 "Level 3" 4 "Level 4" 5 "Level 5" 6 "Level 6" 7 "Level 7" ;
VAL_ 2155421696 ServKylsStSysIO 1 "true" 0 "false" ;
VAL_ 2155413504 TireLRIPrsV 1 "Invalid" 0 "Valid" ;
VAL_ 2155413504 TireLRIPrsStat 5 "High" 4 "Low Extended Mobility" 3 "Low" 2 "Low Service Now" 1 "Nominal" 0 "Unknown" ;
VAL_ 2155413504 TireRRIPrsV 1 "Invalid" 0 "Valid" ;
VAL_ 2155413504 TireRRIPrsStat 5 "High" 4 "Low Extended Mobility" 3 "Low" 2 "Low Service Now" 1 "Nominal" 0 "Unknown" ;
VAL_ 2155413504 PsvLckngReqd 1 "true" 0 "false" ;
VAL_ 2155413504 DrvrDrKeyCylUlkSwAct 1 "true" 0 "false" ;
VAL_ 2155413504 DrvrDrKeyCylUlkSwActV 1 "Invalid" 0 "Valid" ;
VAL_ 2159026176 ODD_InvldData 1 "true" 0 "false" ;
VAL_ 2159026176 ODD_DataType 21 "Bitmap" 20 "DecimalShort" 19 "HoursOfDay" 18 "Character" 17 "Fuel Consumption Inverted" 16 "Fuel Consumption" 15 "Pressure" 14 "Temperature" 13 "Volume" 12 "DistanceShort" 11 "DistanceLong" 10 "BitmapId" 9 "TextId" 8 "Pictogram" 7 "List " 6 "Date" 5 "Time " 4 "Decimal" 3 "EnumerationValue" 2 "Integer" 1 "String" 0 "Speed" ;
SIG_GROUP_ 2151890944 TlmtcsIndCntrlReq 1 : TICR_Ind1FlshRtOn TICR_Ind1FlshRtOff TICR_Ind1Cnt TICR_Ind1 TICR_Ind1Req;
SIG_GROUP_ 2151251968 TlmtcsIndCntrlStat 1 : TICS_Ind1V TICS_Ind1FlshRtOnSt TICS_Ind1FlshRtOffSt TICS_Ind1 TICS_Ind1Stat;
SIG_GROUP_ 2159001600 ODIEnmDynData_IPC 1 : ODIEDDIPC_FUCID ODIEDDIPC_Data18Value ODIEDDIPC_Data17Value ODIEDDIPC_Data16Value ODIEDDIPC_Data15Value ODIEDDIPC_Data14Value ODIEDDIPC_Data13Value ODIEDDIPC_Data12Value ODIEDDIPC_Data11Value ODIEDDIPC_Data10Value ODIEDDIPC_Data9Value ODIEDDIPC_Data8Value ODIEDDIPC_Data7Value ODIEDDIPC_Data6Value ODIEDDIPC_Data5Value ODIEDDIPC_Data4Value ODIEDDIPC_Data3Value ODIEDDIPC_Data2Value ODIEDDIPC_Data1Value;
SIG_GROUP_ 2158993408 ODIEnmDynData_CenterStack 1 : ODIEDDCS_FUCID ODIEDDCS_Data9Value ODIEDDCS_Data8Value ODIEDDCS_Data7Value ODIEDDCS_Data6Value ODIEDDCS_Data5Value ODIEDDCS_Data4Value ODIEDDCS_Data3Value ODIEDDCS_Data2Value ODIEDDCS_Data18Value ODIEDDCS_Data17Value ODIEDDCS_Data16Value ODIEDDCS_Data15Value ODIEDDCS_Data14Value ODIEDDCS_Data13Value ODIEDDCS_Data12Value ODIEDDCS_Data11Value ODIEDDCS_Data10Value ODIEDDCS_Data1Value;
SIG_GROUP_ 2154708992 AudSrcStat2 1 : ASS2AudSrcStatCode ASS2AudSrcChType ASS2AudSrcType;
SIG_GROUP_ 2158985216 ODIDynDataMltRq_OTIM 1 : ODDMO_ReqType ODDMO_FUCID ODDMO_DispMID ODDMO_DataID2Vld ODDMO_DataID2 ODDMO_DataID3Vld ODDMO_DataID3 ODDMO_DataID1 ODDMO_DataID4Vld ODDMO_DataID4 ODDMO_DataID5Vld ODDMO_DataID5;
SIG_GROUP_ 2158796800 ODIInd 1 : ODII_ODIInd55 ODII_ODIInd54 ODII_ODIInd53 ODII_ODIInd52 ODII_ODIInd51 ODII_ODIInd50 ODII_ODIInd27 ODII_ODIInd26 ODII_ODIInd25 ODII_ODIInd24 ODII_ODIInd23 ODII_ODIInd22 ODII_ODIInd21 ODII_ODIInd20 ODII_ODIInd19 ODII_ODIInd18 ODII_ODIInd17 ODII_ODIInd16 ODII_ODIInd15 ODII_ODIInd14 ODII_ODIInd13 ODII_ODIInd12 ODII_ODIInd11 ODII_ODIInd10 ODII_ODIInd9 ODII_ODIInd8 ODII_ODIInd7 ODII_ODIInd6 ODII_ODIInd5 ODII_ODIInd4 ODII_ODIInd3 ODII_ODIInd2 ODII_ODIInd1 ODII_ODIInd56 ODII_ODIInd49 ODII_ODIInd48 ODII_ODIInd47 ODII_ODIInd46 ODII_ODIInd45 ODII_ODIInd44 ODII_ODIInd43 ODII_ODIInd42 ODII_ODIInd41 ODII_ODIInd40 ODII_ODIInd39 ODII_ODIInd38 ODII_ODIInd37 ODII_ODIInd36 ODII_ODIInd35 ODII_ODIInd34 ODII_ODIInd33 ODII_ODIInd32 ODII_ODIInd31 ODII_ODIInd30 ODII_ODIInd29 ODII_ODIInd28 ODII_FUCID;
SIG_GROUP_ 2158755840 ODIEvntPkt 1 : ODIE_MultiFrRetCh ODIE_FUCID ODIE_EvID;
SIG_GROUP_ 2151063552 ICSTchStat 1 : ICSTS_Y1TchCrdnt ICSTS_X1TchCrdnt ICSTS_TchPrxmty;
SIG_GROUP_ 2159026176 ODIDynData 1 : ODD_InvldData ODD_FUCID ODD_DataVal ODD_DataType ODD_DataId;
